VERSION ""

NS_ :

BS_:

BU_: Turbocharger OnBoardDataLogger OffBoardDiagnosticTool2 OffBoardDiagnosticTool1 FileServer ParkingBrakeController SeatControl2 FanDriveController SteeringColumnUnit CommunicationUnitRadio CommunicationUnitSatellite CommunicationUnitCellular PropulsionBatteryCharger ChassisController2 ChassisController1 EngineValveControl AuxiliaryHeater2 AuxiliaryHeater1 ClutchUnit RampControl InformationSystem1 SuspensionSystemController2 OilSensor VehicleDynamicStability ExhaustEmissionController TransmissionDisplay2 TransmissionDisplay1 ClimateControl2 WaterPumpController RearAxleSteeringController LightingOperatorControl SeatController1 IgnitionController2 IgnitionController1 TirePressureController CabController2 CabController1 PneumaticSystemController SuspensionSystemController1 HydraulicPumpController EnduranceBrakingSystem RetarderExhaustEngine2 OnBoardDiagnosticUnit HeadwayController RetarderExhaustEngine1 CabDisplay1 ManagementComputer VirtualTerminal OffVehicleGateway PowerTakeOffFront HitchControl AuxiliaryValveControl BodyController TractorTrailerBridge1 StarterSystem ElectricalSystem VehicleSecurity VehicleNavigation AerodynamicControl ElectricalChargingSystem ClimateControl1 TripRecorder InstrumentCluster SuspensionDriveAxle2 SuspensionDriveAxle1 SuspensionSteerAxle SteeringController FuelSystem CruiseControl RetarderDriveline RetarderEngine BrakesDriveAxle2 BrakesDriveAxle1 BrakesSystemController BrakesSteerAxle AxleDrive2 AxleDrive1 AxleSteering PowerTakeOff ShiftConsoleSecondary ShiftConsolePrimary Transmission2 Transmission1 Engine2 Engine1

BO_ 2561212158 DISP1: 8 Vector__XXX
 SG_ TextDisplayIndex : 16|8@1+ (1,0) [0|250] "" Vector__XXX
 SG_ TextDisplayInstructions : 0|4@1+ (1,0) [0|15] "" Vector__XXX

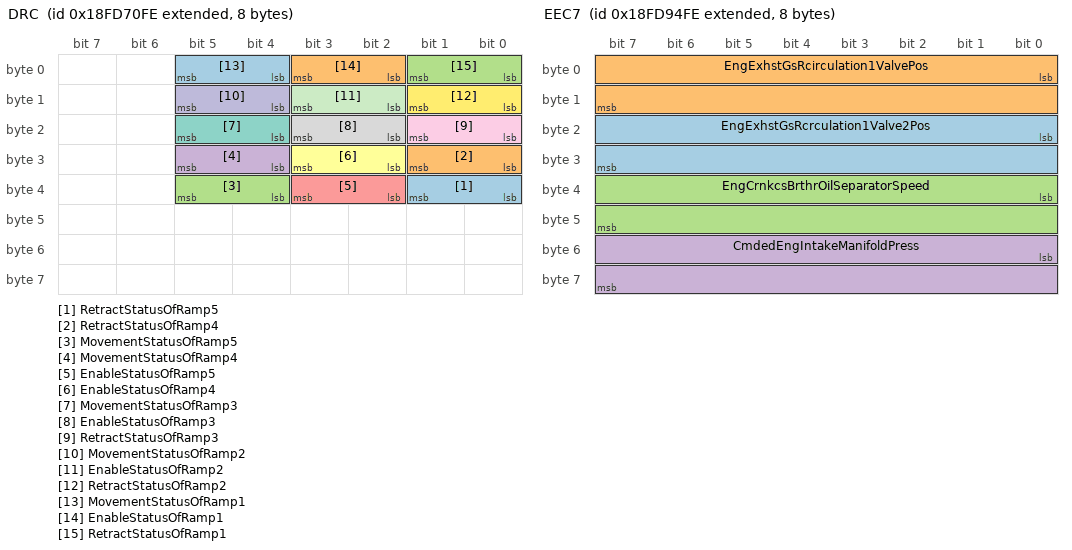
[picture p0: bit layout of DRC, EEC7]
BO_ 2566746366 DRC: 8 Vector__XXX
 SG_ RetractStatusOfRamp5 : 32|2@1+ (1,0) [0|3] "" Vector__XXX
 SG_ RetractStatusOfRamp4 : 24|2@1+ (1,0) [0|3] "" Vector__XXX
 SG_ MovementStatusOfRamp5 : 36|2@1+ (1,0) [0|3] "" Vector__XXX
 SG_ MovementStatusOfRamp4 : 28|2@1+ (1,0) [0|3] "" Vector__XXX
 SG_ EnableStatusOfRamp5 : 34|2@1+ (1,0) [0|3] "" Vector__XXX
 SG_ EnableStatusOfRamp4 : 26|2@1+ (1,0) [0|3] "" Vector__XXX
 SG_ MovementStatusOfRamp3 : 20|2@1+ (1,0) [0|3] "" Vector__XXX
 SG_ EnableStatusOfRamp3 : 18|2@1+ (1,0) [0|3] "" Vector__XXX
 SG_ RetractStatusOfRamp3 : 16|2@1+ (1,0) [0|3] "" Vector__XXX
 SG_ MovementStatusOfRamp2 : 12|2@1+ (1,0) [0|3] "" Vector__XXX
 SG_ EnableStatusOfRamp2 : 10|2@1+ (1,0) [0|3] "" Vector__XXX
 SG_ RetractStatusOfRamp2 : 8|2@1+ (1,0) [0|3] "" Vector__XXX
 SG_ MovementStatusOfRamp1 : 4|2@1+ (1,0) [0|3] "" Vector__XXX
 SG_ EnableStatusOfRamp1 : 2|2@1+ (1,0) [0|3] "" Vector__XXX
 SG_ RetractStatusOfRamp1 : 0|2@1+ (1,0) [0|3] "" Vector__XXX

BO_ 2566750206 EC2: 8 Vector__XXX
 SG_ MaxCrankAttemptsPerStartAttempt : 0|8@1+ (1,0) [0|250] "" Vector__XXX

BO_ 2566755582 EEC7: 8 Vector__XXX
 SG_ EngExhstGsRcrculation1Valve2Pos : 16|16@1+ (0.0025,0) [0|160.6375] "%" Vector__XXX
 SG_ EngExhstGsRcirculation1ValvePos : 0|16@1+ (0.0025,0) [0|160.6375] "%" Vector__XXX
 SG_ EngCrnkcsBrthrOilSeparatorSpeed : 32|16@1+ (1,0) [0|64255] "rpm" Vector__XXX
 SG_ CmdedEngIntakeManifoldPress : 48|16@1+ (0.125,0) [0|8031.875] "kPa" Vector__XXX

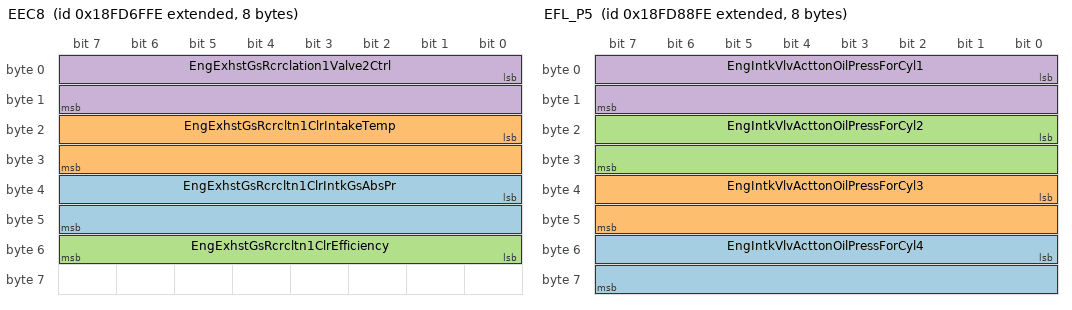
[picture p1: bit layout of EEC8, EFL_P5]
BO_ 2566746110 EEC8: 8 Vector__XXX
 SG_ EngExhstGsRcrcltn1ClrIntkGsAbsPr : 32|16@1+ (0.5,0) [0|32127.5] "kPa" Vector__XXX
 SG_ EngExhstGsRcrcltn1ClrIntakeTemp : 16|16@1+ (0.03125,-273) [-273|1734.96875] "deg C" Vector__XXX
 SG_ EngExhstGsRcrcltn1ClrEfficiency : 48|8@1+ (0.4,0) [0|100] "%" Vector__XXX
 SG_ EngExhstGsRcrclation1Valve2Ctrl : 0|16@1+ (0.0025,0) [0|160.6375] "%" Vector__XXX

BO_ 2566752510 EFL_P5: 8 Vector__XXX
 SG_ EngIntkVlvActtonOilPressForCyl4 : 48|16@1+ (0.1,0) [0|6425.5] "kPa" Vector__XXX
 SG_ EngIntkVlvActtonOilPressForCyl3 : 32|16@1+ (0.1,0) [0|6425.5] "kPa" Vector__XXX
 SG_ EngIntkVlvActtonOilPressForCyl2 : 16|16@1+ (0.1,0) [0|6425.5] "kPa" Vector__XXX
 SG_ EngIntkVlvActtonOilPressForCyl1 : 0|16@1+ (0.1,0) [0|6425.5] "kPa" Vector__XXX

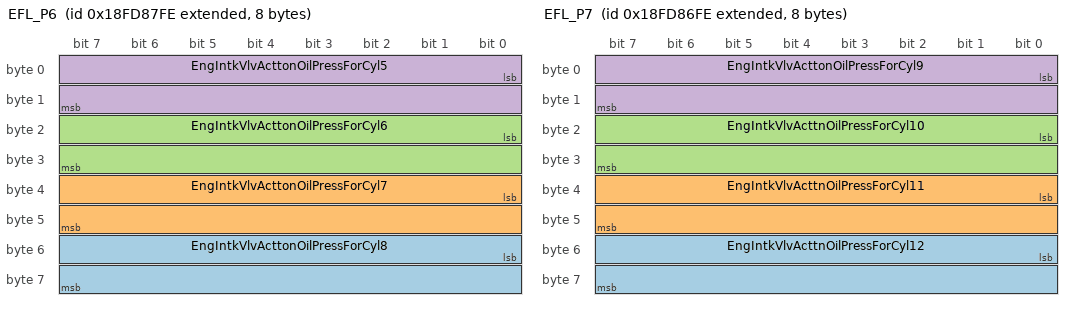
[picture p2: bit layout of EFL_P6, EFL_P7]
BO_ 2566752254 EFL_P6: 8 Vector__XXX
 SG_ EngIntkVlvActtonOilPressForCyl8 : 48|16@1+ (0.1,0) [0|6425.5] "kPa" Vector__XXX
 SG_ EngIntkVlvActtonOilPressForCyl7 : 32|16@1+ (0.1,0) [0|6425.5] "kPa" Vector__XXX
 SG_ EngIntkVlvActtonOilPressForCyl6 : 16|16@1+ (0.1,0) [0|6425.5] "kPa" Vector__XXX
 SG_ EngIntkVlvActtonOilPressForCyl5 : 0|16@1+ (0.1,0) [0|6425.5] "kPa" Vector__XXX

BO_ 2566751998 EFL_P7: 8 Vector__XXX
 SG_ EngIntkVlvActtnOilPressForCyl12 : 48|16@1+ (0.1,0) [0|6425.5] "kPa" Vector__XXX
 SG_ EngIntkVlvActtnOilPressForCyl11 : 32|16@1+ (0.1,0) [0|6425.5] "kPa" Vector__XXX
 SG_ EngIntkVlvActtnOilPressForCyl10 : 16|16@1+ (0.1,0) [0|6425.5] "kPa" Vector__XXX
 SG_ EngIntkVlvActtonOilPressForCyl9 : 0|16@1+ (0.1,0) [0|6425.5] "kPa" Vector__XXX

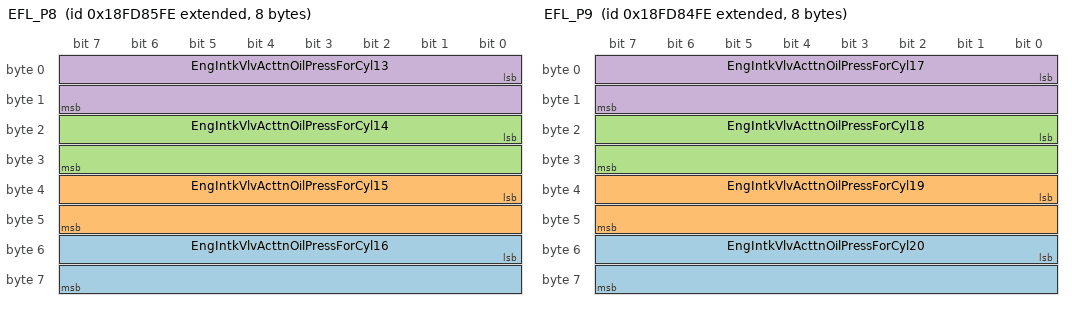
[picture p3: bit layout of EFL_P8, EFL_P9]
BO_ 2566751742 EFL_P8: 8 Vector__XXX
 SG_ EngIntkVlvActtnOilPressForCyl16 : 48|16@1+ (0.1,0) [0|6425.5] "kPa" Vector__XXX
 SG_ EngIntkVlvActtnOilPressForCyl15 : 32|16@1+ (0.1,0) [0|6425.5] "kPa" Vector__XXX
 SG_ EngIntkVlvActtnOilPressForCyl14 : 16|16@1+ (0.1,0) [0|6425.5] "kPa" Vector__XXX
 SG_ EngIntkVlvActtnOilPressForCyl13 : 0|16@1+ (0.1,0) [0|6425.5] "kPa" Vector__XXX

BO_ 2566751486 EFL_P9: 8 Vector__XXX
 SG_ EngIntkVlvActtnOilPressForCyl20 : 48|16@1+ (0.1,0) [0|6425.5] "kPa" Vector__XXX
 SG_ EngIntkVlvActtnOilPressForCyl19 : 32|16@1+ (0.1,0) [0|6425.5] "kPa" Vector__XXX
 SG_ EngIntkVlvActtnOilPressForCyl18 : 16|16@1+ (0.1,0) [0|6425.5] "kPa" Vector__XXX
 SG_ EngIntkVlvActtnOilPressForCyl17 : 0|16@1+ (0.1,0) [0|6425.5] "kPa" Vector__XXX

BO_ 2499641854 EGRBV: 8 Vector__XXX
 SG_ EGR1CoolerBypassActuatorPostion : 0|8@1+ (0.4,0) [0|100] "%" Vector__XXX

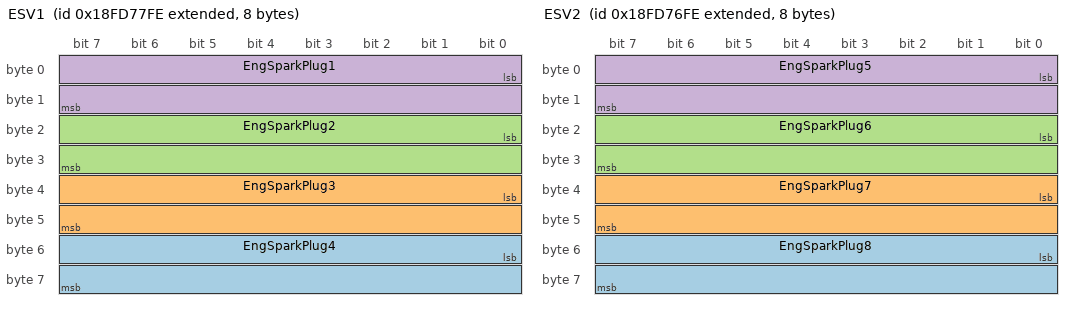
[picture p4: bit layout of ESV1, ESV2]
BO_ 2566748158 ESV1: 8 Vector__XXX
 SG_ EngSparkPlug4 : 48|16@1+ (1,0) [0|64255] "Volts" Vector__XXX
 SG_ EngSparkPlug3 : 32|16@1+ (1,0) [0|64255] "Volts" Vector__XXX
 SG_ EngSparkPlug2 : 16|16@1+ (1,0) [0|64255] "Volts" Vector__XXX
 SG_ EngSparkPlug1 : 0|16@1+ (1,0) [0|64255] "Volts" Vector__XXX

BO_ 2566747902 ESV2: 8 Vector__XXX
 SG_ EngSparkPlug8 : 48|16@1+ (1,0) [0|64255] "Volts" Vector__XXX
 SG_ EngSparkPlug7 : 32|16@1+ (1,0) [0|64255] "Volts" Vector__XXX
 SG_ EngSparkPlug6 : 16|16@1+ (1,0) [0|64255] "Volts" Vector__XXX
 SG_ EngSparkPlug5 : 0|16@1+ (1,0) [0|64255] "Volts" Vector__XXX

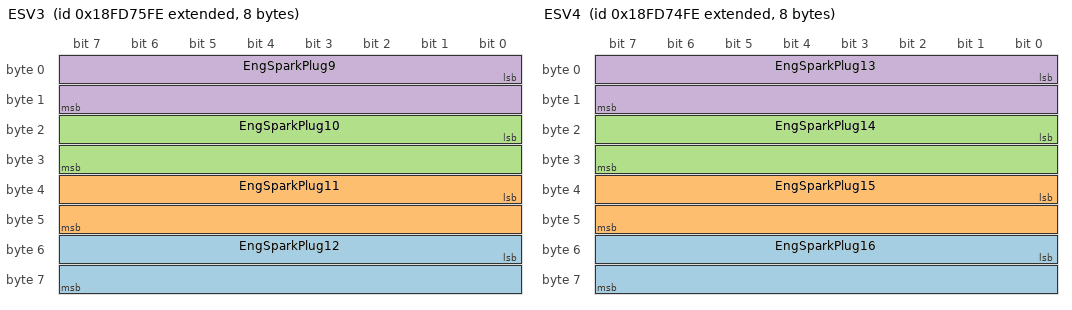
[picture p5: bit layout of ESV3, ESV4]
BO_ 2566747646 ESV3: 8 Vector__XXX
 SG_ EngSparkPlug12 : 48|16@1+ (1,0) [0|64255] "Volts" Vector__XXX
 SG_ EngSparkPlug11 : 32|16@1+ (1,0) [0|64255] "Volts" Vector__XXX
 SG_ EngSparkPlug10 : 16|16@1+ (1,0) [0|64255] "Volts" Vector__XXX
 SG_ EngSparkPlug9 : 0|16@1+ (1,0) [0|64255] "Volts" Vector__XXX

BO_ 2566747390 ESV4: 8 Vector__XXX
 SG_ EngSparkPlug16 : 48|16@1+ (1,0) [0|64255] "Volts" Vector__XXX
 SG_ EngSparkPlug15 : 32|16@1+ (1,0) [0|64255] "Volts" Vector__XXX
 SG_ EngSparkPlug14 : 16|16@1+ (1,0) [0|64255] "Volts" Vector__XXX
 SG_ EngSparkPlug13 : 0|16@1+ (1,0) [0|64255] "Volts" Vector__XXX

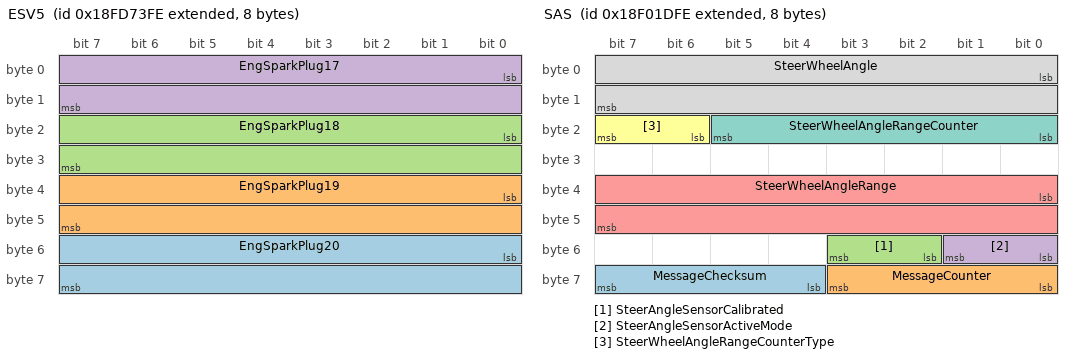
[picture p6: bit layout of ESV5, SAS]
BO_ 2566747134 ESV5: 8 Vector__XXX
 SG_ EngSparkPlug20 : 48|16@1+ (1,0) [0|64255] "Volts" Vector__XXX
 SG_ EngSparkPlug19 : 32|16@1+ (1,0) [0|64255] "Volts" Vector__XXX
 SG_ EngSparkPlug18 : 16|16@1+ (1,0) [0|64255] "Volts" Vector__XXX
 SG_ EngSparkPlug17 : 0|16@1+ (1,0) [0|64255] "Volts" Vector__XXX

BO_ 2566746878 ESV6: 8 Vector__XXX
 SG_ EngSparkPlug24 : 48|16@1+ (1,0) [0|64255] "Volts" Vector__XXX
 SG_ EngSparkPlug23 : 32|16@1+ (1,0) [0|64255] "Volts" Vector__XXX
 SG_ EngSparkPlug22 : 16|16@1+ (1,0) [0|64255] "Volts" Vector__XXX
 SG_ EngSparkPlug21 : 0|16@1+ (1,0) [0|64255] "Volts" Vector__XXX

BO_ 2561277694 FLIC: 8 Vector__XXX
 SG_ LaneDepartureWarningEnableCmd : 0|2@1+ (1,0) [0|3] "" Vector__XXX

BO_ 2633861886 J2012: 8 Vector__XXX
 SG_ J2012DTCOccurrenceCount : 49|7@1+ (1,0) [0|127] "" Vector__XXX
 SG_ J2012DTCStatus : 48|1@1+ (1,0) [0|1] "" Vector__XXX
 SG_ NumberOfJ2012DTCs : 0|8@1+ (1,0) [0|250] "" Vector__XXX

BO_ 2565873150 SAS: 8 Vector__XXX
 SG_ MessageChecksum : 60|4@1+ (1,0) [0|15] "" Vector__XXX
 SG_ MessageCounter : 56|4@1+ (1,0) [0|15] "" Vector__XXX
 SG_ SteerAngleSensorCalibrated : 50|2@1+ (1,0) [0|3] "" Vector__XXX
 SG_ SteerAngleSensorActiveMode : 48|2@1+ (1,0) [0|3] "" Vector__XXX
 SG_ SteerWheelAngleRange : 32|16@1+ (0.0009765625,-31.374) [-31.374|31.374] "rad" Vector__XXX
 SG_ SteerWheelAngleRangeCounterType : 22|2@1+ (1,0) [0|3] "" Vector__XXX
 SG_ SteerWheelAngleRangeCounter : 16|6@1+ (1,-32) [-32|29] "ranges" Vector__XXX
 SG_ SteerWheelAngle : 0|16@1+ (0.0009765625,-31.374) [-31.374|31.374] "rad" Vector__XXX

BO_ 2566745854 SCR1: 8 Vector__XXX
 SG_ Aftrtrtmnt1SCRCtlystCnvrsnEffcnc : 32|8@1+ (0.4,0) [0|100] "%" Vector__XXX
 SG_ Aftrtrtmnt1SCRCmddCtlystRgntCnsm : 16|16@1+ (0.05,0) [0|3212.75] "L/h" Vector__XXX
 SG_ Aftrtrtmnt1SCRAvrgCtlystRgntCnsm : 0|16@1+ (0.05,0) [0|3212.75] "L/h" Vector__XXX
 SG_ Aftrtrtmnt1DslExhstFldTnkLwLvlIn : 40|16@1+ (1,0) [0|64255] "km" Vector__XXX

BO_ 2566751230 TCI: 8 Vector__XXX
 SG_ TransferCaseStatus : 0|3@1+ (1,0) [0|7] "" Vector__XXX

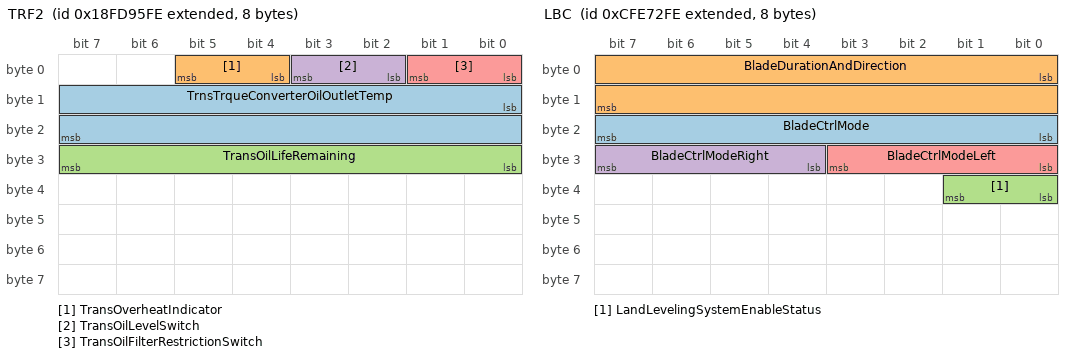
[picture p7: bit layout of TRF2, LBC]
BO_ 2566755838 TRF2: 8 Vector__XXX
 SG_ TrnsTrqueConverterOilOutletTemp : 8|16@1+ (0.03125,-273) [-273|1734.96875] "deg C" Vector__XXX
 SG_ TransOverheatIndicator : 4|2@1+ (1,0) [0|3] "" Vector__XXX
 SG_ TransOilLifeRemaining : 24|8@1+ (0.4,0) [0|100] "%" Vector__XXX
 SG_ TransOilLevelSwitch : 2|2@1+ (1,0) [0|3] "" Vector__XXX
 SG_ TransOilFilterRestrictionSwitch : 0|2@1+ (1,0) [0|3] "" Vector__XXX

BO_ 2566752766 VDS2: 8 Vector__XXX
 SG_ VehicleRoll : 0|16@1+ (0.0078125,-200) [-200|301.99] "deg" Vector__XXX

BO_ 2633938942 LF: 10 Vector__XXX
 SG_ TotalEngCruiseTime : 48|32@1+ (0.05,0) [0|210554060.75] "hr" Vector__XXX
 SG_ TotalDriveAverageLoadFactor : 40|8@1+ (0.4,0) [0|100] "%" Vector__XXX
 SG_ TripDriveAverageLoadFactor : 32|8@1+ (0.4,0) [0|100] "%" Vector__XXX
 SG_ TripAverageEngSpeed : 16|16@1+ (0.125,0) [0|8031.875] "rpm" Vector__XXX
 SG_ TripMaxEngSpeed : 0|16@1+ (0.125,0) [0|8031.875] "rpm" Vector__XXX

BO_ 2566799614 LD: 8 Vector__XXX
 SG_ ImplementRearWorkLight : 62|2@1+ (1,0) [0|3] "" Vector__XXX
 SG_ ImplementLeftForwardWorkLight : 60|2@1+ (1,0) [0|3] "" Vector__XXX
 SG_ ImplementRightForwardWorkLight : 58|2@1+ (1,0) [0|3] "" Vector__XXX
 SG_ ImplementLeftFacingWorkLight : 54|2@1+ (1,0) [0|3] "" Vector__XXX
 SG_ ImplementRightFacingWorkLight : 52|2@1+ (1,0) [0|3] "" Vector__XXX
 SG_ ImplementOEMOption1Light : 50|2@1+ (1,0) [0|3] "" Vector__XXX
 SG_ ImplementOEMOption2Light : 48|2@1+ (1,0) [0|3] "" Vector__XXX
 SG_ TrctrFrontHighMountedWorkLights : 46|2@1+ (1,0) [0|3] "" Vector__XXX
 SG_ TrctorFrontLowMountedWorkLights : 44|2@1+ (1,0) [0|3] "" Vector__XXX
 SG_ TrctorSideHighMountedWorkLights : 42|2@1+ (1,0) [0|3] "" Vector__XXX
 SG_ TractorSideLowMountedWorkLights : 40|2@1+ (1,0) [0|3] "" Vector__XXX
 SG_ TrctorRearHighMountedWorkLights : 38|2@1+ (1,0) [0|3] "" Vector__XXX
 SG_ TractorRearLowMountedWorkLights : 36|2@1+ (1,0) [0|3] "" Vector__XXX
 SG_ TrctrUndersideMountedWorkLights : 34|2@1+ (1,0) [0|3] "" Vector__XXX
 SG_ RearFogLights : 32|2@1+ (1,0) [0|3] "" Vector__XXX
 SG_ TractorMarkerLight : 30|2@1+ (1,0) [0|3] "" Vector__XXX
 SG_ ImplementMarkerLight : 28|2@1+ (1,0) [0|3] "" Vector__XXX
 SG_ TractorClearanceLight : 26|2@1+ (1,0) [0|3] "" Vector__XXX
 SG_ ImplementClearanceLight : 24|2@1+ (1,0) [0|3] "" Vector__XXX
 SG_ LeftStopLight : 22|2@1+ (1,0) [0|3] "" Vector__XXX
 SG_ RightStopLight : 20|2@1+ (1,0) [0|3] "" Vector__XXX
 SG_ CenterStopLight : 18|2@1+ (1,0) [0|3] "" Vector__XXX
 SG_ BackUpLightAndAlarmHorn : 16|2@1+ (1,0) [0|3] "" Vector__XXX
 SG_ LeftTurnSignalLights : 14|2@1+ (1,0) [0|3] "" Vector__XXX
 SG_ RightTurnSignalLights : 12|2@1+ (1,0) [0|3] "" Vector__XXX
 SG_ RotatingBeaconLight : 10|2@1+ (1,0) [0|3] "" Vector__XXX
 SG_ TractorFrontFogLights : 8|2@1+ (1,0) [0|3] "" Vector__XXX
 SG_ HighBeamHeadLightData : 6|2@1+ (1,0) [0|3] "" Vector__XXX
 SG_ LowBeamHeadLightData : 4|2@1+ (1,0) [0|3] "" Vector__XXX
 SG_ AltBeamHeadLightData : 2|2@1+ (1,0) [0|3] "" Vector__XXX
 SG_ RunningLight : 0|2@1+ (1,0) [0|3] "" Vector__XXX

BO_ 2365473278 LC: 8 Vector__XXX
 SG_ ImplementRearWorkLightCmd : 62|2@1+ (1,0) [0|3] "" Vector__XXX
 SG_ ImplmentLeftForwardWorkLightCmd : 60|2@1+ (1,0) [0|3] "" Vector__XXX
 SG_ ImplmntRightForwardWorkLightCmd : 58|2@1+ (1,0) [0|3] "" Vector__XXX
 SG_ LightingDataRqCmd : 56|2@1+ (1,0) [0|3] "" Vector__XXX
 SG_ ImplementLeftFacingWorkLightCmd : 54|2@1+ (1,0) [0|3] "" Vector__XXX
 SG_ ImplmentRightFacingWorkLightCmd : 52|2@1+ (1,0) [0|3] "" Vector__XXX
 SG_ ImplementOEMOption1LightCmd : 50|2@1+ (1,0) [0|3] "" Vector__XXX
 SG_ ImplementOEMOption2LightCmd : 48|2@1+ (1,0) [0|3] "" Vector__XXX
 SG_ TrctrFrntHghMuntedWorkLightsCmd : 46|2@1+ (1,0) [0|3] "" Vector__XXX
 SG_ TrctrFrntLwMountedWorkLightsCmd : 44|2@1+ (1,0) [0|3] "" Vector__XXX
 SG_ TrctrSdHighMountedWorkLightsCmd : 42|2@1+ (1,0) [0|3] "" Vector__XXX
 SG_ TrctrSdeLowMountedWorkLightsCmd : 40|2@1+ (1,0) [0|3] "" Vector__XXX
 SG_ TrctrRrHighMountedWorkLightsCmd : 38|2@1+ (1,0) [0|3] "" Vector__XXX
 SG_ TrctrRarLowMountedWorkLightsCmd : 36|2@1+ (1,0) [0|3] "" Vector__XXX
 SG_ TrctrUndrsdMountedWorkLightsCmd : 34|2@1+ (1,0) [0|3] "" Vector__XXX
 SG_ RearFogLightCmd : 32|2@1+ (1,0) [0|3] "" Vector__XXX
 SG_ TractorMarkerLightCmd : 30|2@1+ (1,0) [0|3] "" Vector__XXX
 SG_ ImplementMarkerLightCmd : 28|2@1+ (1,0) [0|3] "" Vector__XXX
 SG_ TractorClearanceLightCmd : 26|2@1+ (1,0) [0|3] "" Vector__XXX
 SG_ ImplementClearanceLightCmd : 24|2@1+ (1,0) [0|3] "" Vector__XXX
 SG_ LeftStopLightCmd : 22|2@1+ (1,0) [0|3] "" Vector__XXX
 SG_ RightStopLightCmd : 20|2@1+ (1,0) [0|3] "" Vector__XXX
 SG_ CenterStopLightCmd : 18|2@1+ (1,0) [0|3] "" Vector__XXX
 SG_ BackUpLightAndAlarmHornCmd : 16|2@1+ (1,0) [0|3] "" Vector__XXX
 SG_ LeftTurnSignalLightsCmd : 14|2@1+ (1,0) [0|3] "" Vector__XXX
 SG_ RightTurnSignalLightsCmd : 12|2@1+ (1,0) [0|3] "" Vector__XXX
 SG_ RotatingBeaconLightCmd : 10|2@1+ (1,0) [0|3] "" Vector__XXX
 SG_ TractorFrontFogLightsCmd : 8|2@1+ (1,0) [0|3] "" Vector__XXX
 SG_ HighBeamHeadLightCmd : 6|2@1+ (1,0) [0|3] "" Vector__XXX
 SG_ LowBeamHeadLightCmd : 4|2@1+ (1,0) [0|3] "" Vector__XXX
 SG_ AltBeamHeadLightCmd : 2|2@1+ (1,0) [0|3] "" Vector__XXX
 SG_ RunningLightCmd : 0|2@1+ (1,0) [0|3] "" Vector__XXX

BO_ 2365485822 LBC: 8 Vector__XXX
 SG_ BladeCtrlMode : 16|8@1+ (1,0) [0|255] "" Vector__XXX
 SG_ BladeDurationAndDirection : 0|16@1+ (0.1,-3276.8) [-3276.8|3148.7] "sec" Vector__XXX
 SG_ LandLevelingSystemEnableStatus : 32|2@1+ (1,0) [0|3] "" Vector__XXX
 SG_ BladeCtrlModeRight : 28|4@1+ (1,0) [0|15] "" Vector__XXX
 SG_ BladeCtrlModeLeft : 24|4@1+ (1,0) [0|15] "" Vector__XXX

BO_ 2633926654 IT6: 8 Vector__XXX
 SG_ EngActualIgntTiming : 48|16@1+ (0.0078125,-200) [-200|301.99] "deg" Vector__XXX
 SG_ EngDesiredIgntTiming3 : 32|16@1+ (0.0078125,-200) [-200|301.99] "deg" Vector__XXX
 SG_ EngDesiredIgntTiming2 : 16|16@1+ (0.0078125,-200) [-200|301.99] "deg" Vector__XXX
 SG_ EngDesiredIgntTiming1 : 0|16@1+ (0.0078125,-200) [-200|301.99] "deg" Vector__XXX

BO_ 2633926398 IT5: 8 Vector__XXX
 SG_ EngCyl20IgntTiming : 48|16@1+ (0.0078125,-200) [-200|301.99] "deg" Vector__XXX
 SG_ EngCyl19IgntTiming : 32|16@1+ (0.0078125,-200) [-200|301.99] "deg" Vector__XXX
 SG_ EngCyl18IgntTiming : 16|16@1+ (0.0078125,-200) [-200|301.99] "deg" Vector__XXX
 SG_ EngCyl17IgntTiming : 0|16@1+ (0.0078125,-200) [-200|301.99] "deg" Vector__XXX

BO_ 2633926142 IT4: 8 Vector__XXX
 SG_ EngCyl16IgntTiming : 48|16@1+ (0.0078125,-200) [-200|301.99] "deg" Vector__XXX
 SG_ EngCyl15IgntTiming : 32|16@1+ (0.0078125,-200) [-200|301.99] "deg" Vector__XXX
 SG_ EngCyl14IgntTiming : 16|16@1+ (0.0078125,-200) [-200|301.99] "deg" Vector__XXX
 SG_ EngCyl13IgntTiming : 0|16@1+ (0.0078125,-200) [-200|301.99] "deg" Vector__XXX

BO_ 2633925886 IT3: 8 Vector__XXX
 SG_ EngCyl12IgntTiming : 48|16@1+ (0.0078125,-200) [-200|301.99] "deg" Vector__XXX
 SG_ EngCyl11IgntTiming : 32|16@1+ (0.0078125,-200) [-200|301.99] "deg" Vector__XXX
 SG_ EngCyl10IgntTiming : 16|16@1+ (0.0078125,-200) [-200|301.99] "deg" Vector__XXX
 SG_ EngCyl9IgntTiming : 0|16@1+ (0.0078125,-200) [-200|301.99] "deg" Vector__XXX

BO_ 2633925630 IT2: 8 Vector__XXX
 SG_ EngCyl8IgntTiming : 48|16@1+ (0.0078125,-200) [-200|301.99] "deg" Vector__XXX
 SG_ EngCyl7IgntTiming : 32|16@1+ (0.0078125,-200) [-200|301.99] "deg" Vector__XXX
 SG_ EngCyl6IgntTiming : 16|16@1+ (0.0078125,-200) [-200|301.99] "deg" Vector__XXX
 SG_ EngCyl5IgntTiming : 0|16@1+ (0.0078125,-200) [-200|301.99] "deg" Vector__XXX

BO_ 2633925374 IT1: 8 Vector__XXX
 SG_ EngCyl4IgntTiming : 48|16@1+ (0.0078125,-200) [-200|301.99] "deg" Vector__XXX
 SG_ EngCyl3IgntTiming : 32|16@1+ (0.0078125,-200) [-200|301.99] "deg" Vector__XXX
 SG_ EngCyl2IgntTiming : 16|16@1+ (0.0078125,-200) [-200|301.99] "deg" Vector__XXX
 SG_ EngCyl1IgntTiming : 0|16@1+ (0.0078125,-200) [-200|301.99] "deg" Vector__XXX

BO_ 2633927422 ISO3: 8 Vector__XXX
 SG_ EngCyl20IgntTransSecondOutput : 24|8@1+ (1,-125) [-125|125] "%" Vector__XXX
 SG_ EngCyl19IgntTransSecondOutput : 16|8@1+ (1,-125) [-125|125] "%" Vector__XXX
 SG_ EngCyl18IgntTransSecondOutput : 8|8@1+ (1,-125) [-125|125] "%" Vector__XXX
 SG_ EngCyl17IgntTransSecondOutput : 0|8@1+ (1,-125) [-125|125] "%" Vector__XXX

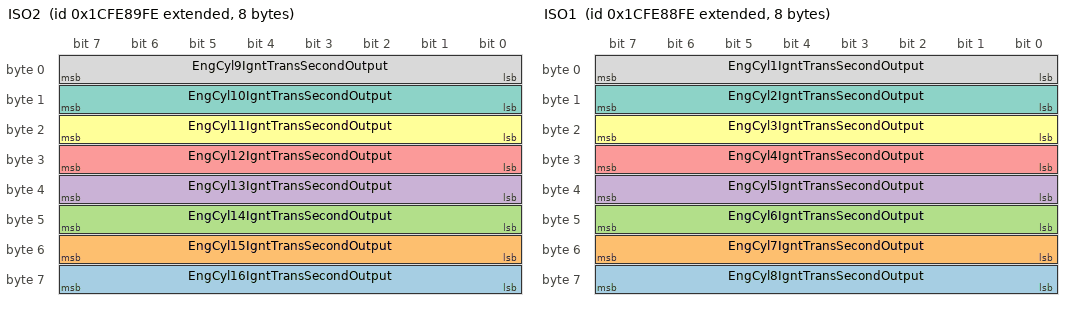
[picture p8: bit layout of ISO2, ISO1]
BO_ 2633927166 ISO2: 8 Vector__XXX
 SG_ EngCyl16IgntTransSecondOutput : 56|8@1+ (1,-125) [-125|125] "%" Vector__XXX
 SG_ EngCyl15IgntTransSecondOutput : 48|8@1+ (1,-125) [-125|125] "%" Vector__XXX
 SG_ EngCyl14IgntTransSecondOutput : 40|8@1+ (1,-125) [-125|125] "%" Vector__XXX
 SG_ EngCyl13IgntTransSecondOutput : 32|8@1+ (1,-125) [-125|125] "%" Vector__XXX
 SG_ EngCyl12IgntTransSecondOutput : 24|8@1+ (1,-125) [-125|125] "%" Vector__XXX
 SG_ EngCyl11IgntTransSecondOutput : 16|8@1+ (1,-125) [-125|125] "%" Vector__XXX
 SG_ EngCyl10IgntTransSecondOutput : 8|8@1+ (1,-125) [-125|125] "%" Vector__XXX
 SG_ EngCyl9IgntTransSecondOutput : 0|8@1+ (1,-125) [-125|125] "%" Vector__XXX

BO_ 2633926910 ISO1: 8 Vector__XXX
 SG_ EngCyl8IgntTransSecondOutput : 56|8@1+ (1,-125) [-125|125] "%" Vector__XXX
 SG_ EngCyl7IgntTransSecondOutput : 48|8@1+ (1,-125) [-125|125] "%" Vector__XXX
 SG_ EngCyl6IgntTransSecondOutput : 40|8@1+ (1,-125) [-125|125] "%" Vector__XXX
 SG_ EngCyl5IgntTransSecondOutput : 32|8@1+ (1,-125) [-125|125] "%" Vector__XXX
 SG_ EngCyl4IgntTransSecondOutput : 24|8@1+ (1,-125) [-125|125] "%" Vector__XXX
 SG_ EngCyl3IgntTransSecondOutput : 16|8@1+ (1,-125) [-125|125] "%" Vector__XXX
 SG_ EngCyl2IgntTransSecondOutput : 8|8@1+ (1,-125) [-125|125] "%" Vector__XXX
 SG_ EngCyl1IgntTransSecondOutput : 0|8@1+ (1,-125) [-125|125] "%" Vector__XXX

BO_ 2566768894 ISCS: 8 Vector__XXX
 SG_ EngOprtrPrmryIntrmdtSpdSlctStte : 0|4@1+ (1,0) [0|15] "" Vector__XXX

BO_ 2566769406 ISC: 8 Vector__XXX
 SG_ EngOprtrPrmryIntrmdtSpeedSelect : 0|4@1+ (1,0) [0|15] "" Vector__XXX

BO_ 2566839550 IO: 8 Vector__XXX
 SG_ EngTotalIdleHours : 32|32@1+ (0.05,0) [0|210554060.75] "hr" Vector__XXX
 SG_ EngTotalIdleFuelUsed : 0|32@1+ (0.5,0) [0|2105540607.5] "L" Vector__XXX

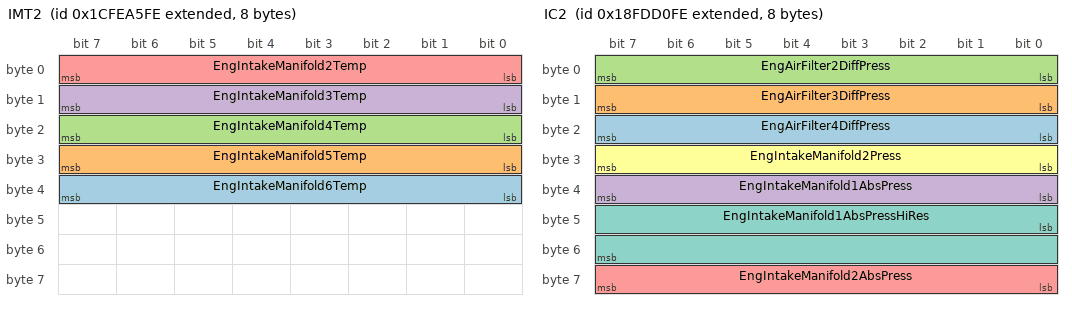
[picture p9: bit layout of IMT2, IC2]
BO_ 2633934334 IMT2: 8 Vector__XXX
 SG_ EngIntakeManifold6Temp : 32|8@1+ (1,-40) [-40|210] "deg C" Vector__XXX
 SG_ EngIntakeManifold5Temp : 24|8@1+ (1,-40) [-40|210] "deg C" Vector__XXX
 SG_ EngIntakeManifold4Temp : 16|8@1+ (1,-40) [-40|210] "deg C" Vector__XXX
 SG_ EngIntakeManifold3Temp : 8|8@1+ (1,-40) [-40|210] "deg C" Vector__XXX
 SG_ EngIntakeManifold2Temp : 0|8@1+ (1,-40) [-40|210] "deg C" Vector__XXX

BO_ 2566825726 IMT1: 8 Vector__XXX
 SG_ EngTurbo4BoostPress : 48|16@1+ (0.125,0) [0|8031.875] "kPa" Vector__XXX
 SG_ EngTurbo3BoostPress : 32|16@1+ (0.125,0) [0|8031.875] "kPa" Vector__XXX
 SG_ EngTurbo2BoostPress : 16|16@1+ (0.125,0) [0|8031.875] "kPa" Vector__XXX
 SG_ EngTurbo1BoostPress : 0|16@1+ (0.125,0) [0|8031.875] "kPa" Vector__XXX

BO_ 2566770942 IC2: 8 Vector__XXX
 SG_ EngAirFilter4DiffPress : 16|8@1+ (0.05,0) [0|12.5] "kPa" Vector__XXX
 SG_ EngAirFilter3DiffPress : 8|8@1+ (0.05,0) [0|12.5] "kPa" Vector__XXX
 SG_ EngAirFilter2DiffPress : 0|8@1+ (0.05,0) [0|12.5] "kPa" Vector__XXX
 SG_ EngIntakeManifold1AbsPress : 32|8@1+ (0.1,0) [0|25.5] "kPa" Vector__XXX
 SG_ EngIntakeManifold2AbsPress : 56|8@1+ (2,0) [0|500] "kPa" Vector__XXX
 SG_ EngIntakeManifold2Press : 24|8@1+ (2,0) [0|500] "kPa" Vector__XXX
 SG_ EngIntakeManifold1AbsPressHiRes : 40|16@1+ (0.1,0) [0|6425.5] "kPa" Vector__XXX

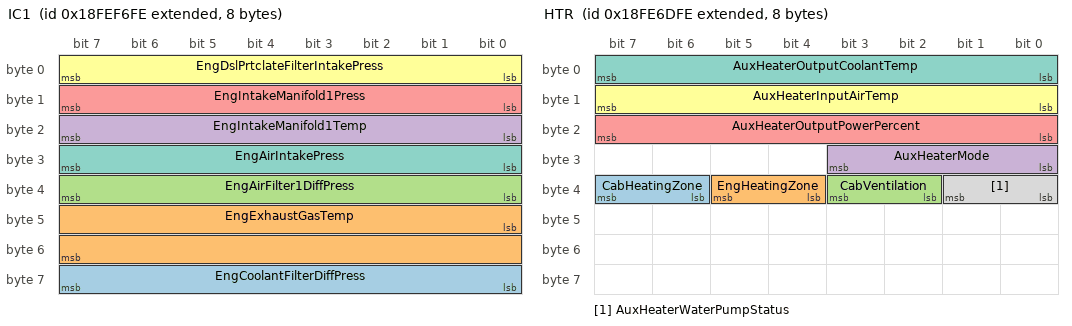
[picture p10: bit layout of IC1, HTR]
BO_ 2566846206 IC1: 8 Vector__XXX
 SG_ EngCoolantFilterDiffPress : 56|8@1+ (0.5,0) [0|125] "kPa" Vector__XXX
 SG_ EngExhaustGasTemp : 40|16@1+ (0.03125,-273) [-273|1734.96875] "deg C" Vector__XXX
 SG_ EngAirFilter1DiffPress : 32|8@1+ (0.05,0) [0|12.5] "kPa" Vector__XXX
 SG_ EngIntakeManifold1Temp : 16|8@1+ (1,-40) [-40|210] "deg C" Vector__XXX
 SG_ EngIntakeManifold1Press : 8|8@1+ (2,0) [0|500] "kPa" Vector__XXX
 SG_ EngDslPrtclateFilterIntakePress : 0|8@1+ (0.5,0) [0|125] "kPa" Vector__XXX
 SG_ EngAirIntakePress : 24|8@1+ (2,0) [0|500] "kPa" Vector__XXX

BO_ 2566811134 HTR: 8 Vector__XXX
 SG_ CabHeatingZone : 38|2@1+ (1,0) [0|3] "" Vector__XXX
 SG_ EngHeatingZone : 36|2@1+ (1,0) [0|3] "" Vector__XXX
 SG_ CabVentilation : 34|2@1+ (1,0) [0|3] "" Vector__XXX
 SG_ AuxHeaterMode : 24|4@1+ (1,0) [0|15] "" Vector__XXX
 SG_ AuxHeaterOutputPowerPercent : 16|8@1+ (0.4,0) [0|100] "%" Vector__XXX
 SG_ AuxHeaterInputAirTemp : 8|8@1+ (1,-40) [-40|210] "deg C" Vector__XXX
 SG_ AuxHeaterOutputCoolantTemp : 0|8@1+ (1,-40) [-40|210] "deg C" Vector__XXX
 SG_ AuxHeaterWaterPumpStatus : 32|2@1+ (1,0) [0|3] "" Vector__XXX

BO_ 2298375934 HRW: 8 Vector__XXX
 SG_ RearAxleRightWheelSpeed : 48|16@1+ (0.00390625,0) [0|250.996] "km/h" Vector__XXX
 SG_ RearAxleLeftWheelSpeed : 32|16@1+ (0.00390625,0) [0|250.996] "km/h" Vector__XXX
 SG_ FrontAxleRightWheelSpeed : 16|16@1+ (0.00390625,0) [0|250.996] "km/h" Vector__XXX
 SG_ FrontAxleLeftWheelSpeed : 0|16@1+ (0.00390625,0) [0|250.996] "km/h" Vector__XXX

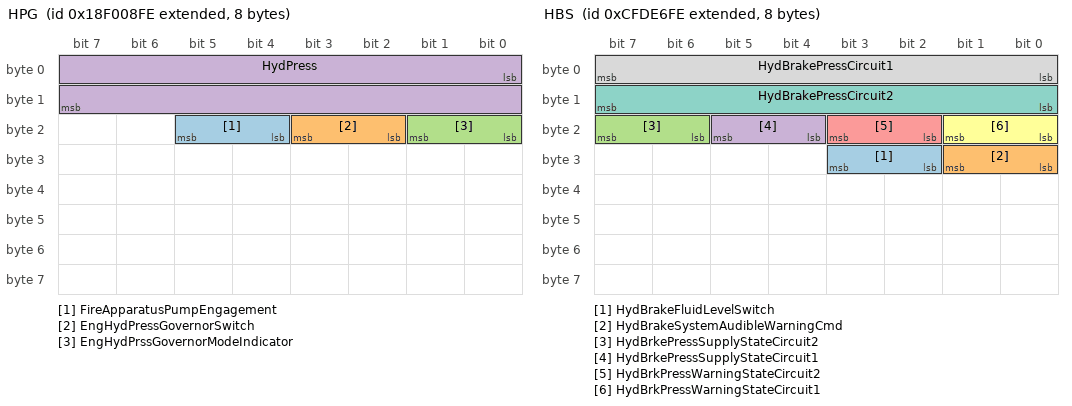
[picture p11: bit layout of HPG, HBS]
BO_ 2565867774 HPG: 8 Vector__XXX
 SG_ FireApparatusPumpEngagement : 20|2@1+ (1,0) [0|3] "" Vector__XXX
 SG_ EngHydPressGovernorSwitch : 18|2@1+ (1,0) [0|3] "" Vector__XXX
 SG_ EngHydPrssGovernorModeIndicator : 16|2@1+ (1,0) [0|3] "" Vector__XXX
 SG_ HydPress : 0|16@1+ (2,0) [0|128510] "kPa" Vector__XXX

BO_ 2566841854 HOURS: 8 Vector__XXX
 SG_ EngTotalRevolutions : 32|32@1+ (1000,0) [0|4211081215000] "r" Vector__XXX
 SG_ EngTotalHoursOfOperation : 0|32@1+ (0.05,0) [0|210554060.75] "hr" Vector__XXX

BO_ 2365449982 HBS: 8 Vector__XXX
 SG_ HydBrakeFluidLevelSwitch : 26|2@1+ (1,0) [0|3] "" Vector__XXX
 SG_ HydBrakeSystemAudibleWarningCmd : 24|2@1+ (1,0) [0|3] "" Vector__XXX
 SG_ HydBrkePressSupplyStateCircuit2 : 22|2@1+ (1,0) [0|3] "" Vector__XXX
 SG_ HydBrkePressSupplyStateCircuit1 : 20|2@1+ (1,0) [0|3] "" Vector__XXX
 SG_ HydBrkPressWarningStateCircuit2 : 18|2@1+ (1,0) [0|3] "" Vector__XXX
 SG_ HydBrkPressWarningStateCircuit1 : 16|2@1+ (1,0) [0|3] "" Vector__XXX
 SG_ HydBrakePressCircuit2 : 8|8@1+ (100,0) [0|25] "MPa" Vector__XXX
 SG_ HydBrakePressCircuit1 : 0|8@1+ (100,0) [0|25] "MPa" Vector__XXX

BO_ 2633939198 GTFI: 22 Vector__XXX
 SG_ TripDriveFuelEconomy : 160|16@1+ (0.001953125,0) [0|125.5] "km/kg" Vector__XXX
 SG_ TrpPTOGovernorNonmovingFuelUsed : 64|32@1+ (0.5,0) [0|2105540607.5] "kg" Vector__XXX
 SG_ TripVehicleIdleFuelUsed : 96|32@1+ (0.5,0) [0|2105540607.5] "kg" Vector__XXX
 SG_ TripCruiseFuelUsed : 128|32@1+ (0.5,0) [0|2105540607.5] "kg" Vector__XXX
 SG_ TripDriveFuelUsed : 0|32@1+ (0.5,0) [0|2105540607.5] "kg" Vector__XXX
 SG_ TripPTOGovernorMovingFuelUsed : 32|32@1+ (0.5,0) [0|2105540607.5] "kg" Vector__XXX

BO_ 2633927678 GFP: 8 Vector__XXX
 SG_ EngFuelValve1OutletAbsPress : 48|16@1+ (0.1,0) [0|6425.5] "kPa" Vector__XXX
 SG_ EngAirToFuelDiffPress : 32|16@1+ (0.1,0) [0|6425.5] "kPa" Vector__XXX
 SG_ EngFuelValveDiffPress : 16|16@1+ (0.1,0) [0|6425.5] "kPa" Vector__XXX
 SG_ EngFuelValve1IntakeAbsPress : 0|16@1+ (0.1,0) [0|6425.5] "kPa" Vector__XXX

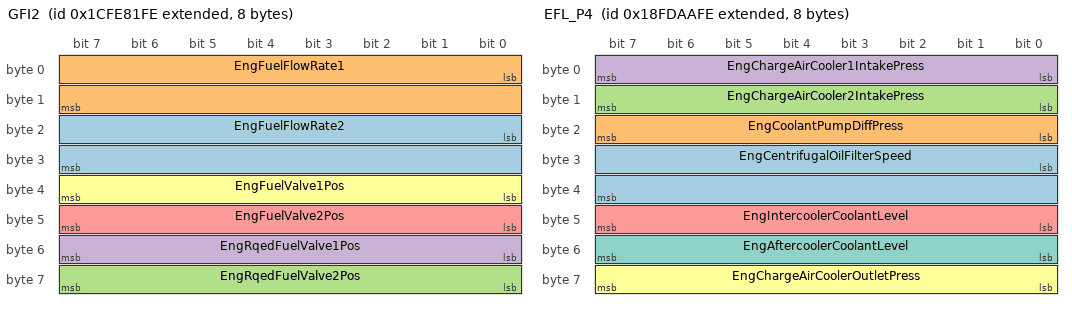
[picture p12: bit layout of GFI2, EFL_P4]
BO_ 2633925118 GFI2: 8 Vector__XXX
 SG_ EngFuelFlowRate2 : 16|16@1+ (0.1,0) [0|6425.5] "(m*m*m)/h" Vector__XXX
 SG_ EngFuelFlowRate1 : 0|16@1+ (0.1,0) [0|6425.5] "(m*m*m)/h" Vector__XXX
 SG_ EngRqedFuelValve2Pos : 56|8@1+ (0.4,0) [0|100] "%" Vector__XXX
 SG_ EngRqedFuelValve1Pos : 48|8@1+ (0.4,0) [0|100] "%" Vector__XXX
 SG_ EngFuelValve2Pos : 40|8@1+ (0.4,0) [0|100] "%" Vector__XXX
 SG_ EngFuelValve1Pos : 32|8@1+ (0.4,0) [0|100] "%" Vector__XXX

BO_ 2633937662 GFI1: 8 Vector__XXX
 SG_ TotalEngPTOGovernorFuelUsed : 0|32@1+ (0.5,0) [0|2105540607.5] "kg" Vector__XXX
 SG_ TripAverageFuelRate : 32|16@1+ (0.05,0) [0|3212.75] "kg/h" Vector__XXX
 SG_ EngFuelSpecificGravity : 48|16@1+ (0.0001,0) [0|6.4255] "" Vector__XXX

BO_ 2566804990 GFD: 8 Vector__XXX
 SG_ SpecificHeatRatio : 0|16@1+ (0.001,0) [0|64.255] "" Vector__XXX

BO_ 2633936894 GFC: 8 Vector__XXX
 SG_ TotalFuelUsed : 32|32@1+ (0.5,0) [0|2105540607.5] "kg" Vector__XXX
 SG_ TripFuel : 0|32@1+ (0.5,0) [0|2105540607.5] "kg" Vector__XXX

BO_ 2566757630 SEP2: 8 Vector__XXX
 SG_ SensorSupplyVoltage6 : 16|16@1+ (0.05,0) [0|3212.75] "V" Vector__XXX
 SG_ SensorSupplyVoltage5 : 0|16@1+ (0.05,0) [0|3212.75] "V" Vector__XXX
 SG_ SensorSupplyVoltage8 : 48|16@1+ (0.05,0) [0|3212.75] "V" Vector__XXX
 SG_ SensorSupplyVoltage7 : 32|16@1+ (0.05,0) [0|3212.75] "V" Vector__XXX

BO_ 2566757886 SEP1: 8 Vector__XXX
 SG_ SensorSupplyVoltage4 : 48|16@1+ (0.05,0) [0|3212.75] "V" Vector__XXX
 SG_ SensorSupplyVoltage3 : 32|16@1+ (0.05,0) [0|3212.75] "V" Vector__XXX
 SG_ SensorSupplyVoltage2 : 16|16@1+ (0.05,0) [0|3212.75] "V" Vector__XXX
 SG_ SensorSupplyVoltage1 : 0|16@1+ (0.05,0) [0|3212.75] "V" Vector__XXX

BO_ 2566759678 PTODE: 8 Vector__XXX
 SG_ EnggmntSttusTransInputShaftPTO1 : 38|2@1+ (1,0) [0|3] "" Vector__XXX
 SG_ EnggmntSttusTransInputShaftPTO2 : 36|2@1+ (1,0) [0|3] "" Vector__XXX
 SG_ EnggmntSttusTransOutputShaftPTO : 34|2@1+ (1,0) [0|3] "" Vector__XXX
 SG_ EnggmntSttsTrnsfrCsOtptShaftPTO : 32|2@1+ (1,0) [0|3] "" Vector__XXX
 SG_ EnggmntCnsntTransInputShaftPTO1 : 22|2@1+ (1,0) [0|3] "" Vector__XXX
 SG_ EnggmntCnsntTransInputShaftPTO2 : 20|2@1+ (1,0) [0|3] "" Vector__XXX
 SG_ EnggmntCnsntTransOutputShaftPTO : 18|2@1+ (1,0) [0|3] "" Vector__XXX
 SG_ EnggmntCnsntTrnsfrCsOtptShftPTO : 16|2@1+ (1,0) [0|3] "" Vector__XXX
 SG_ EnableSwitchTransInputShaftPTO1 : 6|2@1+ (1,0) [0|3] "" Vector__XXX
 SG_ EnableSwitchTransInputShaftPTO2 : 4|2@1+ (1,0) [0|3] "" Vector__XXX
 SG_ EnableSwitchTransOutputShaftPTO : 2|2@1+ (1,0) [0|3] "" Vector__XXX
 SG_ EnblSwtchTrnsfrCsOutputShaftPTO : 0|2@1+ (1,0) [0|3] "" Vector__XXX
 SG_ EnggmntSttsPTOEngAccssoryDrive2 : 44|2@1+ (1,0) [0|3] "" Vector__XXX
 SG_ EnggmntSttsPTOEngAccssoryDrive1 : 42|2@1+ (1,0) [0|3] "" Vector__XXX
 SG_ EnggmntCnsntPTOEngAccssryDrive2 : 28|2@1+ (1,0) [0|3] "" Vector__XXX
 SG_ EnggmntCnsntPTOEngAccssryDrive1 : 26|2@1+ (1,0) [0|3] "" Vector__XXX
 SG_ EngagementStatusPTOEngFlywheel : 40|2@1+ (1,0) [0|3] "" Vector__XXX
 SG_ EngagementConsentPTOEngFlywheel : 24|2@1+ (1,0) [0|3] "" Vector__XXX
 SG_ EnblSwitchPTOEngAccessoryDrive2 : 12|2@1+ (1,0) [0|3] "" Vector__XXX
 SG_ EnblSwitchPTOEngAccessoryDrive1 : 10|2@1+ (1,0) [0|3] "" Vector__XXX
 SG_ EnableSwitchPTOEngFlywheel : 8|2@1+ (1,0) [0|3] "" Vector__XXX
 SG_ AtLeastOnePTOEngaged : 48|2@1+ (1,0) [0|3] "" Vector__XXX

BO_ 2432541438 GFI3: 8 Vector__XXX
 SG_ EngFuelValve2OutletAbsPress : 48|16@1+ (0.1,0) [0|6425.5] "kPa" Vector__XXX
 SG_ EngFuelTemp2 : 32|8@1+ (1,-40) [-40|210] "deg C" Vector__XXX
 SG_ EngGas2MassFlowRate : 16|16@1+ (0.05,0) [0|3212.75] "kg/h" Vector__XXX
 SG_ EngFuelValve2IntakeAbsPress : 0|16@1+ (0.1,0) [0|6425.5] "kPa" Vector__XXX

BO_ 2566761214 EFL_P4: 8 Vector__XXX
 SG_ EngCentrifugalOilFilterSpeed : 24|16@1+ (4,0) [0|257020] "rpm" Vector__XXX
 SG_ EngCoolantPumpDiffPress : 16|8@1+ (1.64,-7) [-7|403] "kPa" Vector__XXX
 SG_ EngChargeAirCooler2IntakePress : 8|8@1+ (2,0) [0|500] "kPa" Vector__XXX
 SG_ EngChargeAirCooler1IntakePress : 0|8@1+ (2,0) [0|500] "kPa" Vector__XXX
 SG_ EngIntercoolerCoolantLevel : 40|8@1+ (0.4,0) [0|100] "%" Vector__XXX
 SG_ EngChargeAirCoolerOutletPress : 56|8@1+ (2,0) [0|500] "kPa" Vector__XXX
 SG_ EngAftercoolerCoolantLevel : 48|8@1+ (0.4,0) [0|100] "%" Vector__XXX

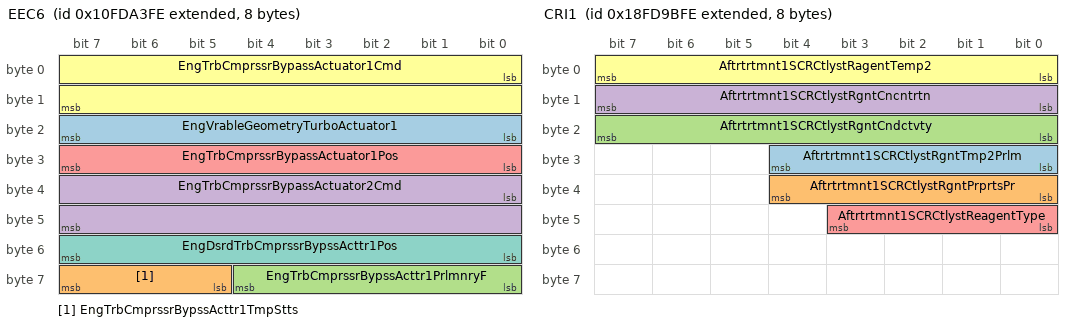
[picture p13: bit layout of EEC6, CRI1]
BO_ 2432541694 EEC6: 8 Vector__XXX
 SG_ EngVrableGeometryTurboActuator1 : 16|8@1+ (0.4,0) [0|100] "%" Vector__XXX
 SG_ EngTrbCmprssrBypssActtr1TmpStts : 61|3@1+ (1,0) [0|7] "" Vector__XXX
 SG_ EngTrbCmprssrBypssActtr1PrlmnryF : 56|5@1+ (1,0) [0|31] "" Vector__XXX
 SG_ EngTrbCmprssrBypassActuator2Cmd : 32|16@1+ (0.0025,0) [0|160.6375] "%" Vector__XXX
 SG_ EngTrbCmprssrBypassActuator1Pos : 24|8@1+ (0.4,0) [0|100] "%" Vector__XXX
 SG_ EngTrbCmprssrBypassActuator1Cmd : 0|16@1+ (0.0025,0) [0|160.6375] "%" Vector__XXX
 SG_ EngDsrdTrbCmprssrBypssActtr1Pos : 48|8@1+ (0.4,0) [0|100] "%" Vector__XXX

BO_ 2566759934 DC2: 8 Vector__XXX
 SG_ EnableStatusOfDoor10 : 58|2@1+ (1,0) [0|3] "" Vector__XXX
 SG_ OpenStatusOfDoor10 : 56|2@1+ (1,0) [0|3] "" Vector__XXX
 SG_ LockStatusOfDoor10 : 54|2@1+ (1,0) [0|3] "" Vector__XXX
 SG_ EnableStatusOfDoor9 : 52|2@1+ (1,0) [0|3] "" Vector__XXX
 SG_ OpenStatusOfDoor9 : 50|2@1+ (1,0) [0|3] "" Vector__XXX
 SG_ LockStatusOfDoor9 : 48|2@1+ (1,0) [0|3] "" Vector__XXX
 SG_ EnableStatusOfDoor8 : 46|2@1+ (1,0) [0|3] "" Vector__XXX
 SG_ OpenStatusOfDoor8 : 44|2@1+ (1,0) [0|3] "" Vector__XXX
 SG_ LockStatusOfDoor8 : 42|2@1+ (1,0) [0|3] "" Vector__XXX
 SG_ EnableStatusOfDoor7 : 40|2@1+ (1,0) [0|3] "" Vector__XXX
 SG_ OpenStatusOfDoor7 : 38|2@1+ (1,0) [0|3] "" Vector__XXX
 SG_ LockStatusOfDoor7 : 36|2@1+ (1,0) [0|3] "" Vector__XXX
 SG_ EnableStatusOfDoor6 : 34|2@1+ (1,0) [0|3] "" Vector__XXX
 SG_ OpenStatusOfDoor6 : 32|2@1+ (1,0) [0|3] "" Vector__XXX
 SG_ LockStatusOfDoor6 : 30|2@1+ (1,0) [0|3] "" Vector__XXX
 SG_ EnableStatusOfDoor5 : 28|2@1+ (1,0) [0|3] "" Vector__XXX
 SG_ OpenStatusOfDoor5 : 26|2@1+ (1,0) [0|3] "" Vector__XXX
 SG_ LockStatusOfDoor5 : 24|2@1+ (1,0) [0|3] "" Vector__XXX
 SG_ EnableStatusOfDoor4 : 22|2@1+ (1,0) [0|3] "" Vector__XXX
 SG_ OpenStatusOfDoor4 : 20|2@1+ (1,0) [0|3] "" Vector__XXX
 SG_ LockStatusOfDoor4 : 18|2@1+ (1,0) [0|3] "" Vector__XXX
 SG_ EnableStatusOfDoor3 : 16|2@1+ (1,0) [0|3] "" Vector__XXX
 SG_ OpenStatusOfDoor3 : 14|2@1+ (1,0) [0|3] "" Vector__XXX
 SG_ LockStatusOfDoor3 : 12|2@1+ (1,0) [0|3] "" Vector__XXX
 SG_ EnableStatusOfDoor2 : 10|2@1+ (1,0) [0|3] "" Vector__XXX
 SG_ OpenStatusOfDoor2 : 8|2@1+ (1,0) [0|3] "" Vector__XXX
 SG_ LockStatusOfDoor2 : 6|2@1+ (1,0) [0|3] "" Vector__XXX
 SG_ EnableStatusOfDoor1 : 4|2@1+ (1,0) [0|3] "" Vector__XXX
 SG_ OpenStatusOfDoor1 : 2|2@1+ (1,0) [0|3] "" Vector__XXX
 SG_ LockStatusOfDoor1 : 0|2@1+ (1,0) [0|3] "" Vector__XXX

BO_ 2566757374 CRI1: 8 Vector__XXX
 SG_ Aftrtrtmnt1SCRCtlystRgntTmp2Prlm : 24|5@1+ (1,0) [0|31] "" Vector__XXX
 SG_ Aftrtrtmnt1SCRCtlystRgntPrprtsPr : 32|5@1+ (1,0) [0|31] "" Vector__XXX
 SG_ Aftrtrtmnt1SCRCtlystRgntCndctvty : 16|8@1+ (5,0) [0|1250] "microSiemens/mm" Vector__XXX
 SG_ Aftrtrtmnt1SCRCtlystRgntCncntrtn : 8|8@1+ (0.25,0) [0|62.5] "%" Vector__XXX
 SG_ Aftrtrtmnt1SCRCtlystReagentType : 40|4@1+ (1,0) [0|15] "" Vector__XXX
 SG_ Aftrtrtmnt1SCRCtlystRagentTemp2 : 0|8@1+ (1,-40) [-40|210] "deg C" Vector__XXX

BO_ 2364546302 RGAAQ: 8 Vector__XXX
 SG_ RqdGnrtrAvrgLneLineACRMSVoltage : 0|32@1+ (0.0078125,0) [0|32899071] "V" Vector__XXX

BO_ 2431654654 TFAC: 8 Vector__XXX
 SG_ EngThrottleActuator2CtrlCmd : 16|16@1+ (0.0025,0) [0|160.6375] "%" Vector__XXX
 SG_ EngThrottleActuator1CtrlCmd : 0|16@1+ (0.0025,0) [0|160.6375] "%" Vector__XXX
 SG_ EngFuelActuator2CtrlCmd : 48|16@1+ (0.0025,0) [0|160.6375] "%" Vector__XXX
 SG_ EngFuelActuator1CtrlCmd : 32|16@1+ (0.0025,0) [0|160.6375] "%" Vector__XXX

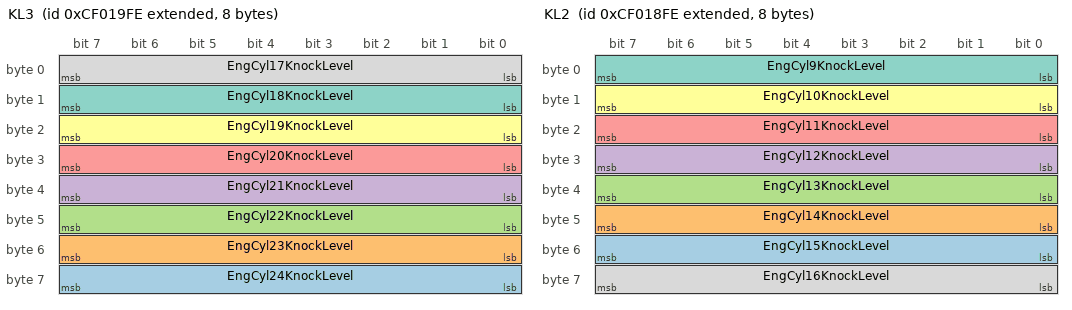
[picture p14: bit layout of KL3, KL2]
BO_ 2364545534 KL3: 8 Vector__XXX
 SG_ EngCyl24KnockLevel : 56|8@1+ (1,0) [0|250] "%" Vector__XXX
 SG_ EngCyl23KnockLevel : 48|8@1+ (1,0) [0|250] "%" Vector__XXX
 SG_ EngCyl22KnockLevel : 40|8@1+ (1,0) [0|250] "%" Vector__XXX
 SG_ EngCyl21KnockLevel : 32|8@1+ (1,0) [0|250] "%" Vector__XXX
 SG_ EngCyl20KnockLevel : 24|8@1+ (1,0) [0|250] "%" Vector__XXX
 SG_ EngCyl19KnockLevel : 16|8@1+ (1,0) [0|250] "%" Vector__XXX
 SG_ EngCyl18KnockLevel : 8|8@1+ (1,0) [0|250] "%" Vector__XXX
 SG_ EngCyl17KnockLevel : 0|8@1+ (1,0) [0|250] "%" Vector__XXX

BO_ 2364545278 KL2: 8 Vector__XXX
 SG_ EngCyl15KnockLevel : 48|8@1+ (1,0) [0|250] "%" Vector__XXX
 SG_ EngCyl14KnockLevel : 40|8@1+ (1,0) [0|250] "%" Vector__XXX
 SG_ EngCyl13KnockLevel : 32|8@1+ (1,0) [0|250] "%" Vector__XXX
 SG_ EngCyl12KnockLevel : 24|8@1+ (1,0) [0|250] "%" Vector__XXX
 SG_ EngCyl11KnockLevel : 16|8@1+ (1,0) [0|250] "%" Vector__XXX
 SG_ EngCyl10KnockLevel : 8|8@1+ (1,0) [0|250] "%" Vector__XXX
 SG_ EngCyl9KnockLevel : 0|8@1+ (1,0) [0|250] "%" Vector__XXX
 SG_ EngCyl16KnockLevel : 56|8@1+ (1,0) [0|250] "%" Vector__XXX

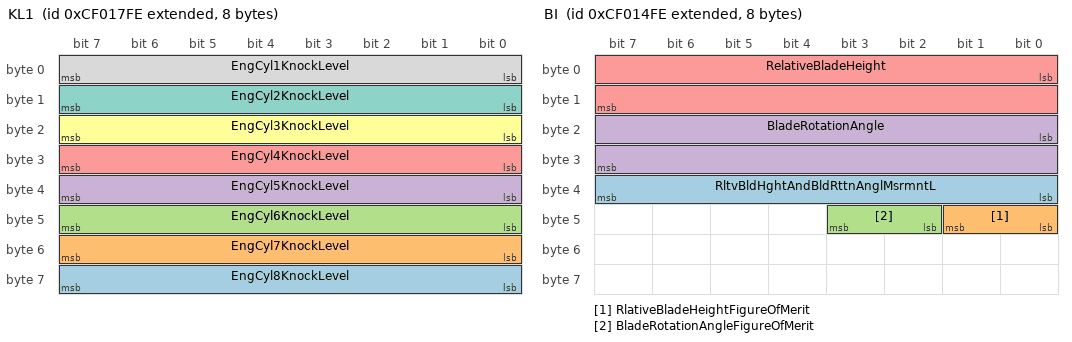
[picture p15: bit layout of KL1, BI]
BO_ 2364545022 KL1: 8 Vector__XXX
 SG_ EngCyl8KnockLevel : 56|8@1+ (1,0) [0|250] "%" Vector__XXX
 SG_ EngCyl7KnockLevel : 48|8@1+ (1,0) [0|250] "%" Vector__XXX
 SG_ EngCyl6KnockLevel : 40|8@1+ (1,0) [0|250] "%" Vector__XXX
 SG_ EngCyl5KnockLevel : 32|8@1+ (1,0) [0|250] "%" Vector__XXX
 SG_ EngCyl4KnockLevel : 24|8@1+ (1,0) [0|250] "%" Vector__XXX
 SG_ EngCyl3KnockLevel : 16|8@1+ (1,0) [0|250] "%" Vector__XXX
 SG_ EngCyl2KnockLevel : 8|8@1+ (1,0) [0|250] "%" Vector__XXX
 SG_ EngCyl1KnockLevel : 0|8@1+ (1,0) [0|250] "%" Vector__XXX

BO_ 2364544766 CCS: 8 Vector__XXX
 SG_ EngCyl9CombustionStatus : 16|2@1+ (1,0) [0|3] "" Vector__XXX
 SG_ EngCyl8CombustionStatus : 14|2@1+ (1,0) [0|3] "" Vector__XXX
 SG_ EngCyl7CombustionStatus : 12|2@1+ (1,0) [0|3] "" Vector__XXX
 SG_ EngCyl6CombustionStatus : 10|2@1+ (1,0) [0|3] "" Vector__XXX
 SG_ EngCyl5CombustionStatus : 8|2@1+ (1,0) [0|3] "" Vector__XXX
 SG_ EngCyl4CombustionStatus : 6|2@1+ (1,0) [0|3] "" Vector__XXX
 SG_ EngCyl3CombustionStatus : 4|2@1+ (1,0) [0|3] "" Vector__XXX
 SG_ EngCyl2CombustionStatus : 2|2@1+ (1,0) [0|3] "" Vector__XXX
 SG_ EngCyl24CombustionStatus : 46|2@1+ (1,0) [0|3] "" Vector__XXX
 SG_ EngCyl23CombustionStatus : 44|2@1+ (1,0) [0|3] "" Vector__XXX
 SG_ EngCyl22CombustionStatus : 42|2@1+ (1,0) [0|3] "" Vector__XXX
 SG_ EngCyl21CombustionStatus : 40|2@1+ (1,0) [0|3] "" Vector__XXX
 SG_ EngCyl20CombustionStatus : 38|2@1+ (1,0) [0|3] "" Vector__XXX
 SG_ EngCyl1CombustionStatus : 0|2@1+ (1,0) [0|3] "" Vector__XXX
 SG_ EngCyl19CombustionStatus : 36|2@1+ (1,0) [0|3] "" Vector__XXX
 SG_ EngCyl18CombustionStatus : 34|2@1+ (1,0) [0|3] "" Vector__XXX
 SG_ EngCyl17CombustionStatus : 32|2@1+ (1,0) [0|3] "" Vector__XXX
 SG_ EngCyl16CombustionStatus : 30|2@1+ (1,0) [0|3] "" Vector__XXX
 SG_ EngCyl15CombustionStatus : 28|2@1+ (1,0) [0|3] "" Vector__XXX
 SG_ EngCyl14CombustionStatus : 26|2@1+ (1,0) [0|3] "" Vector__XXX
 SG_ EngCyl13CombustionStatus : 24|2@1+ (1,0) [0|3] "" Vector__XXX
 SG_ EngCyl12CombustionStatus : 22|2@1+ (1,0) [0|3] "" Vector__XXX
 SG_ EngCyl11CombustionStatus : 20|2@1+ (1,0) [0|3] "" Vector__XXX
 SG_ EngCyl10CombustionStatus : 18|2@1+ (1,0) [0|3] "" Vector__XXX

BO_ 2364544510 RGTARP: 8 Vector__XXX
 SG_ RqGenOverallPowerFactorLagging : 48|2@1+ (1,0) [0|4] "" Vector__XXX
 SG_ RqGeneratorOverallPowerFactor : 32|16@1+ (6.103515625E-005,-1) [-1|2.921814] "" Vector__XXX
 SG_ RqGeneratorTotalACReactivePower : 0|32@1+ (1,-2000000000) [-2000000000|2000000000] "VA" Vector__XXX

BO_ 2364544254 BI: 8 Vector__XXX
 SG_ RltvBldHghtAndBldRttnAnglMsrmntL : 32|8@1+ (0.5,0) [0|125] "ms" Vector__XXX
 SG_ RlativeBladeHeightFigureOfMerit : 40|2@1+ (1,0) [0|3] "" Vector__XXX
 SG_ BladeRotationAngleFigureOfMerit : 42|2@1+ (1,0) [0|3] "" Vector__XXX
 SG_ BladeRotationAngle : 16|16@1+ (0.0078125,-200) [-200|301.99] "deg" Vector__XXX
 SG_ RelativeBladeHeight : 0|16@1+ (0.1,-3200) [-3200|3225.5] "mm" Vector__XXX

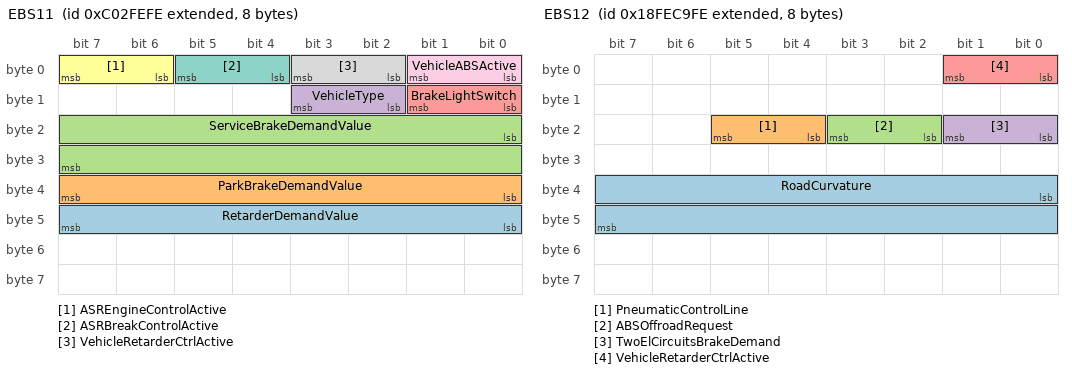
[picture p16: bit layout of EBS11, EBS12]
BO_ 2349006590 EBS11: 8 Vector__XXX
 SG_ RetarderDemandValue : 40|8@1+ (1,-125) [-125|125] "%" Vector__XXX
 SG_ ParkBrakeDemandValue : 32|8@1+ (0.4,0) [0|100] "%" Vector__XXX
 SG_ ServiceBrakeDemandValue : 16|16@1+ (0.01953125,0) [0|1255] "kPa" Vector__XXX
 SG_ VehicleType : 10|2@1+ (1,0) [0|3] "" Vector__XXX
 SG_ BrakeLightSwitch : 8|2@1+ (1,0) [0|3] "" Vector__XXX
 SG_ ASREngineControlActive : 6|2@1+ (1,0) [0|3] "" Vector__XXX
 SG_ ASRBreakControlActive : 4|2@1+ (1,0) [0|3] "" Vector__XXX
 SG_ VehicleRetarderCtrlActive : 2|2@1+ (1,0) [0|3] "" Vector__XXX
 SG_ VehicleABSActive : 0|2@1+ (1,0) [0|1] "" Vector__XXX

BO_ 2566834686 EBS12: 8 Vector__XXX
 SG_ RoadCurvature : 32|16@1+ (0.0078125,-250) [-250|251.992] "1/km" Vector__XXX
 SG_ PneumaticControlLine : 20|2@1+ (1,0) [0|1] "" Vector__XXX
 SG_ ABSOffroadRequest : 18|2@1+ (1,0) [0|1] "" Vector__XXX
 SG_ TwoElCircuitsBrakeDemand : 16|2@1+ (1,0) [0|1] "" Vector__XXX
 SG_ VehicleRetarderCtrlActive : 0|2@1+ (1,0) [0|3] "" Vector__XXX

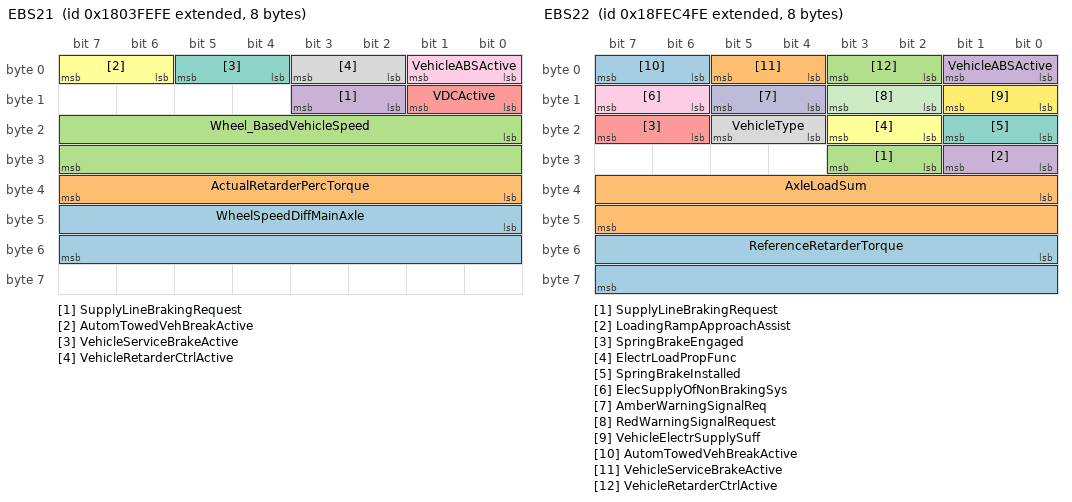
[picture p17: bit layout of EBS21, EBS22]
BO_ 2550398718 EBS21: 8 Vector__XXX
 SG_ WheelSpeedDiffMainAxle : 40|16@1+ (0.00390625,-125) [-125|125] "km/hr" Vector__XXX
 SG_ ActualRetarderPercTorque : 32|8@1+ (1,-125) [-125|125] "%" Vector__XXX
 SG_ Wheel_BasedVehicleSpeed : 16|16@1+ (0.00390625,0) [0|251] "km/hr" Vector__XXX
 SG_ SupplyLineBrakingRequest : 10|2@1+ (1,0) [0|1] "" Vector__XXX
 SG_ VDCActive : 8|2@1+ (1,0) [0|1] "" Vector__XXX
 SG_ AutomTowedVehBreakActive : 6|2@1+ (1,0) [0|1] "" Vector__XXX
 SG_ VehicleServiceBrakeActive : 4|2@1+ (1,0) [0|1] "" Vector__XXX
 SG_ VehicleRetarderCtrlActive : 2|2@1+ (1,0) [0|3] "" Vector__XXX
 SG_ VehicleABSActive : 0|2@1+ (1,0) [0|1] "" Vector__XXX

BO_ 2566833406 EBS22: 8 Vector__XXX
 SG_ ReferenceRetarderTorque : 48|16@1+ (1,0) [0|64255] "Nm" Vector__XXX
 SG_ AxleLoadSum : 32|16@1+ (2,0) [0|128510] "kg" Vector__XXX
 SG_ SupplyLineBrakingRequest : 26|2@1+ (1,0) [0|1] "" Vector__XXX
 SG_ LoadingRampApproachAssist : 24|2@1+ (1,0) [0|1] "" Vector__XXX
 SG_ SpringBrakeEngaged : 22|2@1+ (1,0) [0|1] "" Vector__XXX
 SG_ ElectrLoadPropFunc : 18|2@1+ (1,0) [0|1] "" Vector__XXX
 SG_ SpringBrakeInstalled : 16|2@1+ (1,0) [0|1] "" Vector__XXX
 SG_ VehicleType : 20|2@1+ (1,0) [0|3] "" Vector__XXX
 SG_ ElecSupplyOfNonBrakingSys : 14|2@1+ (1,0) [0|1] "" Vector__XXX
 SG_ AmberWarningSignalReq : 12|2@1+ (1,0) [0|1] "" Vector__XXX
 SG_ RedWarningSignalRequest : 10|2@1+ (1,0) [0|1] "" Vector__XXX
 SG_ VehicleElectrSupplySuff : 8|2@1+ (1,0) [0|1] "" Vector__XXX
 SG_ AutomTowedVehBreakActive : 6|2@1+ (1,0) [0|1] "" Vector__XXX
 SG_ VehicleServiceBrakeActive : 4|2@1+ (1,0) [0|1] "" Vector__XXX
 SG_ VehicleRetarderCtrlActive : 2|2@1+ (1,0) [0|3] "" Vector__XXX
 SG_ VehicleABSActive : 0|2@1+ (1,0) [0|1] "" Vector__XXX

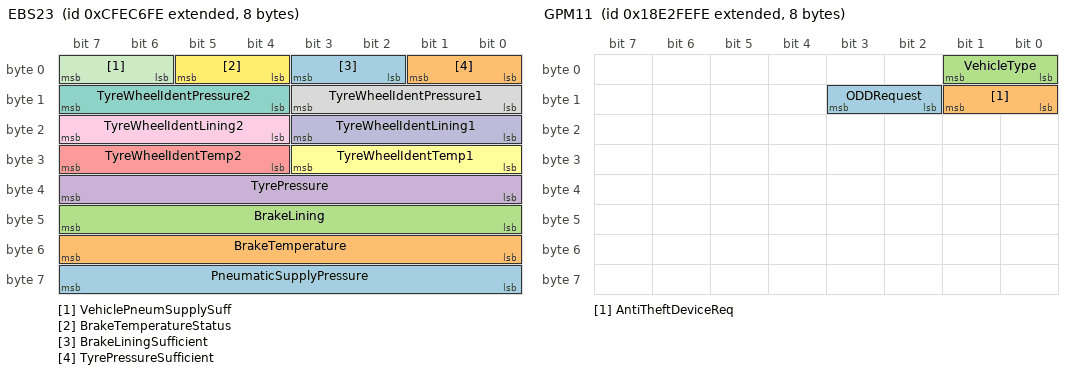
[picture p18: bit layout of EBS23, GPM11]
BO_ 2365507326 EBS23: 8 Vector__XXX
 SG_ PneumaticSupplyPressure : 56|8@1+ (5,0) [0|1250] "kPa" Vector__XXX
 SG_ BrakeTemperature : 48|8@1+ (10,0) [0|2500] "deg C" Vector__XXX
 SG_ BrakeLining : 40|8@1+ (0.4,0) [0|100] "%" Vector__XXX
 SG_ TyrePressure : 32|8@1+ (10,0) [0|2500] "kPa" Vector__XXX
 SG_ TyreWheelIdentTemp2 : 28|4@1+ (1,0) [0|15] "" Vector__XXX
 SG_ TyreWheelIdentTemp1 : 24|4@1+ (1,0) [0|15] "" Vector__XXX
 SG_ TyreWheelIdentPressure2 : 12|4@1+ (1,0) [0|15] "" Vector__XXX
 SG_ TyreWheelIdentPressure1 : 8|4@1+ (1,0) [0|15] "" Vector__XXX
 SG_ TyreWheelIdentLining2 : 20|4@1+ (1,0) [0|15] "" Vector__XXX
 SG_ TyreWheelIdentLining1 : 16|4@1+ (1,0) [0|15] "" Vector__XXX
 SG_ VehiclePneumSupplySuff : 6|2@1+ (1,0) [0|1] "" Vector__XXX
 SG_ BrakeTemperatureStatus : 4|2@1+ (1,0) [0|1] "" Vector__XXX
 SG_ BrakeLiningSufficient : 2|2@1+ (1,0) [0|1] "" Vector__XXX
 SG_ TyrePressureSufficient : 0|2@1+ (1,0) [0|1] "" Vector__XXX

BO_ 2565013246 GPM11: 8 Vector__XXX
 SG_ ODDRequest : 10|2@1+ (1,0) [0|3] "" Vector__XXX
 SG_ AntiTheftDeviceReq : 8|2@1+ (1,0) [0|3] "" Vector__XXX
 SG_ VehicleType : 0|2@1+ (1,0) [0|3] "" Vector__XXX

BO_ 2566807038 GPM12: 8 Vector__XXX
 SG_ MaxVehicleSpeedLimit : 32|8@1+ (1,0) [0|250] "km/h" Vector__XXX
 SG_ EngineSpeedUpperLimit : 0|16@1+ (0.125,0) [0|8031.875] "rpm" Vector__XXX
 SG_ EngineSpeedLowerLimit : 16|16@1+ (0.125,0) [0|8191.875] "rpm" Vector__XXX

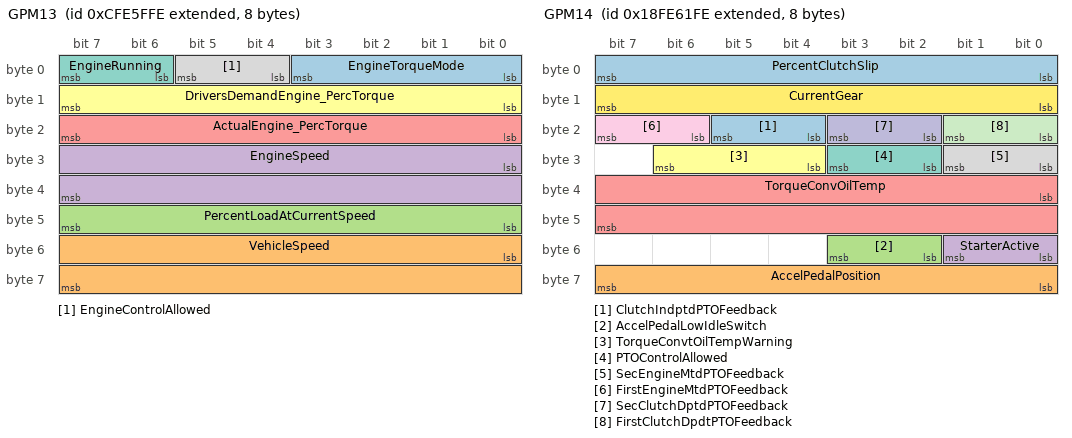
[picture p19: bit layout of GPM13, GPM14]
BO_ 2365480958 GPM13: 8 Vector__XXX
 SG_ EngineTorqueMode : 0|4@1+ (1,0) [0|15] "" Vector__XXX
 SG_ VehicleSpeed : 48|16@1+ (0.00390625,0) [0|250.996] "km/hr" Vector__XXX
 SG_ PercentLoadAtCurrentSpeed : 40|8@1+ (1,0) [0|125] "%" Vector__XXX
 SG_ EngineSpeed : 24|16@1+ (0.125,0) [0|8031.88] "rpm" Vector__XXX
 SG_ ActualEngine_PercTorque : 16|8@1+ (1,-125) [-125|125] "%" Vector__XXX
 SG_ DriversDemandEngine_PercTorque : 8|8@1+ (1,-125) [-125|125] "%" Vector__XXX
 SG_ EngineRunning : 6|2@1+ (1,0) [0|1] "" Vector__XXX
 SG_ EngineControlAllowed : 4|2@1+ (1,0) [0|1] "" Vector__XXX

BO_ 2566808062 GPM14: 8 Vector__XXX
 SG_ ClutchIndptdPTOFeedback : 20|2@1+ (1,0) [0|1] "" Vector__XXX
 SG_ AccelPedalPosition : 56|8@1+ (0.4,0) [0|100] "%" Vector__XXX
 SG_ AccelPedalLowIdleSwitch : 50|2@1+ (1,0) [0|1] "" Vector__XXX
 SG_ StarterActive : 48|2@1+ (1,0) [0|1] "" Vector__XXX
 SG_ TorqueConvOilTemp : 32|16@1+ (0.03125,-273) [-273|1735] "deg C" Vector__XXX
 SG_ TorqueConvtOilTempWarning : 28|3@1+ (1,0) [0|2] "" Vector__XXX
 SG_ PTOControlAllowed : 26|2@1+ (1,0) [0|1] "" Vector__XXX
 SG_ SecEngineMtdPTOFeedback : 24|2@1+ (1,0) [0|1] "" Vector__XXX
 SG_ FirstEngineMtdPTOFeedback : 22|2@1+ (1,0) [0|1] "" Vector__XXX
 SG_ SecClutchDptdPTOFeedback : 18|2@1+ (1,0) [0|1] "" Vector__XXX
 SG_ FirstClutchDpdtPTOFeedback : 16|2@1+ (1,0) [0|1] "" Vector__XXX
 SG_ CurrentGear : 8|8@1+ (1,-125) [-125|125] "" Vector__XXX
 SG_ PercentClutchSlip : 0|8@1+ (0.4,0) [0|100] "%" Vector__XXX

CM_ BO_ 2561212158 "Text Display";
CM_ SG_ 2561212158 TextDisplayInstructions "This parameter describes the status for the display how to show the information.";
CM_ BO_ 2566746366 "Door ramp control";
CM_ SG_ 2566746366 RetractStatusOfRamp5 "Retract status of ramp at doorway 5, counting from front to back on the vehicle.";
CM_ SG_ 2566746366 RetractStatusOfRamp4 "Retract status of ramp at doorway 4, counting from front to back on the vehicle.";
CM_ SG_ 2566746366 MovementStatusOfRamp5 "Movement status of ramp at doorway 5, counting from front to back on the vehicle.";
CM_ SG_ 2566746366 MovementStatusOfRamp4 "Movement status of ramp at doorway 4, counting from front to back on the vehicle.";
CM_ SG_ 2566746366 EnableStatusOfRamp5 "Enable status of ramp at doorway 5, counting from front to back on the vehicle.";
CM_ SG_ 2566746366 EnableStatusOfRamp4 "Enable status of ramp at doorway 4, counting from front to back on the vehicle.";
CM_ SG_ 2566746366 MovementStatusOfRamp3 "Movement status of ramp at doorway 3, counting from front to back on the vehicle.";
CM_ SG_ 2566746366 EnableStatusOfRamp3 "Enable status of ramp at doorway 3, counting from front to back on the vehicle.";
CM_ SG_ 2566746366 RetractStatusOfRamp3 "Retract status of ramp at doorway 3, counting from front to back on the vehicle.";
CM_ SG_ 2566746366 MovementStatusOfRamp2 "Movement status of ramp at doorway 2, counting from front to back on the vehicle.";
CM_ SG_ 2566746366 EnableStatusOfRamp2 "Enable status of ramp at doorway 2, counting from front to back on the vehicle.";
CM_ SG_ 2566746366 RetractStatusOfRamp2 "Retract status of ramp at doorway 2, counting from front to back on the vehicle.";
CM_ SG_ 2566746366 MovementStatusOfRamp1 "Movement status of ramp at doorway 1, counting from front to back on the vehicle.";
CM_ SG_ 2566746366 EnableStatusOfRamp1 "Enable status of ramp at doorway 1, counting from front to back on the vehicle.";
CM_ SG_ 2566746366 RetractStatusOfRamp1 "Retract status of ramp at doorway 1, counting from front to back on the vehicle.";
CM_ BO_ 2566750206 "Engine Configuration 2";
CM_ SG_ 2566750206 MaxCrankAttemptsPerStartAttempt "The number of cranking cycles that will be performed before ending the start attempt.";
CM_ BO_ 2566755582 "Electronic Engine Controller 7";
CM_ SG_ 2566755582 EngExhstGsRcrculation1Valve2Pos "The position of the second exhaust gas recirculation valve expressed as a percentage of full travel.";
CM_ SG_ 2566755582 EngExhstGsRcirculation1ValvePos "The position of the exhaust gas recirculation valve expressed as a percentage of full travel.";
CM_ SG_ 2566755582 EngCrnkcsBrthrOilSeparatorSpeed "The speed of a rotating (centrifugal) crankcase oil separator.";
CM_ SG_ 2566755582 CmdedEngIntakeManifoldPress "Provides the commanded set point value for the engine intake manifold pressure.";
CM_ BO_ 2566746110 "Electronic Engine Controller 8";
CM_ SG_ 2566746110 EngExhstGsRcrcltn1ClrIntkGsAbsPr "Exhaust Gas Recirculation gas absolute pressure is measured at the EGR cooler intake.";
CM_ SG_ 2566746110 EngExhstGsRcrcltn1ClrIntakeTemp "Exhaust Gas Recirculation (EGR) Temperature measured at the EGR cooler intake.";
CM_ SG_ 2566746110 EngExhstGsRcrcltn1ClrEfficiency "Exhaust Gas Recirculation cooler efficiency is an indication of the cooler's ability to reduce the temperature of the exhaust";
CM_ SG_ 2566746110 EngExhstGsRcrclation1Valve2Ctrl "Desired percentage of maximum Exhaust Gas Recirculation (EGR) valve opening for valve 2.";
CM_ BO_ 2566752510 "Engine Fluid Level/Pressure 5";
CM_ SG_ 2566752510 EngIntkVlvActtonOilPressForCyl4 "The gage pressure of the oil in the hydraulic accumulator that powers the engine intake valve for cylinder #4.";
CM_ SG_ 2566752510 EngIntkVlvActtonOilPressForCyl3 "The gage pressure of the oil in the hydraulic accumulator that powers the engine intake valve for cylinder #3.";
CM_ SG_ 2566752510 EngIntkVlvActtonOilPressForCyl2 "The gage pressure of the oil in the hydraulic accumulator that powers the engine intake valve for cylinder #2.";
CM_ SG_ 2566752510 EngIntkVlvActtonOilPressForCyl1 "The gage pressure of the oil in the hydraulic accumulator that powers the engine intake valve for cylinder #1.";
CM_ BO_ 2566752254 "Engine Fluid Level/Pressure 6";
CM_ SG_ 2566752254 EngIntkVlvActtonOilPressForCyl8 "The gage pressure of the oil in the hydraulic accumulator that powers the engine intake valve for cylinder #8.";
CM_ SG_ 2566752254 EngIntkVlvActtonOilPressForCyl7 "The gage pressure of the oil in the hydraulic accumulator that powers the engine intake valve for cylinder #7.";
CM_ SG_ 2566752254 EngIntkVlvActtonOilPressForCyl6 "The gage pressure of the oil in the hydraulic accumulator that powers the engine intake valve for cylinder #6.";
CM_ SG_ 2566752254 EngIntkVlvActtonOilPressForCyl5 "The gage pressure of the oil in the hydraulic accumulator that powers the engine intake valve for cylinder #5.";
CM_ BO_ 2566751998 "Engine Fluid Level/Pressure 7";
CM_ SG_ 2566751998 EngIntkVlvActtnOilPressForCyl12 "The gage pressure of the oil in the hydraulic accumulator that powers the engine intake valve for cylinder #12.";
CM_ SG_ 2566751998 EngIntkVlvActtnOilPressForCyl11 "The gage pressure of the oil in the hydraulic accumulator that powers the engine intake valve for cylinder #11.";
CM_ SG_ 2566751998 EngIntkVlvActtnOilPressForCyl10 "The gage pressure of the oil in the hydraulic accumulator that powers the engine intake valve for cylinder #10.";
CM_ SG_ 2566751998 EngIntkVlvActtonOilPressForCyl9 "The gage pressure of the oil in the hydraulic accumulator that powers the engine intake valve for cylinder #9.";
CM_ BO_ 2566751742 "Engine Fluid Level/Pressure 8";
CM_ SG_ 2566751742 EngIntkVlvActtnOilPressForCyl16 "The gage pressure of the oil in the hydraulic accumulator that powers the engine intake valve for cylinder #16.";
CM_ SG_ 2566751742 EngIntkVlvActtnOilPressForCyl15 "The gage pressure of the oil in the hydraulic accumulator that powers the engine intake valve for cylinder #15.";
CM_ SG_ 2566751742 EngIntkVlvActtnOilPressForCyl14 "The gage pressure of the oil in the hydraulic accumulator that powers the engine intake valve for cylinder #14.";
CM_ SG_ 2566751742 EngIntkVlvActtnOilPressForCyl13 "The gage pressure of the oil in the hydraulic accumulator that powers the engine intake valve for cylinder #13.";
CM_ BO_ 2566751486 "Engine Fluid Level/Pressure 9";
CM_ SG_ 2566751486 EngIntkVlvActtnOilPressForCyl20 "The gage pressure of the oil in the hydraulic accumulator that powers the engine intake valve for cylinder #20.";
CM_ SG_ 2566751486 EngIntkVlvActtnOilPressForCyl19 "The gage pressure of the oil in the hydraulic accumulator that powers the engine intake valve for cylinder #19.";
CM_ SG_ 2566751486 EngIntkVlvActtnOilPressForCyl18 "The gage pressure of the oil in the hydraulic accumulator that powers the engine intake valve for cylinder #18.";
CM_ SG_ 2566751486 EngIntkVlvActtnOilPressForCyl17 "The gage pressure of the oil in the hydraulic accumulator that powers the engine intake valve for cylinder #17.";
CM_ BO_ 2499641854 "EGR Cooler Bypass";
CM_ SG_ 2499641854 EGR1CoolerBypassActuatorPostion "The parameter gives the % open of the EGR Cooler Bypass Actuator, where 0% = Fully Closed (no gas flowing through";
CM_ BO_ 2566748158 "Engine Spark Voltage 1";
CM_ SG_ 2566748158 EngSparkPlug4 "The measured voltage of the spark event on Cylinder #4";
CM_ SG_ 2566748158 EngSparkPlug3 "The measured voltage of the spark event on Cylinder #3";
CM_ SG_ 2566748158 EngSparkPlug2 "The measured voltage of the spark event on Cylinder #2";
CM_ SG_ 2566748158 EngSparkPlug1 "The measured voltage of the spark event on Cylinder #1";
CM_ BO_ 2566747902 "Engine Spark Voltage 2";
CM_ SG_ 2566747902 EngSparkPlug8 "The measured voltage of the spark event on Cylinder #8";
CM_ SG_ 2566747902 EngSparkPlug7 "The measured voltage of the spark event on Cylinder #7";
CM_ SG_ 2566747902 EngSparkPlug6 "The measured voltage of the spark event on Cylinder #6";
CM_ SG_ 2566747902 EngSparkPlug5 "The measured voltage of the spark event on Cylinder #5";
CM_ BO_ 2566747646 "Engine Spark Voltage 3";
CM_ SG_ 2566747646 EngSparkPlug12 "The measured voltage of the spark event on Cylinder #12";
CM_ SG_ 2566747646 EngSparkPlug11 "The measured voltage of the spark event on Cylinder #11";
CM_ SG_ 2566747646 EngSparkPlug10 "The measured voltage of the spark event on Cylinder #10";
CM_ SG_ 2566747646 EngSparkPlug9 "The measured voltage of the spark event on Cylinder #9";
CM_ BO_ 2566747390 "Engine Spark Voltage 4";
CM_ SG_ 2566747390 EngSparkPlug16 "The measured voltage of the spark event on Cylinder #16";
CM_ SG_ 2566747390 EngSparkPlug15 "The measured voltage of the spark event on Cylinder #15";
CM_ SG_ 2566747390 EngSparkPlug14 "The measured voltage of the spark event on Cylinder #14";
CM_ SG_ 2566747390 EngSparkPlug13 "The measured voltage of the spark event on Cylinder #13";
CM_ BO_ 2566747134 "Engine Spark Voltage 5";
CM_ SG_ 2566747134 EngSparkPlug20 "The measured voltage of the spark event on Cylinder #20";
CM_ SG_ 2566747134 EngSparkPlug19 "The measured voltage of the spark event on Cylinder #19";
CM_ SG_ 2566747134 EngSparkPlug18 "The measured voltage of the spark event on Cylinder #18";
CM_ SG_ 2566747134 EngSparkPlug17 "The measured voltage of the spark event on Cylinder #17";
CM_ BO_ 2566746878 "Engine Spark Voltage 6";
CM_ SG_ 2566746878 EngSparkPlug24 "The measured voltage of the spark event on Cylinder #24";
CM_ SG_ 2566746878 EngSparkPlug23 "The measured voltage of the spark event on Cylinder #23";
CM_ SG_ 2566746878 EngSparkPlug22 "The measured voltage of the spark event on Cylinder #22";
CM_ SG_ 2566746878 EngSparkPlug21 "The measured voltage of the spark event on Cylinder #21";
CM_ BO_ 2561277694 "Forward Lane Image Command";
CM_ SG_ 2561277694 LaneDepartureWarningEnableCmd "Command to enable/disable Lane Departure Indication";
CM_ BO_ 2633861886 "SAE J2012 DTC Display";
CM_ SG_ 2633861886 J2012DTCOccurrenceCount "Number of occurrences of the respective SAE J2012 DTC being conveyed.";
CM_ SG_ 2633861886 J2012DTCStatus "Indicates if the respective SAE J2012 DTC is active or previously active.";
CM_ SG_ 2633861886 NumberOfJ2012DTCs "The number J2012 DTCs being conveyed in PGN 64906.";
CM_ BO_ 2565873150 "Steering Angle Sensor Information";
CM_ SG_ 2565873150 MessageChecksum "The message checksum is used to verify the signal path from the demanding device to the steering controller.";
CM_ SG_ 2565873150 MessageCounter "The message counter is to verify the signal path from the demanding device to the steering controller.";
CM_ SG_ 2565873150 SteerAngleSensorCalibrated "This signal indicates the calibration status of the steering angle sensor.";
CM_ SG_ 2565873150 SteerAngleSensorActiveMode "This signal indicates the operational mode of the steering angle sensor.";
CM_ SG_ 2565873150 SteerWheelAngleRange "The signal indicates the range of the steering wheel angle the sensor element is capable to measure.";
CM_ SG_ 2565873150 SteerWheelAngleRangeCounterType "The signal indicates whether the steering wheel angle sensor is capable of absolute measuring of the number of steering";
CM_ SG_ 2565873150 SteerWheelAngleRangeCounter "The signal indicates the number of steering wheel angle range overflows if the operating range of steering wheel is";
CM_ SG_ 2565873150 SteerWheelAngle "The main operator`s steering wheel angle (on the steering column, not the actual wheel angle).";
CM_ BO_ 2566745854 "Aftertreatment 1 SCR Service Information";
CM_ SG_ 2566745854 Aftrtrtmnt1SCRCtlystCnvrsnEffcnc "The SCR catalyst conversion efficiency percentage.";
CM_ SG_ 2566745854 Aftrtrtmnt1SCRCmddCtlystRgntCnsm "This parameter transmits the amount of reagent that the emissions control system has requested to be used, averaged";
CM_ SG_ 2566745854 Aftrtrtmnt1SCRAvrgCtlystRgntCnsm "Measured use of reagent by a Selective Catalytic Reduction system for exhaust emission control, averaged over the";
CM_ SG_ 2566745854 Aftrtrtmnt1DslExhstFldTnkLwLvlIn "The distance traveled while diesel exhaust fluid is low/empty or driver warning/inducement strategy is active.";
CM_ BO_ 2566751230 "Transfer Case Information";
CM_ SG_ 2566751230 TransferCaseStatus "This parameter describes the feedback from the transfer case controller .";
CM_ BO_ 2566755838 "Transmission Fluids 2";
CM_ SG_ 2566755838 TrnsTrqueConverterOilOutletTemp "Temperature of transmission torque converter outlet oil.";
CM_ SG_ 2566755838 TransOverheatIndicator "Signal from transmission indicating that its fluid temperature is above normal acceptable limits, and as a result,";
CM_ SG_ 2566755838 TransOilLifeRemaining "Signal which indicates the actual oil life remaining in percent.";
CM_ SG_ 2566755838 TransOilLevelSwitch "This switch indicates whether transmission oil level is full or empty.";
CM_ SG_ 2566755838 TransOilFilterRestrictionSwitch "This switch indicates whether the transmission oil filter is clogged.";
CM_ BO_ 2566752766 "Vehicle Direction/Speed 2";
CM_ SG_ 2566752766 VehicleRoll "This parameter indicates the roll in degrees from level.";
CM_ BO_ 2633938942 "Engine Speed/Load Factor Information";
CM_ SG_ 2633938942 TotalEngCruiseTime "Total time that the engine has operated in the cruise hold state, excluding time in accelerator override, over the life of the engine.";
CM_ SG_ 2633938942 TotalDriveAverageLoadFactor "Average engine load factor while engine speed is greater than zero, vehicle speed is greater than or equal to 2 km/h, and";
CM_ SG_ 2633938942 TripDriveAverageLoadFactor "Average engine load factor while engine speed is greater than zero, vehicle speed is greater than or equal to 2 km/h, and";
CM_ SG_ 2633938942 TripAverageEngSpeed "Average speed of the engine since the last trip reset.";
CM_ SG_ 2633938942 TripMaxEngSpeed "Maximum engine speed achieved since the last trip reset.";
CM_ BO_ 2566799614 "Lighting Data";
CM_ SG_ 2566799614 ImplementRearWorkLight "This parameter provides measured data from the implement rear work lamps.";
CM_ SG_ 2566799614 ImplementLeftForwardWorkLight "This parameter provides measured data from the forward facing work lights toward the left end of the implement.";
CM_ SG_ 2566799614 ImplementRightForwardWorkLight "This parameter provides measured data from the forward facing work lights toward the right end of the implement.";
CM_ SG_ 2566799614 ImplementLeftFacingWorkLight "This parameter provides measured data from the work lights mounted on an implement to illuminate beyond left end of";
CM_ SG_ 2566799614 ImplementRightFacingWorkLight "This parameter provides measured data from the work lights mounted on an implement to illuminate beyond right end of";
CM_ SG_ 2566799614 ImplementOEMOption1Light "This parameter provides measured data from the implement OEM option 1 light.";
CM_ SG_ 2566799614 ImplementOEMOption2Light "This parameter provides measured data from the implement OEM option 2 light.";
CM_ SG_ 2566799614 TrctrFrontHighMountedWorkLights "This parameter provides measured data from the tractor front high mounted work lights.";
CM_ SG_ 2566799614 TrctorFrontLowMountedWorkLights "This parameter provides measured data from the tractor front low mounted work lights.";
CM_ SG_ 2566799614 TrctorSideHighMountedWorkLights "This parameter provides measured data from the tractor side high mounted work lights.";
CM_ SG_ 2566799614 TractorSideLowMountedWorkLights "This parameter provides measured data from the tractor side low mounted work lights.";
CM_ SG_ 2566799614 TrctorRearHighMountedWorkLights "This parameter provides measured data from the tractor rear high mounted work lights.";
CM_ SG_ 2566799614 TractorRearLowMountedWorkLights "This parameter provides measured data from the tractor rear low mounted work lights.";
CM_ SG_ 2566799614 TrctrUndersideMountedWorkLights "This parameter provides measured data from the tractor underside mounted work lights.";
CM_ SG_ 2566799614 RearFogLights "This parameter provides measured data from the tractor and/or implement rear fog lights.";
CM_ SG_ 2566799614 TractorMarkerLight "This parameter provides measured data from the tractor and attached implement marker lights, including front position";
CM_ SG_ 2566799614 ImplementMarkerLight "This parameter provides measured data from an attached implement marker lights, including front position lights, rear tail";
CM_ SG_ 2566799614 TractorClearanceLight "This parameter provides measured data from the tractor high mounted clearance and center ID lights.";
CM_ SG_ 2566799614 ImplementClearanceLight "This parameter provides measured data from an attached implement high mounted clearance lights.";
CM_ SG_ 2566799614 LeftStopLight "This parameter provides measured data from the tractor and attached implement left stop lights.";
CM_ SG_ 2566799614 RightStopLight "This parameter provides measured data from the tractor and attached implement right stop lights.";
CM_ SG_ 2566799614 CenterStopLight "This parameter provides measured data from the tractor and attached implement center stop lights.";
CM_ SG_ 2566799614 BackUpLightAndAlarmHorn "This parameter provides measured data from the back up lights and/ or associated alarm.";
CM_ SG_ 2566799614 LeftTurnSignalLights "This parameter provides measured data from the tractor and attached implement left turn signal lights.";
CM_ SG_ 2566799614 RightTurnSignalLights "This parameter provides measured data from the tractor and attached implement right turn signal lights.";
CM_ SG_ 2566799614 RotatingBeaconLight "This parameter provides measured data from the beacon light on tractor or attached implements.";
CM_ SG_ 2566799614 TractorFrontFogLights "This parameter provides measured data from the tractor front fog lights.";
CM_ SG_ 2566799614 HighBeamHeadLightData "This parameter provides measured data from the tractor high beam head light lamps.";
CM_ SG_ 2566799614 LowBeamHeadLightData "This parameter provides measured data from the tractor low beam head light lamps.";
CM_ SG_ 2566799614 AltBeamHeadLightData "This parameter provides measured data from the tractor alternate beam head light lamps.";
CM_ SG_ 2566799614 RunningLight "This parameter provides measured data from the vehicle's running lights.";
CM_ BO_ 2365473278 "Lighting Command";
CM_ SG_ 2365473278 ImplementRearWorkLightCmd "Command to activate or de-activate implement rear work lights.";
CM_ SG_ 2365473278 ImplmentLeftForwardWorkLightCmd "Command to activate or de-activate the forward facing work lights toward the left end of the implement.";
CM_ SG_ 2365473278 ImplmntRightForwardWorkLightCmd "Command to activate or de-activate the forward facing work lights toward the right end of the implement.";
CM_ SG_ 2365473278 LightingDataRqCmd "Command to provide a response of the light state";
CM_ SG_ 2365473278 ImplementLeftFacingWorkLightCmd "Command to activate or de-activate work lights mounted on an implement to illuminate beyond left end of the implement.";
CM_ SG_ 2365473278 ImplmentRightFacingWorkLightCmd "Command to activate or de-activate work lights mounted on an implement to illuminate beyond right end of the implement.";
CM_ SG_ 2365473278 ImplementOEMOption1LightCmd "Command to activate or de-activate an implement OEM option 1 light.";
CM_ SG_ 2365473278 ImplementOEMOption2LightCmd "Command to activate or de-activate an implement OEM option 2 light.";
CM_ SG_ 2365473278 TrctrFrntHghMuntedWorkLightsCmd "Command to activate or de-activate the tractor front high mounted work lights.";
CM_ SG_ 2365473278 TrctrFrntLwMountedWorkLightsCmd "Command to activate or de-activate the tractor front low mounted work lights.";
CM_ SG_ 2365473278 TrctrSdHighMountedWorkLightsCmd "Command to activate or de-activate the tractor side high mounted work lights.";
CM_ SG_ 2365473278 TrctrSdeLowMountedWorkLightsCmd "Command to activate or de-activate the tractor side low mounted work lights.";
CM_ SG_ 2365473278 TrctrRrHighMountedWorkLightsCmd "Command to activate or de-activate the tractor rear high mounted work lights.";
CM_ SG_ 2365473278 TrctrRarLowMountedWorkLightsCmd "Command to activate or de-activate the tractor rear low mounted work lights.";
CM_ SG_ 2365473278 TrctrUndrsdMountedWorkLightsCmd "Command to activate or de-activate the tractor underside mounted work lights.";
CM_ SG_ 2365473278 RearFogLightCmd "Command to activate or de-activate tractor or implement rear fog lights.";
CM_ SG_ 2365473278 TractorMarkerLightCmd "Command to activate or de-activate tractor and implement front position lights, rear red tail lights, side amber running";
CM_ SG_ 2365473278 ImplementMarkerLightCmd "Command to activate or de-activate implement front position lights, rear red tail lights, side amber running lights, license";
CM_ SG_ 2365473278 TractorClearanceLightCmd "Command to activate or de-activate the tractor high mounted clearance and center ID lights";
CM_ SG_ 2365473278 ImplementClearanceLightCmd "Command to activate or de-activate the implement high mounted clearance and lights.";
CM_ SG_ 2365473278 LeftStopLightCmd "Command to activate or de-activate the tractor and implement left stop lights";
CM_ SG_ 2365473278 RightStopLightCmd "Command to activate or de-activate the tractor and implement right stop light";
CM_ SG_ 2365473278 CenterStopLightCmd "Command to activate or de-activate the tractor and implement center stop light";
CM_ SG_ 2365473278 BackUpLightAndAlarmHornCmd "Command to activate or de-activate the back up lights and/ or associated alarm if required";
CM_ SG_ 2365473278 LeftTurnSignalLightsCmd "Command to activate or de-activate left turn signal lights on the tractor and all connected implements";
CM_ SG_ 2365473278 RightTurnSignalLightsCmd "Command to activate or de-activate right turn signal lights on the tractor and all connected implements";
CM_ SG_ 2365473278 RotatingBeaconLightCmd "Command to activate or de-activate slow moving vehicle indicator lights on tractor and/or implements.";
CM_ SG_ 2365473278 TractorFrontFogLightsCmd "Command to activate or de-activate tractor front fog lights.";
CM_ SG_ 2365473278 HighBeamHeadLightCmd "Command to activate or de-activate the tractor high beam head light lamps.";
CM_ SG_ 2365473278 LowBeamHeadLightCmd "Command to activate or de-activate the tractor low beam head light lamps.";
CM_ SG_ 2365473278 AltBeamHeadLightCmd "Command to activate or de-activate the tractor alternate head lights (only low beam is available on alternate head lights).";
CM_ SG_ 2365473278 RunningLightCmd "Command to activate or de-activate the tractor or powered vehicle running lights.";
CM_ BO_ 2365485822 "Laser Leveling System Blade Control";
CM_ SG_ 2365485822 BladeCtrlMode "Allows the user to select the type of blade control for the land leveling system.";
CM_ SG_ 2365485822 BladeDurationAndDirection "Used to indicate the duration and direction that the land leveling system blade moves.";
CM_ SG_ 2365485822 LandLevelingSystemEnableStatus "Communicate the enable/disable status of the Land Leveling System.";
CM_ SG_ 2365485822 BladeCtrlModeRight "Indicate if the land leveling system's automatic control is active or inactive for the elevation sensor on the right side of the";
CM_ SG_ 2365485822 BladeCtrlModeLeft "Indicate if the land leveling system's automatic control is active or inactive for the elevation sensor on the left side of the";
CM_ BO_ 2633926654 "Ignition Timing 6";
CM_ SG_ 2633926654 EngActualIgntTiming "The actual ignition timing at the current engine conditions.";
CM_ SG_ 2633926654 EngDesiredIgntTiming3 "A programmable timing value specific to the engine's application.";
CM_ SG_ 2633926654 EngDesiredIgntTiming2 "A programmable timing value specific to the engine's application.";
CM_ SG_ 2633926654 EngDesiredIgntTiming1 "A programmable timing value specific to the engine's application.";
CM_ BO_ 2633926398 "Ignition Timing 5";
CM_ SG_ 2633926398 EngCyl20IgntTiming "The ignition timing of the cylinder.";
CM_ SG_ 2633926398 EngCyl19IgntTiming "The ignition timing of the cylinder.";
CM_ SG_ 2633926398 EngCyl18IgntTiming "The ignition timing of the cylinder.";
CM_ SG_ 2633926398 EngCyl17IgntTiming "The ignition timing of the cylinder.";
CM_ BO_ 2633926142 "Ignition Timing 4";
CM_ SG_ 2633926142 EngCyl16IgntTiming "The ignition timing of the cylinder.";
CM_ SG_ 2633926142 EngCyl15IgntTiming "The ignition timing of the cylinder.";
CM_ SG_ 2633926142 EngCyl14IgntTiming "The ignition timing of the cylinder.";
CM_ SG_ 2633926142 EngCyl13IgntTiming "The ignition timing of the cylinder.";
CM_ BO_ 2633925886 "Ignition Timing 3";
CM_ SG_ 2633925886 EngCyl12IgntTiming "The ignition timing of the cylinder.";
CM_ SG_ 2633925886 EngCyl11IgntTiming "The ignition timing of the cylinder.";
CM_ SG_ 2633925886 EngCyl10IgntTiming "The ignition timing of the cylinder.";
CM_ SG_ 2633925886 EngCyl9IgntTiming "The ignition timing of the cylinder.";
CM_ BO_ 2633925630 "Ignition Timing 2";
CM_ SG_ 2633925630 EngCyl8IgntTiming "The ignition timing of the cylinder.";
CM_ SG_ 2633925630 EngCyl7IgntTiming "The ignition timing of the cylinder.";
CM_ SG_ 2633925630 EngCyl6IgntTiming "The ignition timing of the cylinder.";
CM_ SG_ 2633925630 EngCyl5IgntTiming "The ignition timing of the cylinder.";
CM_ BO_ 2633925374 "Ignition Timing 1";
CM_ SG_ 2633925374 EngCyl4IgntTiming "The ignition timing of the cylinder.";
CM_ SG_ 2633925374 EngCyl3IgntTiming "The ignition timing of the cylinder.";
CM_ SG_ 2633925374 EngCyl2IgntTiming "The ignition timing of the cylinder.";
CM_ SG_ 2633925374 EngCyl1IgntTiming "The ignition timing of the cylinder.";
CM_ BO_ 2633927422 "Ignition Transformer Secondary Output 3";
CM_ SG_ 2633927422 EngCyl20IgntTransSecondOutput "This parameter indicates the relative intensity of the secondary output voltage of the ignition transformer.";
CM_ SG_ 2633927422 EngCyl19IgntTransSecondOutput "This parameter indicates the relative intensity of the secondary output voltage of the ignition transformer.";
CM_ SG_ 2633927422 EngCyl18IgntTransSecondOutput "This parameter indicates the relative intensity of the secondary output voltage of the ignition transformer.";
CM_ SG_ 2633927422 EngCyl17IgntTransSecondOutput "This parameter indicates the relative intensity of the secondary output voltage of the ignition transformer.";
CM_ BO_ 2633927166 "Ignition Transformer Secondary Output 2";
CM_ SG_ 2633927166 EngCyl16IgntTransSecondOutput "This parameter indicates the relative intensity of the secondary output voltage of the ignition transformer.";
CM_ SG_ 2633927166 EngCyl15IgntTransSecondOutput "This parameter indicates the relative intensity of the secondary output voltage of the ignition transformer.";
CM_ SG_ 2633927166 EngCyl14IgntTransSecondOutput "This parameter indicates the relative intensity of the secondary output voltage of the ignition transformer.";
CM_ SG_ 2633927166 EngCyl13IgntTransSecondOutput "This parameter indicates the relative intensity of the secondary output voltage of the ignition transformer.";
CM_ SG_ 2633927166 EngCyl12IgntTransSecondOutput "This parameter indicates the relative intensity of the secondary output voltage of the ignition transformer.";
CM_ SG_ 2633927166 EngCyl11IgntTransSecondOutput "This parameter indicates the relative intensity of the secondary output voltage of the ignition transformer.";
CM_ SG_ 2633927166 EngCyl10IgntTransSecondOutput "This parameter indicates the relative intensity of the secondary output voltage of the ignition transformer.";
CM_ SG_ 2633927166 EngCyl9IgntTransSecondOutput "This parameter indicates the relative intensity of the secondary output voltage of the ignition transformer.";
CM_ BO_ 2633926910 "Ignition Transformer Secondary Output 1";
CM_ SG_ 2633926910 EngCyl8IgntTransSecondOutput "This parameter indicates the relative intensity of the secondary output voltage of the ignition transformer.";
CM_ SG_ 2633926910 EngCyl7IgntTransSecondOutput "This parameter indicates the relative intensity of the secondary output voltage of the ignition transformer.";
CM_ SG_ 2633926910 EngCyl6IgntTransSecondOutput "This parameter indicates the relative intensity of the secondary output voltage of the ignition transformer.";
CM_ SG_ 2633926910 EngCyl5IgntTransSecondOutput "This parameter indicates the relative intensity of the secondary output voltage of the ignition transformer.";
CM_ SG_ 2633926910 EngCyl4IgntTransSecondOutput "This parameter indicates the relative intensity of the secondary output voltage of the ignition transformer.";
CM_ SG_ 2633926910 EngCyl3IgntTransSecondOutput "This parameter indicates the relative intensity of the secondary output voltage of the ignition transformer.";
CM_ SG_ 2633926910 EngCyl2IgntTransSecondOutput "This parameter indicates the relative intensity of the secondary output voltage of the ignition transformer.";
CM_ SG_ 2633926910 EngCyl1IgntTransSecondOutput "This parameter indicates the relative intensity of the secondary output voltage of the ignition transformer.";
CM_ BO_ 2566768894 "Operator Primary Intermediate Speed Control state";
CM_ SG_ 2566768894 EngOprtrPrmryIntrmdtSpdSlctStte "13 preprogrammed intermediate speed control settings are available for the controlling ECM to select.";
CM_ BO_ 2566769406 "Intermediate Speed Control";
CM_ SG_ 2566769406 EngOprtrPrmryIntrmdtSpeedSelect "Allows the operator to select one of 13 preprogrammed Intermediate Speed Control settings.";
CM_ BO_ 2566839550 "Idle Operation";
CM_ SG_ 2566839550 EngTotalIdleHours "Accumulated time of operation of the engine while under idle conditions.";
CM_ SG_ 2566839550 EngTotalIdleFuelUsed "Accumulated amount of fuel used during vehicle operation while under idle conditions.";
CM_ BO_ 2633934334 "Intake Manifold Information 2";
CM_ SG_ 2633934334 EngIntakeManifold6Temp "Temperature of pre-combustion air found in intake manifold number 6 of engine air supply system.";
CM_ SG_ 2633934334 EngIntakeManifold5Temp "Temperature of pre-combustion air found in intake manifold number 5 of engine air supply system.";
CM_ SG_ 2633934334 EngIntakeManifold4Temp "Temperature of pre-combustion air found in intake manifold of engine air supply system.";
CM_ SG_ 2633934334 EngIntakeManifold3Temp "Temperature of pre-combustion air found in intake manifold of engine air supply system.";
CM_ SG_ 2633934334 EngIntakeManifold2Temp "Temperature of pre-combustion air found in intake manifold of engine air supply system.";
CM_ BO_ 2566825726 "Intake Manifold Information 1";
CM_ SG_ 2566825726 EngTurbo4BoostPress "Gage pressure of air measured downstream of the compressor discharge side of the turbocharger.";
CM_ SG_ 2566825726 EngTurbo3BoostPress "Gage pressure of air measured downstream of the compressor discharge side of the turbocharger.";
CM_ SG_ 2566825726 EngTurbo2BoostPress "Gage pressure of air measured downstream of the compressor discharge side of the turbocharger.";
CM_ SG_ 2566825726 EngTurbo1BoostPress "Gage pressure of air measured downstream of the compressor discharge side of the turbocharger.";
CM_ BO_ 2566770942 "Intake/Exhaust Conditions 2";
CM_ SG_ 2566770942 EngAirFilter4DiffPress "Change in engine air system pressure, measured across the fourth air filter, due to the filter and any accumulation of solid";
CM_ SG_ 2566770942 EngAirFilter3DiffPress "Change in engine air system pressure, measured across the third air filter, due to the filter and any accumulation of solid";
CM_ SG_ 2566770942 EngAirFilter2DiffPress "Change in engine air system pressure, measured across the second air filter, due to the filter and any accumulation of";
CM_ SG_ 2566770942 EngIntakeManifold1AbsPress "The absolute pressure measurement of the air intake manifold.The absolute pressure measurement of the air intake manifold.";
CM_ SG_ 2566770942 EngIntakeManifold2AbsPress "The absolute pressure measurement of the air intake manifold for bank 2 or the second air intake manifold.";
CM_ SG_ 2566770942 EngIntakeManifold2Press "The gage pressure measurement of the air intake manifold for bank #2 or the second air intake manifold.";
CM_ SG_ 2566770942 EngIntakeManifold1AbsPressHiRes "The absolute pressure measurement of the air intake manifold.The absolute pressure measurement of the air intake manifold.";
CM_ BO_ 2566846206 "Intake/Exhaust Conditions 1";
CM_ SG_ 2566846206 EngCoolantFilterDiffPress "Change in coolant pressure, measured across the filter, due to the filter and any accumulation of solid or semisolid matter";
CM_ SG_ 2566846206 EngExhaustGasTemp "Temperature of combustion byproducts leaving the engine.";
CM_ SG_ 2566846206 EngAirFilter1DiffPress "Change in engine air system pressure, measured across the filter, due to the filter and any accumulation of solid foreign";
CM_ SG_ 2566846206 EngIntakeManifold1Temp "Temperature of pre-combustion air found in intake manifold of engine air supply system.";
CM_ SG_ 2566846206 EngIntakeManifold1Press "The gage pressure measurement of the air intake manifold.";
CM_ SG_ 2566846206 EngDslPrtclateFilterIntakePress "Exhaust back pressure as a result of particle accumulation on filter media placed in the exhaust stream.";
CM_ SG_ 2566846206 EngAirIntakePress "Absolute air pressure at input port to intake manifold or air box.";
CM_ BO_ 2566811134 "Heater Information";
CM_ SG_ 2566811134 CabHeatingZone "Parameter indicating whether the cab zone is being heated.";
CM_ SG_ 2566811134 EngHeatingZone "Parameter indicating whether the engine zone is being heated.";
CM_ SG_ 2566811134 CabVentilation "Indicates whether the cab is being ventilated or not.";
CM_ SG_ 2566811134 AuxHeaterMode "State of the auxiliary heater";
CM_ SG_ 2566811134 AuxHeaterOutputPowerPercent "Current auxiliary heater output power, relative to the auxiliary heater maximum output power.";
CM_ SG_ 2566811134 AuxHeaterInputAirTemp "Temperature of the input air in an auxiliary heater system.";
CM_ SG_ 2566811134 AuxHeaterOutputCoolantTemp "Temperature of the auxiliary heater output coolant (I.";
CM_ SG_ 2566811134 AuxHeaterWaterPumpStatus "Parameter indicating whether the auxiliary heater water pump is running";
CM_ BO_ 2298375934 "High Resolution Wheel Speed";
CM_ SG_ 2298375934 RearAxleRightWheelSpeed "High resolution measurement of the speed of the right wheel on the rear axle.";
CM_ SG_ 2298375934 RearAxleLeftWheelSpeed "High resolution measurement of the speed of the left wheel on the rear axle.";
CM_ SG_ 2298375934 FrontAxleRightWheelSpeed "High resolution measurement of the speed of the right wheel on the front axle.";
CM_ SG_ 2298375934 FrontAxleLeftWheelSpeed "High resolution measurement of the speed of the left wheel on the front axle.";
CM_ BO_ 2565867774 "Hydraulic Pressure Governor Info";
CM_ SG_ 2565867774 FireApparatusPumpEngagement "The measured status of the pump used to provide water in fire fighting apparatus for distribution of water through water";
CM_ SG_ 2565867774 EngHydPressGovernorSwitch "Switch that sets the mode of hydraulic governor";
CM_ SG_ 2565867774 EngHydPrssGovernorModeIndicator "Mode for governor operation is hydraulic pressure control.";
CM_ SG_ 2565867774 HydPress "Hydraulic pressure measured at the output of the hydraulic pump.";
CM_ BO_ 2566841854 "Engine Hours, Revolutions";
CM_ SG_ 2566841854 EngTotalRevolutions "Accumulated number of revolutions of engine crankshaft during its operation.";
CM_ SG_ 2566841854 EngTotalHoursOfOperation "Accumulated time of operation of engine.";
CM_ BO_ 2365449982 "Hydraulic Braking System";
CM_ SG_ 2365449982 HydBrakeFluidLevelSwitch "Signal which indicates whether the hydraulic fluid level in the reservoir(s) is sufficient.";
CM_ SG_ 2365449982 HydBrakeSystemAudibleWarningCmd "Signal which commands an audible warning by the hydraulic braking system.";
CM_ SG_ 2365449982 HydBrkePressSupplyStateCircuit2 "Signal which indicates whether the hydraulic brake pressure supply of circuit 2 is reliable; that is, able to support";
CM_ SG_ 2365449982 HydBrkePressSupplyStateCircuit1 "Signal which indicates whether the hydraulic brake pressure supply of circuit 1 is reliable; that is, able to support";
CM_ SG_ 2365449982 HydBrkPressWarningStateCircuit2 "Signal which indicates whether the hydraulic brake pressure of circuit 2 is below the warning level";
CM_ SG_ 2365449982 HydBrkPressWarningStateCircuit1 "Signal which indicates whether the hydraulic brake pressure of circuit 1 is below the warning level";
CM_ SG_ 2365449982 HydBrakePressCircuit2 "Gage hydraulic pressure in circuit 2 of the hydraulic brake system";
CM_ SG_ 2365449982 HydBrakePressCircuit1 "Gage hydraulic pressure in circuit 1 of the hydraulic brake system";
CM_ BO_ 2633939198 "Trip Fuel Information (Gaseous)";
CM_ SG_ 2633939198 TripDriveFuelEconomy "Trip drive fuel economy is equal to the distance traveled by vehicle in the drive state (engine speed greater than zero,";
CM_ SG_ 2633939198 TrpPTOGovernorNonmovingFuelUsed "Total fuel consumed while the PTO or remote PTO governors are in the hold state, the engine speed is greater than zero,";
CM_ SG_ 2633939198 TripVehicleIdleFuelUsed "Total fuel consumed while neither the PTO or remote PTO governors are active, the engine speed is greater than zero,";
CM_ SG_ 2633939198 TripCruiseFuelUsed "Total fuel consumed while the engine is in the cruise hold state since the last trip reset.";
CM_ SG_ 2633939198 TripDriveFuelUsed "Total fuel consumed while the engine speed is greater than zero, vehicle speed is greater than or equal to 2 km/h, and";
CM_ SG_ 2633939198 TripPTOGovernorMovingFuelUsed "Total fuel consumed while either the PTO or remote PTO governors are in the hold state, the engine speed is greater";
CM_ BO_ 2633927678 "Gaseous Fuel Pressure";
CM_ SG_ 2633927678 EngFuelValve1OutletAbsPress "Absolute Pressure of gas on outlet side of the first or only fuel system control valve.";
CM_ SG_ 2633927678 EngAirToFuelDiffPress "The differential pressure between the gaseous fuel and the air intake manifold.";
CM_ SG_ 2633927678 EngFuelValveDiffPress "The differential pressure between the intake and the outlet of a gaseous fuel valve.";
CM_ SG_ 2633927678 EngFuelValve1IntakeAbsPress "The absolute pressure of gas on the intake side of the first system control valve.";
CM_ BO_ 2633925118 "Fuel Information 2 (Gaseous)";
CM_ SG_ 2633925118 EngFuelFlowRate2 "The rate at which the fuel is flowing through a fuel valve.";
CM_ SG_ 2633925118 EngFuelFlowRate1 "The rate at which the fuel is flowing through a fuel valve.";
CM_ SG_ 2633925118 EngRqedFuelValve2Pos "The requested position of a gaseous fuel valve 2 that is metering the fuel flow to the engine, as requested by the Engine";
CM_ SG_ 2633925118 EngRqedFuelValve1Pos "The requested position of a gaseous fuel valve 1 that is metering the fuel flow to the engine.";
CM_ SG_ 2633925118 EngFuelValve2Pos "The position of a gaseous fuel valve that is metering the fuel flow to the engine.";
CM_ SG_ 2633925118 EngFuelValve1Pos "The position of a gaseous fuel valve that is metering the fuel flow to the engine.";
CM_ BO_ 2633937662 "Fuel Information 1 (Gaseous)";
CM_ SG_ 2633937662 TotalEngPTOGovernorFuelUsed "Total fuel used while the PTO or remote PTO governors are in the hold state and engine speed is above zero, over the";
CM_ SG_ 2633937662 TripAverageFuelRate "Average fuel rate, equal to trip fuel divided by trip time while the engine speed is above zero, since the last trip reset.";
CM_ SG_ 2633937662 EngFuelSpecificGravity "This parameter conveys the specific gravity of the gaseous fuel being used by the engine.";
CM_ BO_ 2566804990 "Gaseous Fuel Properties";
CM_ SG_ 2566804990 SpecificHeatRatio "The specific heat ratio of the fuel.";
CM_ BO_ 2633936894 "Fuel Consumption (Gaseous)";
CM_ SG_ 2633936894 TotalFuelUsed "Total fuel consumed (trip drive fuel + trip PTO moving fuel + trip PTO non-moving fuel + trip idle fuel) over the life of the engine.";
CM_ SG_ 2633936894 TripFuel "Total fuel consumed (trip drive fuel + trip PTO moving fuel + trip PTO non-moving fuel + trip idle fuel) since the last trip reset.";
CM_ BO_ 2566757630 "Sensor Electrical Power #2";
CM_ SG_ 2566757630 SensorSupplyVoltage6 "Sensor ECU supply voltage 6";
CM_ SG_ 2566757630 SensorSupplyVoltage5 "Sensor ECU supply voltage 5";
CM_ SG_ 2566757630 SensorSupplyVoltage8 "Sensor ECU supply voltage 8";
CM_ SG_ 2566757630 SensorSupplyVoltage7 "Sensor ECU supply voltage 7";
CM_ BO_ 2566757886 "Sensor Electrical Power #1";
CM_ SG_ 2566757886 SensorSupplyVoltage4 "Sensor ECU supply voltage 4";
CM_ SG_ 2566757886 SensorSupplyVoltage3 "Sensor ECU supply voltage 3";
CM_ SG_ 2566757886 SensorSupplyVoltage2 "Sensor ECU supply voltage 2";
CM_ SG_ 2566757886 SensorSupplyVoltage1 "Sensor ECU supply voltage 1";
CM_ BO_ 2566759678 "PTO Drive Engagement";
CM_ SG_ 2566759678 EnggmntSttusTransInputShaftPTO1 "Reports if this specific PTO drive is engaged.";
CM_ SG_ 2566759678 EnggmntSttusTransInputShaftPTO2 "Reports if this specific PTO drive is engaged.";
CM_ SG_ 2566759678 EnggmntSttusTransOutputShaftPTO "Reports if this specific PTO drive is engaged.";
CM_ SG_ 2566759678 EnggmntSttsTrnsfrCsOtptShaftPTO "Reports if this specific PTO drive is engaged.";
CM_ SG_ 2566759678 EnggmntCnsntTransInputShaftPTO1 "Status of the transmission controller's consent to engage the first or sole PTO drive mounted on the transmission case.";
CM_ SG_ 2566759678 EnggmntCnsntTransInputShaftPTO2 "Status of the transmission controller's consent to engage the second PTO drive mounted on the transmission case.";
CM_ SG_ 2566759678 EnggmntCnsntTransOutputShaftPTO "Status of the transmission controller's consent to engage the PTO drive connected to the transmission output shaft.";
CM_ SG_ 2566759678 EnggmntCnsntTrnsfrCsOtptShftPTO "Status of the transmission controller's consent to engage the PTO drive connected to the transfer case output shaft.";
CM_ SG_ 2566759678 EnableSwitchTransInputShaftPTO1 "Status of the operator's switch or other input which indicates the desire for engaging the first PTO drive mounted on the";
CM_ SG_ 2566759678 EnableSwitchTransInputShaftPTO2 "Status of the operator's switch or other input which indicates the desire for engaging the second PTO drive mounted on";
CM_ SG_ 2566759678 EnableSwitchTransOutputShaftPTO "Status of the operator's switch or other input which indicates the desire for engaging the PTO drive mounted on the";
CM_ SG_ 2566759678 EnblSwtchTrnsfrCsOutputShaftPTO "Status of the operator's switch or other input which indicates the desire for engaging the PTO drive mounted on the output";
CM_ SG_ 2566759678 EnggmntSttsPTOEngAccssoryDrive2 "Engagement status of the PTO engine accessory drive 2";
CM_ SG_ 2566759678 EnggmntSttsPTOEngAccssoryDrive1 "Engagement status of the PTO engine accessory drive 1";
CM_ SG_ 2566759678 EnggmntCnsntPTOEngAccssryDrive2 "Engagement Consent status for the PTO engine accessory drive 2";
CM_ SG_ 2566759678 EnggmntCnsntPTOEngAccssryDrive1 "Engagement consent status for the PTO engine accessory drive 1";
CM_ SG_ 2566759678 EngagementStatusPTOEngFlywheel "Engagement status of the PTO Engine Flywheel";
CM_ SG_ 2566759678 EngagementConsentPTOEngFlywheel "Engagement Consent status for the PTO Engine Flywheel";
CM_ SG_ 2566759678 EnblSwitchPTOEngAccessoryDrive2 "Status of the PTO engine accessory drive 2 enable switch";
CM_ SG_ 2566759678 EnblSwitchPTOEngAccessoryDrive1 "Status of the PTO engine accessory drive 1 enable switch";
CM_ SG_ 2566759678 EnableSwitchPTOEngFlywheel "Status of the PTO Engine Flywheel enable switch";
CM_ SG_ 2566759678 AtLeastOnePTOEngaged "Indicates that at least one PTO is engaged";
CM_ BO_ 2432541438 "Fuel Information 3 (Gaseous)";
CM_ SG_ 2432541438 EngFuelValve2OutletAbsPress "Absolute pressure of gas on outlet side of the second fuel system control valve.";
CM_ SG_ 2432541438 EngFuelTemp2 "Temperature 2 of fuel (or gas).";
CM_ SG_ 2432541438 EngGas2MassFlowRate "Gas mass flow rate delivered to an engine through its second fuel control system, using standard convention for";
CM_ SG_ 2432541438 EngFuelValve2IntakeAbsPress "Absolute pressure of gas on intake side of the second fuel system control valve, using standard convention for";
CM_ BO_ 2566761214 "Engine Fluid Level/Pressure 4";
CM_ SG_ 2566761214 EngCentrifugalOilFilterSpeed "The speed of a rotating (centrifugal) engine oil filter.";
CM_ SG_ 2566761214 EngCoolantPumpDiffPress "The differential pressure measured across the input and output of the engine coolant pump.";
CM_ SG_ 2566761214 EngChargeAirCooler2IntakePress "Pressure of air at intake to 2nd charge air cooler, from multiple first stage turbochargers being cooled and feeding multiple";
CM_ SG_ 2566761214 EngChargeAirCooler1IntakePress "Pressure of air at intake to 1st or only charge air cooler, from multiple first stage turbochargers being cooled and feeding";
CM_ SG_ 2566761214 EngIntercoolerCoolantLevel "Ratio of volume of liquid found in an engine intercooler cooling system to total engine intercooler cooling system volume.";
CM_ SG_ 2566761214 EngChargeAirCoolerOutletPress "Measures pressure of air at outlet from charge air cooler";
CM_ SG_ 2566761214 EngAftercoolerCoolantLevel "Ratio of aftercooler coolant system volume of liquid to total cooling system volume.";
CM_ BO_ 2432541694 "Electronic Engine Controller 6";
CM_ SG_ 2432541694 EngVrableGeometryTurboActuator1 "Actuator that controls the variable geometry turbocharger geometry.";
CM_ SG_ 2432541694 EngTrbCmprssrBypssActtr1TmpStts "Used to identify the status of the Engine Turbocharger Compresssor Bypass Actuator 1 drive circuitry temperature.";
CM_ SG_ 2432541694 EngTrbCmprssrBypssActtr1PrlmnryF "Used to identify the appplicable J1939-73 FMI detected in the Engine Turbocharger Compressor Bypass Actuator 1 by";
CM_ SG_ 2432541694 EngTrbCmprssrBypassActuator2Cmd "The command to a compressor bypass actuator 2, normalized to percent, where 0% nominally represents fully closed and";
CM_ SG_ 2432541694 EngTrbCmprssrBypassActuator1Pos "Measures the position of the turbocharger compressor bypass actuator, where 0% represents bypass fully closed and";
CM_ SG_ 2432541694 EngTrbCmprssrBypassActuator1Cmd "The command to a compressor bypass actuator, normalized to percent, where 0% nominally represents fully closed and";
CM_ SG_ 2432541694 EngDsrdTrbCmprssrBypssActtr1Pos "The requested position of the Engine Turbocharger Compressor Bypass actuator by the engine ECM, where 0%";
CM_ BO_ 2566759934 "Door Control 2";
CM_ SG_ 2566759934 EnableStatusOfDoor10 "Enable status of bus door 10.";
CM_ SG_ 2566759934 OpenStatusOfDoor10 "Open status of bus door 10";
CM_ SG_ 2566759934 LockStatusOfDoor10 "Lock status of bus door 10";
CM_ SG_ 2566759934 EnableStatusOfDoor9 "Enable status of bus door 9.";
CM_ SG_ 2566759934 OpenStatusOfDoor9 "Open status of bus door 9";
CM_ SG_ 2566759934 LockStatusOfDoor9 "Lock status of bus door 9";
CM_ SG_ 2566759934 EnableStatusOfDoor8 "Enable status of bus door 8.";
CM_ SG_ 2566759934 OpenStatusOfDoor8 "Open status of bus door 8";
CM_ SG_ 2566759934 LockStatusOfDoor8 "Lock status of bus door 8";
CM_ SG_ 2566759934 EnableStatusOfDoor7 "Enable status of bus door 7.";
CM_ SG_ 2566759934 OpenStatusOfDoor7 "Open status of bus door 7";
CM_ SG_ 2566759934 LockStatusOfDoor7 "Lock status of bus door 7";
CM_ SG_ 2566759934 EnableStatusOfDoor6 "Enable status of bus door 6.";
CM_ SG_ 2566759934 OpenStatusOfDoor6 "Open status of bus door 6";
CM_ SG_ 2566759934 LockStatusOfDoor6 "Lock status of bus door 6";
CM_ SG_ 2566759934 EnableStatusOfDoor5 "Enable status of bus door 5.";
CM_ SG_ 2566759934 OpenStatusOfDoor5 "Open status of bus door 5";
CM_ SG_ 2566759934 LockStatusOfDoor5 "Lock status of bus door 5";
CM_ SG_ 2566759934 EnableStatusOfDoor4 "Enable status of bus door 4.";
CM_ SG_ 2566759934 OpenStatusOfDoor4 "Open status of bus door 4";
CM_ SG_ 2566759934 LockStatusOfDoor4 "Lock status of bus door 4";
CM_ SG_ 2566759934 EnableStatusOfDoor3 "Enable status of bus door 3.";
CM_ SG_ 2566759934 OpenStatusOfDoor3 "Open status of bus door 3";
CM_ SG_ 2566759934 LockStatusOfDoor3 "Lock status of bus door 3";
CM_ SG_ 2566759934 EnableStatusOfDoor2 "Enable status of bus door 2.";
CM_ SG_ 2566759934 OpenStatusOfDoor2 "Open status of bus door 2";
CM_ SG_ 2566759934 LockStatusOfDoor2 "Lock status of bus door 2";
CM_ SG_ 2566759934 EnableStatusOfDoor1 "Enable status of bus door 1.";
CM_ SG_ 2566759934 OpenStatusOfDoor1 "Open status of bus door 1";
CM_ SG_ 2566759934 LockStatusOfDoor1 "Lock status of bus door 1";
CM_ BO_ 2566757374 "Aftertreatment 1 SCR Reagent Information";
CM_ SG_ 2566757374 Aftrtrtmnt1SCRCtlystRgntTmp2Prlm "Used to identify the applicable J1939-73 FMI that applies to the most significant failure of the catalyst temperature sensor.";
CM_ SG_ 2566757374 Aftrtrtmnt1SCRCtlystRgntPrprtsPr "Used to identify the applicable J1939-73 FMI that applies to the most significant failure of the catalyst reagent properties";
CM_ SG_ 2566757374 Aftrtrtmnt1SCRCtlystRgntCndctvty "A measure of the conductivity of the reagent or fluid at the sensor.";
CM_ SG_ 2566757374 Aftrtrtmnt1SCRCtlystRgntCncntrtn "A measure of the concentration of urea in water.";
CM_ SG_ 2566757374 Aftrtrtmnt1SCRCtlystReagentType "This parameter indicates what reagent is in the tank.";
CM_ SG_ 2566757374 Aftrtrtmnt1SCRCtlystRagentTemp2 "Temperature of the catalyst reagent at the device measuring reagent quality";
CM_ BO_ 2364546302 "Requested Generator Average Basic AC Quantities";
CM_ SG_ 2364546302 RqdGnrtrAvrgLneLineACRMSVoltage "The requested average AC RMS voltage to be delivered by the generator.";
CM_ BO_ 2431654654 "Engine Throttle / Fuel Actuator Control Command";
CM_ SG_ 2431654654 EngThrottleActuator2CtrlCmd "The control command to throttle actuator 2, normalized to percent, where 0% represents fully closed and 100%";
CM_ SG_ 2431654654 EngThrottleActuator1CtrlCmd "The control command to throttle actuator 1, normalized to percent, where 0% represents fully closed and 100%";
CM_ SG_ 2431654654 EngFuelActuator2CtrlCmd "The control command to fuel actuator 2, normalized to percent, where 0% represents fully closed and 100% represents";
CM_ SG_ 2431654654 EngFuelActuator1CtrlCmd "The control command to fuel actuator 1, normalized to percent, where 0% represents fully closed and 100% represents";
CM_ BO_ 2364545534 "Engine Knock Level #3";
CM_ SG_ 2364545534 EngCyl24KnockLevel "Used to indicate the level of knock for engine cylinder 24.";
CM_ SG_ 2364545534 EngCyl23KnockLevel "Used to indicate the level of knock for engine cylinder 23.";
CM_ SG_ 2364545534 EngCyl22KnockLevel "Used to indicate the level of knock for engine cylinder 22.";
CM_ SG_ 2364545534 EngCyl21KnockLevel "Used to indicate the level of knock for engine cylinder 21.";
CM_ SG_ 2364545534 EngCyl20KnockLevel "Used to indicate the level of knock for engine cylinder 20.";
CM_ SG_ 2364545534 EngCyl19KnockLevel "Used to indicate the level of knock for engine cylinder 19.";
CM_ SG_ 2364545534 EngCyl18KnockLevel "Used to indicate the level of knock for engine cylinder 18.";
CM_ SG_ 2364545534 EngCyl17KnockLevel "Used to indicate the level of knock for engine cylinder 17.";
CM_ BO_ 2364545278 "Engine Knock Level #2";
CM_ SG_ 2364545278 EngCyl15KnockLevel "Used to indicate the level of knock for engine cylinder 15.";
CM_ SG_ 2364545278 EngCyl14KnockLevel "Used to indicate the level of knock for engine cylinder 14.";
CM_ SG_ 2364545278 EngCyl13KnockLevel "Used to indicate the level of knock for engine cylinder 13.";
CM_ SG_ 2364545278 EngCyl12KnockLevel "Used to indicate the level of knock for engine cylinder 12.";
CM_ SG_ 2364545278 EngCyl11KnockLevel "Used to indicate the level of knock for engine cylinder 11.";
CM_ SG_ 2364545278 EngCyl10KnockLevel "Used to indicate the level of knock for engine cylinder 10.";
CM_ SG_ 2364545278 EngCyl9KnockLevel "Used to indicate the level of knock for engine cylinder 9.";
CM_ SG_ 2364545278 EngCyl16KnockLevel "Used to indicate the level of knock for engine cylinder 16.";
CM_ BO_ 2364545022 "Engine Knock Level #1";
CM_ SG_ 2364545022 EngCyl8KnockLevel "Used to indicate the level of knock for engine cylinder 8.";
CM_ SG_ 2364545022 EngCyl7KnockLevel "Used to indicate the level of knock for engine cylinder 7.";
CM_ SG_ 2364545022 EngCyl6KnockLevel "Used to indicate the level of knock for engine cylinder 6.";
CM_ SG_ 2364545022 EngCyl5KnockLevel "Used to indicate the level of knock for engine cylinder 5.";
CM_ SG_ 2364545022 EngCyl4KnockLevel "Used to indicate the level of knock for engine cylinder 4.";
CM_ SG_ 2364545022 EngCyl3KnockLevel "Used to indicate the level of knock for engine cylinder 3.";
CM_ SG_ 2364545022 EngCyl2KnockLevel "Used to indicate the level of knock for engine cylinder 2.";
CM_ SG_ 2364545022 EngCyl1KnockLevel "Used to indicate the level of knock for engine cylinder 1.";
CM_ BO_ 2364544766 "Cylinder Combustion Status";
CM_ SG_ 2364544766 EngCyl9CombustionStatus "This parameter is used to indicate state of combustion in engine cylinder #9";
CM_ SG_ 2364544766 EngCyl8CombustionStatus "This parameter is used to indicate state of combustion in engine cylinder #8";
CM_ SG_ 2364544766 EngCyl7CombustionStatus "This parameter is used to indicate state of combustion in engine cylinder #7";
CM_ SG_ 2364544766 EngCyl6CombustionStatus "This parameter is used to indicate state of combustion in engine cylinder #6";
CM_ SG_ 2364544766 EngCyl5CombustionStatus "This parameter is used to indicate state of combustion in engine cylinder #5";
CM_ SG_ 2364544766 EngCyl4CombustionStatus "This parameter is used to indicate state of combustion in engine cylinder #4";
CM_ SG_ 2364544766 EngCyl3CombustionStatus "This parameter is used to indicate state of combustion in engine cylinder #3";
CM_ SG_ 2364544766 EngCyl2CombustionStatus "This parameter is used to indicate state of combustion in engine cylinder #2";
CM_ SG_ 2364544766 EngCyl24CombustionStatus "This parameter is used to indicate state of combustion in engine cylinder #24";
CM_ SG_ 2364544766 EngCyl23CombustionStatus "This parameter is used to indicate state of combustion in engine cylinder #23";
CM_ SG_ 2364544766 EngCyl22CombustionStatus "This parameter is used to indicate state of combustion in engine cylinder #22";
CM_ SG_ 2364544766 EngCyl21CombustionStatus "This parameter is used to indicate state of combustion in engine cylinder #21";
CM_ SG_ 2364544766 EngCyl20CombustionStatus "This parameter is used to indicate state of combustion in engine cylinder #20";
CM_ SG_ 2364544766 EngCyl1CombustionStatus "This parameter is used to indicate state of combustion in engine cylinder #1";
CM_ SG_ 2364544766 EngCyl19CombustionStatus "This parameter is used to indicate state of combustion in engine cylinder #19";
CM_ SG_ 2364544766 EngCyl18CombustionStatus "This parameter is used to indicate state of combustion in engine cylinder #18";
CM_ SG_ 2364544766 EngCyl17CombustionStatus "This parameter is used to indicate state of combustion in engine cylinder #17";
CM_ SG_ 2364544766 EngCyl16CombustionStatus "This parameter is used to indicate state of combustion in engine cylinder #16";
CM_ SG_ 2364544766 EngCyl15CombustionStatus "This parameter is used to indicate state of combustion in engine cylinder #15";
CM_ SG_ 2364544766 EngCyl14CombustionStatus "This parameter is used to indicate state of combustion in engine cylinder #14";
CM_ SG_ 2364544766 EngCyl13CombustionStatus "This parameter is used to indicate state of combustion in engine cylinder #13";
CM_ SG_ 2364544766 EngCyl12CombustionStatus "This parameter is used to indicate state of combustion in engine cylinder #12";
CM_ SG_ 2364544766 EngCyl11CombustionStatus "This parameter is used to indicate state of combustion in engine cylinder #11";
CM_ SG_ 2364544766 EngCyl10CombustionStatus "This parameter is used to indicate state of combustion in engine cylinder #10";
CM_ BO_ 2364544510 "Requested Generator Total AC Reactive Power";
CM_ SG_ 2364544510 RqGenOverallPowerFactorLagging "The requested lead/lag status for the generator average AC power factor";
CM_ SG_ 2364544510 RqGeneratorOverallPowerFactor "The requested average power factor of the generator.";
CM_ SG_ 2364544510 RqGeneratorTotalACReactivePower "The total reactive power requested to be delivered by the generator";
CM_ BO_ 2364544254 "Blade Information";
CM_ SG_ 2364544254 RltvBldHghtAndBldRttnAnglMsrmntL "The estimated measurement latency of the measurement.";
CM_ SG_ 2364544254 RlativeBladeHeightFigureOfMerit "Figure of merit for blade height measurement.";
CM_ SG_ 2364544254 BladeRotationAngleFigureOfMerit "Figure of merit for blade rotation measurement.";
CM_ SG_ 2364544254 BladeRotationAngle "The blade rotation angle measurement around the yaw (z-axis).";
CM_ SG_ 2364544254 RelativeBladeHeight "The measured vertical distance from a fixed location on the machine blade to a ground-based reference.";
CM_ BO_ 2349006590 "ISO 11992: Towing vehicle message, electronic brake system #1/1";
CM_ SG_ 2349006590 RetarderDemandValue "The demanded value of the retarder on the towed vehicle(s) as a percentage of the absolute peak torque of retarder.";
CM_ SG_ 2349006590 ParkBrakeDemandValue "The requested brake pressure value of the parking brake as a percentage of maximum.";
CM_ SG_ 2349006590 ServiceBrakeDemandValue "The requested brake pressure value of the service brake demanded by the driver.";
CM_ SG_ 2349006590 VehicleType "Information to identify a dolly axle within the road train.";
CM_ SG_ 2349006590 BrakeLightSwitch "Signal which indicates that the brake pedal is being pressed.";
CM_ SG_ 2349006590 ASREngineControlActive "Signal which indicates that ASR engine control is active/passive.";
CM_ SG_ 2349006590 ASRBreakControlActive "Signal which indicates that ASR brake control is active/passive.";
CM_ SG_ 2349006590 VehicleRetarderCtrlActive "This signal indicates the active/passive state in all cases when the installed retarder is applied by the driver's demand or by other systems (brakes).";
CM_ SG_ 2349006590 VehicleABSActive "Signal indicating the ABS is active/passive.";
CM_ BO_ 2566834686 "ISO 11992: Towing vehicle message, electronic brake system #1/2";
CM_ SG_ 2566834686 RoadCurvature "Estimated value of the current road curvature for use by the adaptive cruise control system.";
CM_ SG_ 2566834686 PneumaticControlLine "Signal which indicates that the towing vehicle has a pneumatic control line for the towed vehicle service braking system";
CM_ SG_ 2566834686 ABSOffroadRequest "Request to activate the ABS off-road function. The switch signal is independent of an actual ABS control situation.";
CM_ SG_ 2566834686 TwoElCircuitsBrakeDemand "Signal which indicates that the service brake demand value sent by the towing vehicle can be generated by one or two independent electrical braking circuit(s).";
CM_ SG_ 2566834686 VehicleRetarderCtrlActive "This signal indicates the active/passive state in all cases when the installed retarder is applied by the driver's demand or by other systems (brakes).";
CM_ BO_ 2550398718 "ISO 11992: Towed vehicle message, electronic brake system #2/1";
CM_ SG_ 2550398718 WheelSpeedDiffMainAxle "Difference between the wheel speed at the right side and and the left side of the main axle.";
CM_ SG_ 2550398718 ActualRetarderPercTorque "Actual torque of the retarder as negative percentage of maximum.";
CM_ SG_ 2550398718 Wheel_BasedVehicleSpeed "Actual speed of the vehicle (positive value for forward and backward speed) calculated as the average of the wheel speeds of one axle influenced by slip and filtered by a frequency range of 5 Hz to 20 Hz.";
CM_ SG_ 2550398718 SupplyLineBrakingRequest "Signal indicating the trailer is requesting to be braked by the commercial vehicle by means of bleeding the pneumatic supply line.";
CM_ SG_ 2550398718 VDCActive "Signal which indicates that Vehicle Dynamic Control (VDC) is active/passive.";
CM_ SG_ 2550398718 AutomTowedVehBreakActive "Signal indicating the automatic towed vehicle braking is active/passive.";
CM_ SG_ 2550398718 VehicleServiceBrakeActive "Signal indicating the service brake of the towed vehicle is active/passive, by observing the brake pressure.";
CM_ SG_ 2550398718 VehicleRetarderCtrlActive "This signal indicates the active/passive state in all cases when the installed retarder is applied by the driver's demand or by other systems (brakes).";
CM_ SG_ 2550398718 VehicleABSActive "Signal indicating the ABS is active/passive.";
CM_ BO_ 2566833406 "ISO 11992: Towed vehicle message, electronic brake system #2/2";
CM_ SG_ 2566833406 ReferenceRetarderTorque "This parameter is the 100% reference value for all defined indicated retarder torque parameters.";
CM_ SG_ 2566833406 AxleLoadSum "Sum of the static vertical loads of the vehicle axles.";
CM_ SG_ 2566833406 SupplyLineBrakingRequest "Signal indicating the trailer is requesting to be braked by the commercial vehicle by means of bleeding the pneumatic supply line.";
CM_ SG_ 2566833406 LoadingRampApproachAssist "The parameter indicates whether the loading ramp approach assistance is activated.";
CM_ SG_ 2566833406 SpringBrakeEngaged "Signal indicating the vehicle spring brake is engaged.";
CM_ SG_ 2566833406 ElectrLoadPropFunc "Signal indicating the vehicle is equipped with an electrical load proportional function.";
CM_ SG_ 2566833406 SpringBrakeInstalled "Signal indicating the vehicle has one or more axle(s) fitted with spring brakes.";
CM_ SG_ 2566833406 VehicleType "Information to identify a dolly axle within the road train.";
CM_ SG_ 2566833406 ElecSupplyOfNonBrakingSys "Signal which indicates the status of the supply of non-braking systems.";
CM_ SG_ 2566833406 AmberWarningSignalReq "Request from the towed vehicle to the commercial vehicle to activate the amber warning signal on the commercial vehicle.";
CM_ SG_ 2566833406 RedWarningSignalRequest "Request from the towed vehicle to the commercial vehicle to activate the red warning signal on the commercial vehicle, which indicates certain specified failures within the braking equipment of the towed vehicles.";
CM_ SG_ 2566833406 VehicleElectrSupplySuff "Signal indicating the actual supply voltage is sufficient/insufficient for proper brake function (including over voltage).";
CM_ SG_ 2566833406 AutomTowedVehBreakActive "Signal indicating the automatic towed vehicle braking is active/passive.";
CM_ SG_ 2566833406 VehicleServiceBrakeActive "Signal indicating the service brake of the towed vehicle is active/passive, by observing the brake pressure.";
CM_ SG_ 2566833406 VehicleRetarderCtrlActive "This signal indicates the active/passive state in all cases when the installed retarder is applied by the driver's demand or by other systems (brakes).";
CM_ SG_ 2566833406 VehicleABSActive "Signal indicating the ABS is active/passive.";
CM_ BO_ 2365507326 "ISO 11992: Towed vehicle message, electronic brake system #2/3";
CM_ SG_ 2365507326 PneumaticSupplyPressure "Actual supply pressure of the reservoir of the braking system.";
CM_ SG_ 2365507326 BrakeTemperature "Actual brake temperature.";
CM_ SG_ 2365507326 BrakeLining "Actual relative value of brake lining of a specific brake.";
CM_ SG_ 2365507326 TyrePressure "Actual tyre pressure without corrections.";
CM_ SG_ 2365507326 TyreWheelIdentTemp2 "Second part of identification number of the tyre or wheel (the number of axles).";
CM_ SG_ 2365507326 TyreWheelIdentTemp1 "First part of identification number of the tyre or wheel (position on each axle).";
CM_ SG_ 2365507326 TyreWheelIdentPressure2 "Second part of identification number of the tyre or wheel (the number of axles).";
CM_ SG_ 2365507326 TyreWheelIdentPressure1 "First part of identification number of the tyre or wheel (position on each axle).";
CM_ SG_ 2365507326 TyreWheelIdentLining2 "Second part of identification number of the tyre or wheel (the number of axles).";
CM_ SG_ 2365507326 TyreWheelIdentLining1 "First part of identification number of the tyre or wheel (position on each axle).";
CM_ SG_ 2365507326 VehiclePneumSupplySuff "Signal indicating the actual supply pressure of the reservoir of the braking system is insufficient or sufficient.";
CM_ SG_ 2365507326 BrakeTemperatureStatus "Signal which indicates that the brake temperature is higher than a specific level.";
CM_ SG_ 2365507326 BrakeLiningSufficient "Signal which indicates that the brake lining is sufficient/insufficient.";
CM_ SG_ 2365507326 TyrePressureSufficient "Signal which indicates that the tyre pressure is insufficient";
CM_ BO_ 2565013246 "ISO 11992: Towing vehicle message, general purpose message #1/1

GPM 11 replaces GFM 11 in ISO 11992:1998 part 3";
CM_ SG_ 2565013246 ODDRequest "Command signal to switch on or off the obstacle detection device (ODD).";
CM_ SG_ 2565013246 AntiTheftDeviceReq "Command signal to activate the anti-theft device.";
CM_ SG_ 2565013246 VehicleType "Information to identify a dolly axle within the road train.";
CM_ BO_ 2566807038 "ISO 11992: Towing vehicle message, general purpose message #1/2";
CM_ SG_ 2566807038 MaxVehicleSpeedLimit "Maximum vehicle velocity allowed.";
CM_ SG_ 2566807038 EngineSpeedUpperLimit "The engine speed which cannot be exceeded.";
CM_ SG_ 2566807038 EngineSpeedLowerLimit "The minimum engine speed which the engine is allowed to reach.";
CM_ BO_ 2365480958 "ISO 11992: Towing vehicle message, general purpose message #1/3";
CM_ SG_ 2365480958 EngineTorqueMode "State signal which indicates which engine torque mode is currently generating, limiting, or controlling the torque";
CM_ SG_ 2365480958 PercentLoadAtCurrentSpeed "The ratio of actual engine percent torque to maximum indicated torque available at the current engine speed, clipped to zero torque during engine braking.";
CM_ SG_ 2365480958 EngineSpeed "Actual engine speed which is calculated over a minimum crankshaft angle of 720 degrees divided by
the number of cylinders.";
CM_ SG_ 2365480958 ActualEngine_PercTorque "The calculated output torque of the engine.";
CM_ SG_ 2365480958 DriversDemandEngine_PercTorque "The torque output of the engine requested by the driver.";
CM_ SG_ 2365480958 EngineRunning "Signal which indicates whether the engine is running.";
CM_ SG_ 2365480958 EngineControlAllowed "Switch signal which indicates that engine control is allowed.";
CM_ BO_ 2566808062 "ISO 11992: Towing vehicle message, general purpose message #1/4";
CM_ SG_ 2566808062 ClutchIndptdPTOFeedback "Signal which indicates the current state of the clutch independent power take off.";
CM_ SG_ 2566808062 AccelPedalPosition "The ratio of actual accelerator pedal position to maximum pedal position.";
CM_ SG_ 2566808062 AccelPedalLowIdleSwitch "Switch signal which indicates whether the accelerator pedal low idle switch is opened or closed.";
CM_ SG_ 2566808062 StarterActive "Signal which indicates whether the starter is in use.";
CM_ SG_ 2566808062 TorqueConvOilTemp "Temperature of the torque converter lubricant.";
CM_ SG_ 2566808062 TorqueConvtOilTempWarning "Signal which indicates that the torque converter oil temperature has reached its warning level.";
CM_ SG_ 2566808062 PTOControlAllowed "Switch signal which indicates that PTO control is allowed.";
CM_ SG_ 2566808062 SecEngineMtdPTOFeedback "Signal which indicates the current state of the second engine mounted power take off.";
CM_ SG_ 2566808062 FirstEngineMtdPTOFeedback "Signal which indicates the current state of the first engine mounted power take off.";
CM_ SG_ 2566808062 SecClutchDptdPTOFeedback "Signal which indicates the current state of the second clutch dependent power take off.";
CM_ SG_ 2566808062 FirstClutchDpdtPTOFeedback "Signal which indicates the current state of the first clutch dependent power take off.";
CM_ SG_ 2566808062 CurrentGear "The gear currently engaged in the transmission or the last gear engaged while the transmission is in process of shifting to the new or selected gear.";
CM_ SG_ 2566808062 PercentClutchSlip "Parameter which represents the ratio of input shaft speed to current engine speed (in percent).";
BA_DEF_ SG_  "SigType" ENUM  "Default","Range","RangeSigned","ASCII","Discrete","Control","ReferencePGN","DTC","StringDelimiter","StringLength","StringLengthControl";
BA_DEF_ SG_  "GenSigStartValue" INT 0 10000;
BA_DEF_ SG_  "GenSigSendType" ENUM  "Cyclic","OnWrite","reserved","OnChange","reserved","reserved","reserved","NoSigSendType";
BA_DEF_ SG_  "GenSigILSupport" ENUM  "Yes","No";
BA_DEF_ SG_  "GenSigEVName" STRING ;
BA_DEF_ SG_  "SPN" INT 0 524287;
BA_DEF_ BO_  "GenMsgStartDelayTime" INT 0 100000;
BA_DEF_ BO_  "GenMsgILSupport" ENUM  "Yes","No";
BA_DEF_ BO_  "GenMsgRequestable" INT 0 1;
BA_DEF_ BO_  "GenMsgSendType" ENUM  "cyclic","reserved","cyclicIfActive","reserved","reserved","reserved","reserved","reserved","noMsgSendType";
BA_DEF_ BO_  "VFrameFormat" ENUM  "StandardCAN","ExtendedCAN","reserved","J1939PG";
BA_DEF_ BO_  "GenMsgCycleTime" INT 0 3600000;
BA_DEF_ SG_  "SystemSignalLongSymbol" STRING ;
BA_DEF_DEF_  "SigType" "Default";
BA_DEF_DEF_  "GenSigStartValue" 0;
BA_DEF_DEF_  "GenSigSendType" "NoSigSendType";
BA_DEF_DEF_  "GenSigILSupport" "Yes";
BA_DEF_DEF_  "GenSigEVName" "Env@Nodename_@Signame";
BA_DEF_DEF_  "SPN" 0;
BA_DEF_DEF_  "GenMsgStartDelayTime" 0;
BA_DEF_DEF_  "GenMsgILSupport" "Yes";
BA_DEF_DEF_  "GenMsgRequestable" 1;
BA_DEF_DEF_  "GenMsgSendType" "noMsgSendType";
BA_DEF_DEF_  "VFrameFormat" "J1939PG";
BA_DEF_DEF_  "GenMsgCycleTime" 0;
BA_DEF_DEF_  "SystemSignalLongSymbol" "";
BA_ "GenMsgCycleTime" BO_ 2566746366 1000;
BA_ "GenMsgSendType" BO_ 2566755582 0;
BA_ "GenMsgCycleTime" BO_ 2566755582 100;
BA_ "GenMsgSendType" BO_ 2566752510 0;
BA_ "GenMsgCycleTime" BO_ 2566752510 500;
BA_ "GenMsgSendType" BO_ 2566752254 0;
BA_ "GenMsgCycleTime" BO_ 2566752254 500;
BA_ "GenMsgSendType" BO_ 2566751998 0;
BA_ "GenMsgCycleTime" BO_ 2566751998 500;
BA_ "GenMsgSendType" BO_ 2566751742 0;
BA_ "GenMsgCycleTime" BO_ 2566751742 500;
BA_ "GenMsgSendType" BO_ 2566751486 0;
BA_ "GenMsgCycleTime" BO_ 2566751486 500;
BA_ "GenMsgSendType" BO_ 2499641854 0;
BA_ "GenMsgCycleTime" BO_ 2499641854 500;
BA_ "GenMsgSendType" BO_ 2565873150 0;
BA_ "GenMsgCycleTime" BO_ 2565873150 10;
BA_ "GenMsgSendType" BO_ 2566751230 0;
BA_ "GenMsgCycleTime" BO_ 2566751230 1000;
BA_ "GenMsgSendType" BO_ 2566755838 0;
BA_ "GenMsgCycleTime" BO_ 2566755838 1000;
BA_ "GenMsgSendType" BO_ 2365485822 0;
BA_ "GenMsgCycleTime" BO_ 2365485822 50;
BA_ "GenMsgSendType" BO_ 2566768894 0;
BA_ "GenMsgCycleTime" BO_ 2566768894 1000;
BA_ "GenMsgSendType" BO_ 2566769406 0;
BA_ "GenMsgCycleTime" BO_ 2566769406 1000;
BA_ "GenMsgSendType" BO_ 2633934334 0;
BA_ "GenMsgCycleTime" BO_ 2633934334 1000;
BA_ "GenMsgSendType" BO_ 2566825726 0;
BA_ "GenMsgCycleTime" BO_ 2566825726 500;
BA_ "GenMsgSendType" BO_ 2566770942 0;
BA_ "GenMsgCycleTime" BO_ 2566770942 500;
BA_ "GenMsgSendType" BO_ 2566846206 0;
BA_ "GenMsgCycleTime" BO_ 2566846206 500;
BA_ "GenMsgSendType" BO_ 2566811134 0;
BA_ "GenMsgCycleTime" BO_ 2566811134 1000;
BA_ "GenMsgSendType" BO_ 2298375934 0;
BA_ "GenMsgCycleTime" BO_ 2298375934 20;
BA_ "GenMsgSendType" BO_ 2565867774 0;
BA_ "GenMsgCycleTime" BO_ 2565867774 50;
BA_ "GenMsgSendType" BO_ 2365449982 0;
BA_ "GenMsgCycleTime" BO_ 2365449982 100;
BA_ "GenMsgSendType" BO_ 2566757630 0;
BA_ "GenMsgCycleTime" BO_ 2566757630 1000;
BA_ "GenMsgSendType" BO_ 2566757886 0;
BA_ "GenMsgCycleTime" BO_ 2566757886 1000;
BA_ "GenMsgSendType" BO_ 2566759678 0;
BA_ "GenMsgCycleTime" BO_ 2566759678 100;
BA_ "GenMsgSendType" BO_ 2432541438 0;
BA_ "GenMsgCycleTime" BO_ 2432541438 500;
BA_ "GenMsgSendType" BO_ 2566761214 0;
BA_ "GenMsgCycleTime" BO_ 2566761214 500;
BA_ "GenMsgSendType" BO_ 2432541694 0;
BA_ "GenMsgCycleTime" BO_ 2432541694 100;
BA_ "GenMsgSendType" BO_ 2566759934 0;
BA_ "GenMsgCycleTime" BO_ 2566759934 100;
BA_ "GenMsgSendType" BO_ 2566757374 0;
BA_ "GenMsgCycleTime" BO_ 2566757374 1000;
BA_ "GenMsgSendType" BO_ 2364546302 0;
BA_ "GenMsgCycleTime" BO_ 2364546302 100;
BA_ "GenMsgSendType" BO_ 2431654654 0;
BA_ "GenMsgCycleTime" BO_ 2431654654 50;
BA_ "GenMsgSendType" BO_ 2364545534 0;
BA_ "GenMsgCycleTime" BO_ 2364545534 5000;
BA_ "GenMsgSendType" BO_ 2364545278 0;
BA_ "GenMsgCycleTime" BO_ 2364545278 5000;
BA_ "GenMsgSendType" BO_ 2364545022 0;
BA_ "GenMsgCycleTime" BO_ 2364545022 5000;
BA_ "GenMsgSendType" BO_ 2364544766 0;
BA_ "GenMsgCycleTime" BO_ 2364544766 5000;
BA_ "GenMsgSendType" BO_ 2364544510 0;
BA_ "GenMsgCycleTime" BO_ 2364544510 100;
BA_ "GenMsgSendType" BO_ 2364544254 0;
BA_ "GenMsgCycleTime" BO_ 2364544254 50;
BA_ "GenMsgSendType" BO_ 2349006590 0;
BA_ "GenMsgCycleTime" BO_ 2349006590 10;
BA_ "GenMsgSendType" BO_ 2566834686 0;
BA_ "GenMsgCycleTime" BO_ 2566834686 100;
BA_ "GenMsgSendType" BO_ 2550398718 0;
BA_ "GenMsgCycleTime" BO_ 2550398718 10;
BA_ "GenMsgSendType" BO_ 2566833406 0;
BA_ "GenMsgCycleTime" BO_ 2566833406 100;
BA_ "GenMsgSendType" BO_ 2365507326 0;
BA_ "GenMsgCycleTime" BO_ 2365507326 100;
BA_ "GenMsgSendType" BO_ 2565013246 0;
BA_ "GenMsgCycleTime" BO_ 2565013246 100;
BA_ "GenMsgSendType" BO_ 2566807038 0;
BA_ "GenMsgCycleTime" BO_ 2566807038 500;
BA_ "GenMsgSendType" BO_ 2365480958 0;
BA_ "GenMsgCycleTime" BO_ 2365480958 50;
BA_ "GenMsgSendType" BO_ 2566808062 0;
BA_ "GenMsgCycleTime" BO_ 2566808062 100;
BA_ "SigType" SG_ 2561212158 TextDisplayIndex 1;
BA_ "SPN" SG_ 2561212158 TextDisplayIndex 3614;
BA_ "SigType" SG_ 2561212158 TextDisplayInstructions 4;
BA_ "SPN" SG_ 2561212158 TextDisplayInstructions 3613;
BA_ "SigType" SG_ 2566746366 RetractStatusOfRamp5 4;
BA_ "SPN" SG_ 2566746366 RetractStatusOfRamp5 4457;
BA_ "SigType" SG_ 2566746366 RetractStatusOfRamp4 4;
BA_ "SPN" SG_ 2566746366 RetractStatusOfRamp4 4454;
BA_ "SigType" SG_ 2566746366 MovementStatusOfRamp5 4;
BA_ "SPN" SG_ 2566746366 MovementStatusOfRamp5 4459;
BA_ "SigType" SG_ 2566746366 MovementStatusOfRamp4 4;
BA_ "SPN" SG_ 2566746366 MovementStatusOfRamp4 4456;
BA_ "SigType" SG_ 2566746366 EnableStatusOfRamp5 4;
BA_ "SPN" SG_ 2566746366 EnableStatusOfRamp5 4458;
BA_ "SigType" SG_ 2566746366 EnableStatusOfRamp4 4;
BA_ "SPN" SG_ 2566746366 EnableStatusOfRamp4 4455;
BA_ "SigType" SG_ 2566746366 MovementStatusOfRamp3 4;
BA_ "SPN" SG_ 2566746366 MovementStatusOfRamp3 3818;
BA_ "SigType" SG_ 2566746366 EnableStatusOfRamp3 4;
BA_ "SPN" SG_ 2566746366 EnableStatusOfRamp3 3817;
BA_ "SigType" SG_ 2566746366 RetractStatusOfRamp3 4;
BA_ "SPN" SG_ 2566746366 RetractStatusOfRamp3 3816;
BA_ "SigType" SG_ 2566746366 MovementStatusOfRamp2 4;
BA_ "SPN" SG_ 2566746366 MovementStatusOfRamp2 3815;
BA_ "SigType" SG_ 2566746366 EnableStatusOfRamp2 4;
BA_ "SPN" SG_ 2566746366 EnableStatusOfRamp2 3814;
BA_ "SigType" SG_ 2566746366 RetractStatusOfRamp2 4;
BA_ "SPN" SG_ 2566746366 RetractStatusOfRamp2 3813;
BA_ "SigType" SG_ 2566746366 MovementStatusOfRamp1 4;
BA_ "SPN" SG_ 2566746366 MovementStatusOfRamp1 3812;
BA_ "SigType" SG_ 2566746366 EnableStatusOfRamp1 4;
BA_ "SPN" SG_ 2566746366 EnableStatusOfRamp1 3811;
BA_ "SigType" SG_ 2566746366 RetractStatusOfRamp1 4;
BA_ "SPN" SG_ 2566746366 RetractStatusOfRamp1 3810;
BA_ "SigType" SG_ 2566750206 MaxCrankAttemptsPerStartAttempt 1;
BA_ "SPN" SG_ 2566750206 MaxCrankAttemptsPerStartAttempt 3670;
BA_ "SigType" SG_ 2566755582 EngExhstGsRcrculation1Valve2Pos 1;
BA_ "SPN" SG_ 2566755582 EngExhstGsRcrculation1Valve2Pos 3822;
BA_ "SigType" SG_ 2566755582 EngExhstGsRcirculation1ValvePos 1;
BA_ "SPN" SG_ 2566755582 EngExhstGsRcirculation1ValvePos 27;
BA_ "SigType" SG_ 2566755582 EngCrnkcsBrthrOilSeparatorSpeed 1;
BA_ "SPN" SG_ 2566755582 EngCrnkcsBrthrOilSeparatorSpeed 5444;
BA_ "SigType" SG_ 2566755582 CmdedEngIntakeManifoldPress 1;
BA_ "SPN" SG_ 2566755582 CmdedEngIntakeManifoldPress 5312;
BA_ "SigType" SG_ 2566746110 EngExhstGsRcrcltn1ClrIntkGsAbsPr 1;
BA_ "SPN" SG_ 2566746110 EngExhstGsRcrcltn1ClrIntkGsAbsPr 4751;
BA_ "SystemSignalLongSymbol" SG_ 2566746110 EngExhstGsRcrcltn1ClrIntkGsAbsPr "EngExhstGsRcrcltn1ClrIntkGsAbsPrss";
BA_ "SigType" SG_ 2566746110 EngExhstGsRcrcltn1ClrIntakeTemp 1;
BA_ "SPN" SG_ 2566746110 EngExhstGsRcrcltn1ClrIntakeTemp 4750;
BA_ "SigType" SG_ 2566746110 EngExhstGsRcrcltn1ClrEfficiency 1;
BA_ "SPN" SG_ 2566746110 EngExhstGsRcrcltn1ClrEfficiency 4752;
BA_ "SigType" SG_ 2566746110 EngExhstGsRcrclation1Valve2Ctrl 1;
BA_ "SPN" SG_ 2566746110 EngExhstGsRcrclation1Valve2Ctrl 3821;
BA_ "SigType" SG_ 2566752510 EngIntkVlvActtonOilPressForCyl4 1;
BA_ "SPN" SG_ 2566752510 EngIntkVlvActtonOilPressForCyl4 3627;
BA_ "SigType" SG_ 2566752510 EngIntkVlvActtonOilPressForCyl3 1;
BA_ "SPN" SG_ 2566752510 EngIntkVlvActtonOilPressForCyl3 3626;
BA_ "SigType" SG_ 2566752510 EngIntkVlvActtonOilPressForCyl2 1;
BA_ "SPN" SG_ 2566752510 EngIntkVlvActtonOilPressForCyl2 3625;
BA_ "SigType" SG_ 2566752510 EngIntkVlvActtonOilPressForCyl1 1;
BA_ "SPN" SG_ 2566752510 EngIntkVlvActtonOilPressForCyl1 3624;
BA_ "SigType" SG_ 2566752254 EngIntkVlvActtonOilPressForCyl8 1;
BA_ "SPN" SG_ 2566752254 EngIntkVlvActtonOilPressForCyl8 3631;
BA_ "SigType" SG_ 2566752254 EngIntkVlvActtonOilPressForCyl7 1;
BA_ "SPN" SG_ 2566752254 EngIntkVlvActtonOilPressForCyl7 3630;
BA_ "SigType" SG_ 2566752254 EngIntkVlvActtonOilPressForCyl6 1;
BA_ "SPN" SG_ 2566752254 EngIntkVlvActtonOilPressForCyl6 3629;
BA_ "SigType" SG_ 2566752254 EngIntkVlvActtonOilPressForCyl5 1;
BA_ "SPN" SG_ 2566752254 EngIntkVlvActtonOilPressForCyl5 3628;
BA_ "SigType" SG_ 2566751998 EngIntkVlvActtnOilPressForCyl12 1;
BA_ "SPN" SG_ 2566751998 EngIntkVlvActtnOilPressForCyl12 3635;
BA_ "SigType" SG_ 2566751998 EngIntkVlvActtnOilPressForCyl11 1;
BA_ "SPN" SG_ 2566751998 EngIntkVlvActtnOilPressForCyl11 3634;
BA_ "SigType" SG_ 2566751998 EngIntkVlvActtnOilPressForCyl10 1;
BA_ "SPN" SG_ 2566751998 EngIntkVlvActtnOilPressForCyl10 3633;
BA_ "SigType" SG_ 2566751998 EngIntkVlvActtonOilPressForCyl9 1;
BA_ "SPN" SG_ 2566751998 EngIntkVlvActtonOilPressForCyl9 3632;
BA_ "SigType" SG_ 2566751742 EngIntkVlvActtnOilPressForCyl16 1;
BA_ "SPN" SG_ 2566751742 EngIntkVlvActtnOilPressForCyl16 3639;
BA_ "SigType" SG_ 2566751742 EngIntkVlvActtnOilPressForCyl15 1;
BA_ "SPN" SG_ 2566751742 EngIntkVlvActtnOilPressForCyl15 3638;
BA_ "SigType" SG_ 2566751742 EngIntkVlvActtnOilPressForCyl14 1;
BA_ "SPN" SG_ 2566751742 EngIntkVlvActtnOilPressForCyl14 3637;
BA_ "SigType" SG_ 2566751742 EngIntkVlvActtnOilPressForCyl13 1;
BA_ "SPN" SG_ 2566751742 EngIntkVlvActtnOilPressForCyl13 3636;
BA_ "SigType" SG_ 2566751486 EngIntkVlvActtnOilPressForCyl20 1;
BA_ "SPN" SG_ 2566751486 EngIntkVlvActtnOilPressForCyl20 3643;
BA_ "SigType" SG_ 2566751486 EngIntkVlvActtnOilPressForCyl19 1;
BA_ "SPN" SG_ 2566751486 EngIntkVlvActtnOilPressForCyl19 3642;
BA_ "SigType" SG_ 2566751486 EngIntkVlvActtnOilPressForCyl18 1;
BA_ "SPN" SG_ 2566751486 EngIntkVlvActtnOilPressForCyl18 3641;
BA_ "SigType" SG_ 2566751486 EngIntkVlvActtnOilPressForCyl17 1;
BA_ "SPN" SG_ 2566751486 EngIntkVlvActtnOilPressForCyl17 3640;
BA_ "SigType" SG_ 2499641854 EGR1CoolerBypassActuatorPostion 1;
BA_ "SPN" SG_ 2499641854 EGR1CoolerBypassActuatorPostion 3672;
BA_ "SigType" SG_ 2566748158 EngSparkPlug4 1;
BA_ "SPN" SG_ 2566748158 EngSparkPlug4 1297;
BA_ "SigType" SG_ 2566748158 EngSparkPlug3 1;
BA_ "SPN" SG_ 2566748158 EngSparkPlug3 1296;
BA_ "SigType" SG_ 2566748158 EngSparkPlug2 1;
BA_ "SPN" SG_ 2566748158 EngSparkPlug2 1295;
BA_ "SigType" SG_ 2566748158 EngSparkPlug1 1;
BA_ "SPN" SG_ 2566748158 EngSparkPlug1 1294;
BA_ "SigType" SG_ 2566747902 EngSparkPlug8 1;
BA_ "SPN" SG_ 2566747902 EngSparkPlug8 1301;
BA_ "SigType" SG_ 2566747902 EngSparkPlug7 1;
BA_ "SPN" SG_ 2566747902 EngSparkPlug7 1300;
BA_ "SigType" SG_ 2566747902 EngSparkPlug6 1;
BA_ "SPN" SG_ 2566747902 EngSparkPlug6 1299;
BA_ "SigType" SG_ 2566747902 EngSparkPlug5 1;
BA_ "SPN" SG_ 2566747902 EngSparkPlug5 1298;
BA_ "SigType" SG_ 2566747646 EngSparkPlug12 1;
BA_ "SPN" SG_ 2566747646 EngSparkPlug12 1305;
BA_ "SigType" SG_ 2566747646 EngSparkPlug11 1;
BA_ "SPN" SG_ 2566747646 EngSparkPlug11 1304;
BA_ "SigType" SG_ 2566747646 EngSparkPlug10 1;
BA_ "SPN" SG_ 2566747646 EngSparkPlug10 1303;
BA_ "SigType" SG_ 2566747646 EngSparkPlug9 1;
BA_ "SPN" SG_ 2566747646 EngSparkPlug9 1302;
BA_ "SigType" SG_ 2566747390 EngSparkPlug16 1;
BA_ "SPN" SG_ 2566747390 EngSparkPlug16 1309;
BA_ "SigType" SG_ 2566747390 EngSparkPlug15 1;
BA_ "SPN" SG_ 2566747390 EngSparkPlug15 1308;
BA_ "SigType" SG_ 2566747390 EngSparkPlug14 1;
BA_ "SPN" SG_ 2566747390 EngSparkPlug14 1307;
BA_ "SigType" SG_ 2566747390 EngSparkPlug13 1;
BA_ "SPN" SG_ 2566747390 EngSparkPlug13 1306;
BA_ "SigType" SG_ 2566747134 EngSparkPlug20 1;
BA_ "SPN" SG_ 2566747134 EngSparkPlug20 1313;
BA_ "SigType" SG_ 2566747134 EngSparkPlug19 1;
BA_ "SPN" SG_ 2566747134 EngSparkPlug19 1312;
BA_ "SigType" SG_ 2566747134 EngSparkPlug18 1;
BA_ "SPN" SG_ 2566747134 EngSparkPlug18 1311;
BA_ "SigType" SG_ 2566747134 EngSparkPlug17 1;
BA_ "SPN" SG_ 2566747134 EngSparkPlug17 1310;
BA_ "SigType" SG_ 2566746878 EngSparkPlug24 1;
BA_ "SPN" SG_ 2566746878 EngSparkPlug24 1317;
BA_ "SigType" SG_ 2566746878 EngSparkPlug23 1;
BA_ "SPN" SG_ 2566746878 EngSparkPlug23 1316;
BA_ "SigType" SG_ 2566746878 EngSparkPlug22 1;
BA_ "SPN" SG_ 2566746878 EngSparkPlug22 1315;
BA_ "SigType" SG_ 2566746878 EngSparkPlug21 1;
BA_ "SPN" SG_ 2566746878 EngSparkPlug21 1314;
BA_ "SigType" SG_ 2561277694 LaneDepartureWarningEnableCmd 4;
BA_ "SPN" SG_ 2561277694 LaneDepartureWarningEnableCmd 3564;
BA_ "SPN" SG_ 2633861886 J2012DTCOccurrenceCount 3622;
BA_ "SPN" SG_ 2633861886 J2012DTCStatus 3621;
BA_ "SigType" SG_ 2633861886 NumberOfJ2012DTCs 1;
BA_ "SPN" SG_ 2633861886 NumberOfJ2012DTCs 3619;
BA_ "SigType" SG_ 2565873150 MessageChecksum 4;
BA_ "SPN" SG_ 2565873150 MessageChecksum 3690;
BA_ "SigType" SG_ 2565873150 MessageCounter 4;
BA_ "SPN" SG_ 2565873150 MessageCounter 3689;
BA_ "SigType" SG_ 2565873150 SteerAngleSensorCalibrated 4;
BA_ "SPN" SG_ 2565873150 SteerAngleSensorCalibrated 3688;
BA_ "SigType" SG_ 2565873150 SteerAngleSensorActiveMode 4;
BA_ "SPN" SG_ 2565873150 SteerAngleSensorActiveMode 3687;
BA_ "SigType" SG_ 2565873150 SteerWheelAngleRange 1;
BA_ "SPN" SG_ 2565873150 SteerWheelAngleRange 3686;
BA_ "SigType" SG_ 2565873150 SteerWheelAngleRangeCounterType 4;
BA_ "SPN" SG_ 2565873150 SteerWheelAngleRangeCounterType 3685;
BA_ "SPN" SG_ 2565873150 SteerWheelAngleRangeCounter 3684;
BA_ "SigType" SG_ 2565873150 SteerWheelAngle 1;
BA_ "SPN" SG_ 2565873150 SteerWheelAngle 3683;
BA_ "SigType" SG_ 2566745854 Aftrtrtmnt1SCRCtlystCnvrsnEffcnc 1;
BA_ "SPN" SG_ 2566745854 Aftrtrtmnt1SCRCtlystCnvrsnEffcnc 4364;
BA_ "SystemSignalLongSymbol" SG_ 2566745854 Aftrtrtmnt1SCRCtlystCnvrsnEffcnc "Aftrtrtmnt1SCRCtlystCnvrsnEffcncy";
BA_ "SigType" SG_ 2566745854 Aftrtrtmnt1SCRCmddCtlystRgntCnsm 1;
BA_ "SPN" SG_ 2566745854 Aftrtrtmnt1SCRCmddCtlystRgntCnsm 3828;
BA_ "SystemSignalLongSymbol" SG_ 2566745854 Aftrtrtmnt1SCRCmddCtlystRgntCnsm "Aftrtrtmnt1SCRCmddCtlystRgntCnsmptn";
BA_ "SigType" SG_ 2566745854 Aftrtrtmnt1SCRAvrgCtlystRgntCnsm 1;
BA_ "SPN" SG_ 2566745854 Aftrtrtmnt1SCRAvrgCtlystRgntCnsm 3826;
BA_ "SystemSignalLongSymbol" SG_ 2566745854 Aftrtrtmnt1SCRAvrgCtlystRgntCnsm "Aftrtrtmnt1SCRAvrgCtlystRgntCnsmptn";
BA_ "SigType" SG_ 2566745854 Aftrtrtmnt1DslExhstFldTnkLwLvlIn 1;
BA_ "SPN" SG_ 2566745854 Aftrtrtmnt1DslExhstFldTnkLwLvlIn 5463;
BA_ "SystemSignalLongSymbol" SG_ 2566745854 Aftrtrtmnt1DslExhstFldTnkLwLvlIn "Aftrtrtmnt1DslExhstFldTnkLwLvlIndctrTrvldDstnc";
BA_ "SPN" SG_ 2566751230 TransferCaseStatus 3645;
BA_ "SigType" SG_ 2566755838 TrnsTrqueConverterOilOutletTemp 1;
BA_ "SPN" SG_ 2566755838 TrnsTrqueConverterOilOutletTemp 3823;
BA_ "SigType" SG_ 2566755838 TransOverheatIndicator 4;
BA_ "SPN" SG_ 2566755838 TransOverheatIndicator 5345;
BA_ "SigType" SG_ 2566755838 TransOilLifeRemaining 1;
BA_ "SPN" SG_ 2566755838 TransOilLifeRemaining 4177;
BA_ "SigType" SG_ 2566755838 TransOilLevelSwitch 4;
BA_ "SPN" SG_ 2566755838 TransOilLevelSwitch 3533;
BA_ "SigType" SG_ 2566755838 TransOilFilterRestrictionSwitch 4;
BA_ "SPN" SG_ 2566755838 TransOilFilterRestrictionSwitch 3359;
BA_ "SigType" SG_ 2566752766 VehicleRoll 1;
BA_ "SPN" SG_ 2566752766 VehicleRoll 3623;
BA_ "SigType" SG_ 2633938942 TotalEngCruiseTime 1;
BA_ "SPN" SG_ 2633938942 TotalEngCruiseTime 1017;
BA_ "SigType" SG_ 2633938942 TotalDriveAverageLoadFactor 1;
BA_ "SPN" SG_ 2633938942 TotalDriveAverageLoadFactor 1016;
BA_ "SigType" SG_ 2633938942 TripDriveAverageLoadFactor 1;
BA_ "SPN" SG_ 2633938942 TripDriveAverageLoadFactor 1015;
BA_ "SigType" SG_ 2633938942 TripAverageEngSpeed 1;
BA_ "SPN" SG_ 2633938942 TripAverageEngSpeed 1014;
BA_ "SigType" SG_ 2633938942 TripMaxEngSpeed 1;
BA_ "SPN" SG_ 2633938942 TripMaxEngSpeed 1013;
BA_ "SigType" SG_ 2566799614 ImplementRearWorkLight 4;
BA_ "SPN" SG_ 2566799614 ImplementRearWorkLight 2394;
BA_ "SigType" SG_ 2566799614 ImplementLeftForwardWorkLight 4;
BA_ "SPN" SG_ 2566799614 ImplementLeftForwardWorkLight 2400;
BA_ "SigType" SG_ 2566799614 ImplementRightForwardWorkLight 4;
BA_ "SPN" SG_ 2566799614 ImplementRightForwardWorkLight 2402;
BA_ "SigType" SG_ 2566799614 ImplementLeftFacingWorkLight 4;
BA_ "SPN" SG_ 2566799614 ImplementLeftFacingWorkLight 2598;
BA_ "SigType" SG_ 2566799614 ImplementRightFacingWorkLight 4;
BA_ "SPN" SG_ 2566799614 ImplementRightFacingWorkLight 2407;
BA_ "SigType" SG_ 2566799614 ImplementOEMOption1Light 4;
BA_ "SPN" SG_ 2566799614 ImplementOEMOption1Light 2396;
BA_ "SigType" SG_ 2566799614 ImplementOEMOption2Light 4;
BA_ "SPN" SG_ 2566799614 ImplementOEMOption2Light 2398;
BA_ "SigType" SG_ 2566799614 TrctrFrontHighMountedWorkLights 4;
BA_ "SPN" SG_ 2566799614 TrctrFrontHighMountedWorkLights 2356;
BA_ "SigType" SG_ 2566799614 TrctorFrontLowMountedWorkLights 4;
BA_ "SPN" SG_ 2566799614 TrctorFrontLowMountedWorkLights 2354;
BA_ "SigType" SG_ 2566799614 TrctorSideHighMountedWorkLights 4;
BA_ "SPN" SG_ 2566799614 TrctorSideHighMountedWorkLights 2366;
BA_ "SigType" SG_ 2566799614 TractorSideLowMountedWorkLights 4;
BA_ "SPN" SG_ 2566799614 TractorSideLowMountedWorkLights 2364;
BA_ "SigType" SG_ 2566799614 TrctorRearHighMountedWorkLights 4;
BA_ "SPN" SG_ 2566799614 TrctorRearHighMountedWorkLights 2362;
BA_ "SigType" SG_ 2566799614 TractorRearLowMountedWorkLights 4;
BA_ "SPN" SG_ 2566799614 TractorRearLowMountedWorkLights 2360;
BA_ "SigType" SG_ 2566799614 TrctrUndersideMountedWorkLights 4;
BA_ "SPN" SG_ 2566799614 TrctrUndersideMountedWorkLights 2358;
BA_ "SigType" SG_ 2566799614 RearFogLights 4;
BA_ "SPN" SG_ 2566799614 RearFogLights 2390;
BA_ "SigType" SG_ 2566799614 TractorMarkerLight 4;
BA_ "SPN" SG_ 2566799614 TractorMarkerLight 2378;
BA_ "SigType" SG_ 2566799614 ImplementMarkerLight 4;
BA_ "SPN" SG_ 2566799614 ImplementMarkerLight 2380;
BA_ "SigType" SG_ 2566799614 TractorClearanceLight 4;
BA_ "SPN" SG_ 2566799614 TractorClearanceLight 2382;
BA_ "SigType" SG_ 2566799614 ImplementClearanceLight 4;
BA_ "SPN" SG_ 2566799614 ImplementClearanceLight 2384;
BA_ "SigType" SG_ 2566799614 LeftStopLight 4;
BA_ "SPN" SG_ 2566799614 LeftStopLight 2372;
BA_ "SigType" SG_ 2566799614 RightStopLight 4;
BA_ "SPN" SG_ 2566799614 RightStopLight 2374;
BA_ "SigType" SG_ 2566799614 CenterStopLight 4;
BA_ "SPN" SG_ 2566799614 CenterStopLight 2376;
BA_ "SigType" SG_ 2566799614 BackUpLightAndAlarmHorn 4;
BA_ "SPN" SG_ 2566799614 BackUpLightAndAlarmHorn 2392;
BA_ "SigType" SG_ 2566799614 LeftTurnSignalLights 4;
BA_ "SPN" SG_ 2566799614 LeftTurnSignalLights 2368;
BA_ "SigType" SG_ 2566799614 RightTurnSignalLights 4;
BA_ "SPN" SG_ 2566799614 RightTurnSignalLights 2370;
BA_ "SigType" SG_ 2566799614 RotatingBeaconLight 4;
BA_ "SPN" SG_ 2566799614 RotatingBeaconLight 2386;
BA_ "SigType" SG_ 2566799614 TractorFrontFogLights 4;
BA_ "SPN" SG_ 2566799614 TractorFrontFogLights 2388;
BA_ "SigType" SG_ 2566799614 HighBeamHeadLightData 4;
BA_ "SPN" SG_ 2566799614 HighBeamHeadLightData 2348;
BA_ "SigType" SG_ 2566799614 LowBeamHeadLightData 4;
BA_ "SPN" SG_ 2566799614 LowBeamHeadLightData 2350;
BA_ "SigType" SG_ 2566799614 AltBeamHeadLightData 4;
BA_ "SPN" SG_ 2566799614 AltBeamHeadLightData 2352;
BA_ "SigType" SG_ 2566799614 RunningLight 4;
BA_ "SPN" SG_ 2566799614 RunningLight 2404;
BA_ "SigType" SG_ 2365473278 ImplementRearWorkLightCmd 4;
BA_ "SPN" SG_ 2365473278 ImplementRearWorkLightCmd 2405;
BA_ "SigType" SG_ 2365473278 ImplmentLeftForwardWorkLightCmd 4;
BA_ "SPN" SG_ 2365473278 ImplmentLeftForwardWorkLightCmd 2399;
BA_ "SigType" SG_ 2365473278 ImplmntRightForwardWorkLightCmd 4;
BA_ "SPN" SG_ 2365473278 ImplmntRightForwardWorkLightCmd 2401;
BA_ "SigType" SG_ 2365473278 LightingDataRqCmd 4;
BA_ "SPN" SG_ 2365473278 LightingDataRqCmd 2393;
BA_ "SigType" SG_ 2365473278 ImplementLeftFacingWorkLightCmd 4;
BA_ "SPN" SG_ 2365473278 ImplementLeftFacingWorkLightCmd 2597;
BA_ "SigType" SG_ 2365473278 ImplmentRightFacingWorkLightCmd 4;
BA_ "SPN" SG_ 2365473278 ImplmentRightFacingWorkLightCmd 2406;
BA_ "SigType" SG_ 2365473278 ImplementOEMOption1LightCmd 4;
BA_ "SPN" SG_ 2365473278 ImplementOEMOption1LightCmd 2395;
BA_ "SigType" SG_ 2365473278 ImplementOEMOption2LightCmd 4;
BA_ "SPN" SG_ 2365473278 ImplementOEMOption2LightCmd 2397;
BA_ "SigType" SG_ 2365473278 TrctrFrntHghMuntedWorkLightsCmd 4;
BA_ "SPN" SG_ 2365473278 TrctrFrntHghMuntedWorkLightsCmd 2355;
BA_ "SigType" SG_ 2365473278 TrctrFrntLwMountedWorkLightsCmd 4;
BA_ "SPN" SG_ 2365473278 TrctrFrntLwMountedWorkLightsCmd 2353;
BA_ "SigType" SG_ 2365473278 TrctrSdHighMountedWorkLightsCmd 4;
BA_ "SPN" SG_ 2365473278 TrctrSdHighMountedWorkLightsCmd 2365;
BA_ "SigType" SG_ 2365473278 TrctrSdeLowMountedWorkLightsCmd 4;
BA_ "SPN" SG_ 2365473278 TrctrSdeLowMountedWorkLightsCmd 2363;
BA_ "SigType" SG_ 2365473278 TrctrRrHighMountedWorkLightsCmd 4;
BA_ "SPN" SG_ 2365473278 TrctrRrHighMountedWorkLightsCmd 2361;
BA_ "SigType" SG_ 2365473278 TrctrRarLowMountedWorkLightsCmd 4;
BA_ "SPN" SG_ 2365473278 TrctrRarLowMountedWorkLightsCmd 2359;
BA_ "SigType" SG_ 2365473278 TrctrUndrsdMountedWorkLightsCmd 4;
BA_ "SPN" SG_ 2365473278 TrctrUndrsdMountedWorkLightsCmd 2357;
BA_ "SigType" SG_ 2365473278 RearFogLightCmd 4;
BA_ "SPN" SG_ 2365473278 RearFogLightCmd 2389;
BA_ "SigType" SG_ 2365473278 TractorMarkerLightCmd 4;
BA_ "SPN" SG_ 2365473278 TractorMarkerLightCmd 2377;
BA_ "SigType" SG_ 2365473278 ImplementMarkerLightCmd 4;
BA_ "SPN" SG_ 2365473278 ImplementMarkerLightCmd 2379;
BA_ "SigType" SG_ 2365473278 TractorClearanceLightCmd 4;
BA_ "SPN" SG_ 2365473278 TractorClearanceLightCmd 2381;
BA_ "SigType" SG_ 2365473278 ImplementClearanceLightCmd 4;
BA_ "SPN" SG_ 2365473278 ImplementClearanceLightCmd 2383;
BA_ "SigType" SG_ 2365473278 LeftStopLightCmd 4;
BA_ "SPN" SG_ 2365473278 LeftStopLightCmd 2371;
BA_ "SigType" SG_ 2365473278 RightStopLightCmd 4;
BA_ "SPN" SG_ 2365473278 RightStopLightCmd 2373;
BA_ "SigType" SG_ 2365473278 CenterStopLightCmd 4;
BA_ "SPN" SG_ 2365473278 CenterStopLightCmd 2375;
BA_ "SigType" SG_ 2365473278 BackUpLightAndAlarmHornCmd 4;
BA_ "SPN" SG_ 2365473278 BackUpLightAndAlarmHornCmd 2391;
BA_ "SigType" SG_ 2365473278 LeftTurnSignalLightsCmd 4;
BA_ "SPN" SG_ 2365473278 LeftTurnSignalLightsCmd 2367;
BA_ "SigType" SG_ 2365473278 RightTurnSignalLightsCmd 4;
BA_ "SPN" SG_ 2365473278 RightTurnSignalLightsCmd 2369;
BA_ "SigType" SG_ 2365473278 RotatingBeaconLightCmd 4;
BA_ "SPN" SG_ 2365473278 RotatingBeaconLightCmd 2385;
BA_ "SigType" SG_ 2365473278 TractorFrontFogLightsCmd 4;
BA_ "SPN" SG_ 2365473278 TractorFrontFogLightsCmd 2387;
BA_ "SigType" SG_ 2365473278 HighBeamHeadLightCmd 4;
BA_ "SPN" SG_ 2365473278 HighBeamHeadLightCmd 2347;
BA_ "SigType" SG_ 2365473278 LowBeamHeadLightCmd 4;
BA_ "SPN" SG_ 2365473278 LowBeamHeadLightCmd 2349;
BA_ "SigType" SG_ 2365473278 AltBeamHeadLightCmd 4;
BA_ "SPN" SG_ 2365473278 AltBeamHeadLightCmd 2351;
BA_ "SigType" SG_ 2365473278 RunningLightCmd 4;
BA_ "SPN" SG_ 2365473278 RunningLightCmd 2403;
BA_ "SigType" SG_ 2365485822 BladeCtrlMode 1;
BA_ "SPN" SG_ 2365485822 BladeCtrlMode 1578;
BA_ "SigType" SG_ 2365485822 BladeDurationAndDirection 1;
BA_ "SPN" SG_ 2365485822 BladeDurationAndDirection 1577;
BA_ "SigType" SG_ 2365485822 LandLevelingSystemEnableStatus 4;
BA_ "SPN" SG_ 2365485822 LandLevelingSystemEnableStatus 5409;
BA_ "SigType" SG_ 2365485822 BladeCtrlModeRight 4;
BA_ "SPN" SG_ 2365485822 BladeCtrlModeRight 5408;
BA_ "SigType" SG_ 2365485822 BladeCtrlModeLeft 4;
BA_ "SPN" SG_ 2365485822 BladeCtrlModeLeft 5407;
BA_ "SigType" SG_ 2633926654 EngActualIgntTiming 1;
BA_ "SPN" SG_ 2633926654 EngActualIgntTiming 1436;
BA_ "SigType" SG_ 2633926654 EngDesiredIgntTiming3 1;
BA_ "SPN" SG_ 2633926654 EngDesiredIgntTiming3 1435;
BA_ "SigType" SG_ 2633926654 EngDesiredIgntTiming2 1;
BA_ "SPN" SG_ 2633926654 EngDesiredIgntTiming2 1434;
BA_ "SigType" SG_ 2633926654 EngDesiredIgntTiming1 1;
BA_ "SPN" SG_ 2633926654 EngDesiredIgntTiming1 1433;
BA_ "SigType" SG_ 2633926398 EngCyl20IgntTiming 1;
BA_ "SPN" SG_ 2633926398 EngCyl20IgntTiming 1432;
BA_ "SigType" SG_ 2633926398 EngCyl19IgntTiming 1;
BA_ "SPN" SG_ 2633926398 EngCyl19IgntTiming 1431;
BA_ "SigType" SG_ 2633926398 EngCyl18IgntTiming 1;
BA_ "SPN" SG_ 2633926398 EngCyl18IgntTiming 1430;
BA_ "SigType" SG_ 2633926398 EngCyl17IgntTiming 1;
BA_ "SPN" SG_ 2633926398 EngCyl17IgntTiming 1429;
BA_ "SigType" SG_ 2633926142 EngCyl16IgntTiming 1;
BA_ "SPN" SG_ 2633926142 EngCyl16IgntTiming 1428;
BA_ "SigType" SG_ 2633926142 EngCyl15IgntTiming 1;
BA_ "SPN" SG_ 2633926142 EngCyl15IgntTiming 1427;
BA_ "SigType" SG_ 2633926142 EngCyl14IgntTiming 1;
BA_ "SPN" SG_ 2633926142 EngCyl14IgntTiming 1426;
BA_ "SigType" SG_ 2633926142 EngCyl13IgntTiming 1;
BA_ "SPN" SG_ 2633926142 EngCyl13IgntTiming 1425;
BA_ "SigType" SG_ 2633925886 EngCyl12IgntTiming 1;
BA_ "SPN" SG_ 2633925886 EngCyl12IgntTiming 1424;
BA_ "SigType" SG_ 2633925886 EngCyl11IgntTiming 1;
BA_ "SPN" SG_ 2633925886 EngCyl11IgntTiming 1423;
BA_ "SigType" SG_ 2633925886 EngCyl10IgntTiming 1;
BA_ "SPN" SG_ 2633925886 EngCyl10IgntTiming 1422;
BA_ "SigType" SG_ 2633925886 EngCyl9IgntTiming 1;
BA_ "SPN" SG_ 2633925886 EngCyl9IgntTiming 1421;
BA_ "SigType" SG_ 2633925630 EngCyl8IgntTiming 1;
BA_ "SPN" SG_ 2633925630 EngCyl8IgntTiming 1420;
BA_ "SigType" SG_ 2633925630 EngCyl7IgntTiming 1;
BA_ "SPN" SG_ 2633925630 EngCyl7IgntTiming 1419;
BA_ "SigType" SG_ 2633925630 EngCyl6IgntTiming 1;
BA_ "SPN" SG_ 2633925630 EngCyl6IgntTiming 1418;
BA_ "SigType" SG_ 2633925630 EngCyl5IgntTiming 1;
BA_ "SPN" SG_ 2633925630 EngCyl5IgntTiming 1417;
BA_ "SigType" SG_ 2633925374 EngCyl4IgntTiming 1;
BA_ "SPN" SG_ 2633925374 EngCyl4IgntTiming 1416;
BA_ "SigType" SG_ 2633925374 EngCyl3IgntTiming 1;
BA_ "SPN" SG_ 2633925374 EngCyl3IgntTiming 1415;
BA_ "SigType" SG_ 2633925374 EngCyl2IgntTiming 1;
BA_ "SPN" SG_ 2633925374 EngCyl2IgntTiming 1414;
BA_ "SigType" SG_ 2633925374 EngCyl1IgntTiming 1;
BA_ "SPN" SG_ 2633925374 EngCyl1IgntTiming 1413;
BA_ "SigType" SG_ 2633927422 EngCyl20IgntTransSecondOutput 1;
BA_ "SPN" SG_ 2633927422 EngCyl20IgntTransSecondOutput 1412;
BA_ "SigType" SG_ 2633927422 EngCyl19IgntTransSecondOutput 1;
BA_ "SPN" SG_ 2633927422 EngCyl19IgntTransSecondOutput 1411;
BA_ "SigType" SG_ 2633927422 EngCyl18IgntTransSecondOutput 1;
BA_ "SPN" SG_ 2633927422 EngCyl18IgntTransSecondOutput 1410;
BA_ "SigType" SG_ 2633927422 EngCyl17IgntTransSecondOutput 1;
BA_ "SPN" SG_ 2633927422 EngCyl17IgntTransSecondOutput 1409;
BA_ "SigType" SG_ 2633927166 EngCyl16IgntTransSecondOutput 1;
BA_ "SPN" SG_ 2633927166 EngCyl16IgntTransSecondOutput 1408;
BA_ "SigType" SG_ 2633927166 EngCyl15IgntTransSecondOutput 1;
BA_ "SPN" SG_ 2633927166 EngCyl15IgntTransSecondOutput 1407;
BA_ "SigType" SG_ 2633927166 EngCyl14IgntTransSecondOutput 1;
BA_ "SPN" SG_ 2633927166 EngCyl14IgntTransSecondOutput 1406;
BA_ "SigType" SG_ 2633927166 EngCyl13IgntTransSecondOutput 1;
BA_ "SPN" SG_ 2633927166 EngCyl13IgntTransSecondOutput 1405;
BA_ "SigType" SG_ 2633927166 EngCyl12IgntTransSecondOutput 1;
BA_ "SPN" SG_ 2633927166 EngCyl12IgntTransSecondOutput 1404;
BA_ "SigType" SG_ 2633927166 EngCyl11IgntTransSecondOutput 1;
BA_ "SPN" SG_ 2633927166 EngCyl11IgntTransSecondOutput 1403;
BA_ "SigType" SG_ 2633927166 EngCyl10IgntTransSecondOutput 1;
BA_ "SPN" SG_ 2633927166 EngCyl10IgntTransSecondOutput 1402;
BA_ "SigType" SG_ 2633927166 EngCyl9IgntTransSecondOutput 1;
BA_ "SPN" SG_ 2633927166 EngCyl9IgntTransSecondOutput 1401;
BA_ "SigType" SG_ 2633926910 EngCyl8IgntTransSecondOutput 1;
BA_ "SPN" SG_ 2633926910 EngCyl8IgntTransSecondOutput 1400;
BA_ "SigType" SG_ 2633926910 EngCyl7IgntTransSecondOutput 1;
BA_ "SPN" SG_ 2633926910 EngCyl7IgntTransSecondOutput 1399;
BA_ "SigType" SG_ 2633926910 EngCyl6IgntTransSecondOutput 1;
BA_ "SPN" SG_ 2633926910 EngCyl6IgntTransSecondOutput 1398;
BA_ "SigType" SG_ 2633926910 EngCyl5IgntTransSecondOutput 1;
BA_ "SPN" SG_ 2633926910 EngCyl5IgntTransSecondOutput 1397;
BA_ "SigType" SG_ 2633926910 EngCyl4IgntTransSecondOutput 1;
BA_ "SPN" SG_ 2633926910 EngCyl4IgntTransSecondOutput 1396;
BA_ "SigType" SG_ 2633926910 EngCyl3IgntTransSecondOutput 1;
BA_ "SPN" SG_ 2633926910 EngCyl3IgntTransSecondOutput 1395;
BA_ "SigType" SG_ 2633926910 EngCyl2IgntTransSecondOutput 1;
BA_ "SPN" SG_ 2633926910 EngCyl2IgntTransSecondOutput 1394;
BA_ "SigType" SG_ 2633926910 EngCyl1IgntTransSecondOutput 1;
BA_ "SPN" SG_ 2633926910 EngCyl1IgntTransSecondOutput 1393;
BA_ "SigType" SG_ 2566768894 EngOprtrPrmryIntrmdtSpdSlctStte 4;
BA_ "SPN" SG_ 2566768894 EngOprtrPrmryIntrmdtSpdSlctStte 2892;
BA_ "SigType" SG_ 2566769406 EngOprtrPrmryIntrmdtSpeedSelect 4;
BA_ "SPN" SG_ 2566769406 EngOprtrPrmryIntrmdtSpeedSelect 2880;
BA_ "SigType" SG_ 2566839550 EngTotalIdleHours 1;
BA_ "SPN" SG_ 2566839550 EngTotalIdleHours 235;
BA_ "SigType" SG_ 2566839550 EngTotalIdleFuelUsed 1;
BA_ "SPN" SG_ 2566839550 EngTotalIdleFuelUsed 236;
BA_ "SigType" SG_ 2633934334 EngIntakeManifold6Temp 1;
BA_ "SPN" SG_ 2633934334 EngIntakeManifold6Temp 1803;
BA_ "SigType" SG_ 2633934334 EngIntakeManifold5Temp 1;
BA_ "SPN" SG_ 2633934334 EngIntakeManifold5Temp 1802;
BA_ "SigType" SG_ 2633934334 EngIntakeManifold4Temp 1;
BA_ "SPN" SG_ 2633934334 EngIntakeManifold4Temp 1133;
BA_ "SigType" SG_ 2633934334 EngIntakeManifold3Temp 1;
BA_ "SPN" SG_ 2633934334 EngIntakeManifold3Temp 1132;
BA_ "SigType" SG_ 2633934334 EngIntakeManifold2Temp 1;
BA_ "SPN" SG_ 2633934334 EngIntakeManifold2Temp 1131;
BA_ "SigType" SG_ 2566825726 EngTurbo4BoostPress 1;
BA_ "SPN" SG_ 2566825726 EngTurbo4BoostPress 1130;
BA_ "SigType" SG_ 2566825726 EngTurbo3BoostPress 1;
BA_ "SPN" SG_ 2566825726 EngTurbo3BoostPress 1129;
BA_ "SigType" SG_ 2566825726 EngTurbo2BoostPress 1;
BA_ "SPN" SG_ 2566825726 EngTurbo2BoostPress 1128;
BA_ "SigType" SG_ 2566825726 EngTurbo1BoostPress 1;
BA_ "SPN" SG_ 2566825726 EngTurbo1BoostPress 1127;
BA_ "SigType" SG_ 2566770942 EngAirFilter4DiffPress 1;
BA_ "SPN" SG_ 2566770942 EngAirFilter4DiffPress 2811;
BA_ "SigType" SG_ 2566770942 EngAirFilter3DiffPress 1;
BA_ "SPN" SG_ 2566770942 EngAirFilter3DiffPress 2810;
BA_ "SigType" SG_ 2566770942 EngAirFilter2DiffPress 1;
BA_ "SPN" SG_ 2566770942 EngAirFilter2DiffPress 2809;
BA_ "SigType" SG_ 2566770942 EngIntakeManifold1AbsPress 1;
BA_ "SPN" SG_ 2566770942 EngIntakeManifold1AbsPress 4817;
BA_ "SigType" SG_ 2566770942 EngIntakeManifold2AbsPress 1;
BA_ "SPN" SG_ 2566770942 EngIntakeManifold2AbsPress 5422;
BA_ "SigType" SG_ 2566770942 EngIntakeManifold2Press 1;
BA_ "SPN" SG_ 2566770942 EngIntakeManifold2Press 3562;
BA_ "SigType" SG_ 2566770942 EngIntakeManifold1AbsPressHiRes 1;
BA_ "SPN" SG_ 2566770942 EngIntakeManifold1AbsPressHiRes 4817;
BA_ "SigType" SG_ 2566846206 EngCoolantFilterDiffPress 1;
BA_ "SPN" SG_ 2566846206 EngCoolantFilterDiffPress 112;
BA_ "SigType" SG_ 2566846206 EngExhaustGasTemp 1;
BA_ "SPN" SG_ 2566846206 EngExhaustGasTemp 173;
BA_ "SigType" SG_ 2566846206 EngAirFilter1DiffPress 1;
BA_ "SPN" SG_ 2566846206 EngAirFilter1DiffPress 107;
BA_ "SigType" SG_ 2566846206 EngIntakeManifold1Temp 1;
BA_ "SPN" SG_ 2566846206 EngIntakeManifold1Temp 105;
BA_ "SigType" SG_ 2566846206 EngIntakeManifold1Press 1;
BA_ "SPN" SG_ 2566846206 EngIntakeManifold1Press 102;
BA_ "SigType" SG_ 2566846206 EngDslPrtclateFilterIntakePress 1;
BA_ "SPN" SG_ 2566846206 EngDslPrtclateFilterIntakePress 81;
BA_ "SigType" SG_ 2566846206 EngAirIntakePress 1;
BA_ "SPN" SG_ 2566846206 EngAirIntakePress 106;
BA_ "SigType" SG_ 2566811134 CabHeatingZone 4;
BA_ "SPN" SG_ 2566811134 CabHeatingZone 1680;
BA_ "SigType" SG_ 2566811134 EngHeatingZone 4;
BA_ "SPN" SG_ 2566811134 EngHeatingZone 1679;
BA_ "SigType" SG_ 2566811134 CabVentilation 4;
BA_ "SPN" SG_ 2566811134 CabVentilation 1678;
BA_ "SigType" SG_ 2566811134 AuxHeaterMode 4;
BA_ "SPN" SG_ 2566811134 AuxHeaterMode 1677;
BA_ "SigType" SG_ 2566811134 AuxHeaterOutputPowerPercent 1;
BA_ "SPN" SG_ 2566811134 AuxHeaterOutputPowerPercent 1689;
BA_ "SigType" SG_ 2566811134 AuxHeaterInputAirTemp 1;
BA_ "SPN" SG_ 2566811134 AuxHeaterInputAirTemp 1688;
BA_ "SigType" SG_ 2566811134 AuxHeaterOutputCoolantTemp 1;
BA_ "SPN" SG_ 2566811134 AuxHeaterOutputCoolantTemp 1687;
BA_ "SigType" SG_ 2566811134 AuxHeaterWaterPumpStatus 4;
BA_ "SPN" SG_ 2566811134 AuxHeaterWaterPumpStatus 1676;
BA_ "SigType" SG_ 2298375934 RearAxleRightWheelSpeed 1;
BA_ "SPN" SG_ 2298375934 RearAxleRightWheelSpeed 1595;
BA_ "SigType" SG_ 2298375934 RearAxleLeftWheelSpeed 1;
BA_ "SPN" SG_ 2298375934 RearAxleLeftWheelSpeed 1594;
BA_ "SigType" SG_ 2298375934 FrontAxleRightWheelSpeed 1;
BA_ "SPN" SG_ 2298375934 FrontAxleRightWheelSpeed 1593;
BA_ "SigType" SG_ 2298375934 FrontAxleLeftWheelSpeed 1;
BA_ "SPN" SG_ 2298375934 FrontAxleLeftWheelSpeed 1592;
BA_ "SigType" SG_ 2565867774 FireApparatusPumpEngagement 4;
BA_ "SPN" SG_ 2565867774 FireApparatusPumpEngagement 2599;
BA_ "SigType" SG_ 2565867774 EngHydPressGovernorSwitch 4;
BA_ "SPN" SG_ 2565867774 EngHydPressGovernorSwitch 1764;
BA_ "SigType" SG_ 2565867774 EngHydPrssGovernorModeIndicator 4;
BA_ "SPN" SG_ 2565867774 EngHydPrssGovernorModeIndicator 1763;
BA_ "SigType" SG_ 2565867774 HydPress 1;
BA_ "SPN" SG_ 2565867774 HydPress 1762;
BA_ "SigType" SG_ 2566841854 EngTotalRevolutions 1;
BA_ "SPN" SG_ 2566841854 EngTotalRevolutions 249;
BA_ "SigType" SG_ 2566841854 EngTotalHoursOfOperation 1;
BA_ "SPN" SG_ 2566841854 EngTotalHoursOfOperation 247;
BA_ "SigType" SG_ 2365449982 HydBrakeFluidLevelSwitch 4;
BA_ "SPN" SG_ 2365449982 HydBrakeFluidLevelSwitch 2931;
BA_ "SigType" SG_ 2365449982 HydBrakeSystemAudibleWarningCmd 4;
BA_ "SPN" SG_ 2365449982 HydBrakeSystemAudibleWarningCmd 2930;
BA_ "SigType" SG_ 2365449982 HydBrkePressSupplyStateCircuit2 4;
BA_ "SPN" SG_ 2365449982 HydBrkePressSupplyStateCircuit2 2583;
BA_ "SigType" SG_ 2365449982 HydBrkePressSupplyStateCircuit1 4;
BA_ "SPN" SG_ 2365449982 HydBrkePressSupplyStateCircuit1 2582;
BA_ "SigType" SG_ 2365449982 HydBrkPressWarningStateCircuit2 4;
BA_ "SPN" SG_ 2365449982 HydBrkPressWarningStateCircuit2 2585;
BA_ "SigType" SG_ 2365449982 HydBrkPressWarningStateCircuit1 4;
BA_ "SPN" SG_ 2365449982 HydBrkPressWarningStateCircuit1 2584;
BA_ "SigType" SG_ 2365449982 HydBrakePressCircuit2 1;
BA_ "SPN" SG_ 2365449982 HydBrakePressCircuit2 2581;
BA_ "SigType" SG_ 2365449982 HydBrakePressCircuit1 1;
BA_ "SPN" SG_ 2365449982 HydBrakePressCircuit1 2580;
BA_ "SigType" SG_ 2633939198 TripDriveFuelEconomy 1;
BA_ "SPN" SG_ 2633939198 TripDriveFuelEconomy 1012;
BA_ "SigType" SG_ 2633939198 TrpPTOGovernorNonmovingFuelUsed 1;
BA_ "SPN" SG_ 2633939198 TrpPTOGovernorNonmovingFuelUsed 1009;
BA_ "SigType" SG_ 2633939198 TripVehicleIdleFuelUsed 1;
BA_ "SPN" SG_ 2633939198 TripVehicleIdleFuelUsed 1010;
BA_ "SigType" SG_ 2633939198 TripCruiseFuelUsed 1;
BA_ "SPN" SG_ 2633939198 TripCruiseFuelUsed 1011;
BA_ "SigType" SG_ 2633939198 TripDriveFuelUsed 1;
BA_ "SPN" SG_ 2633939198 TripDriveFuelUsed 1007;
BA_ "SigType" SG_ 2633939198 TripPTOGovernorMovingFuelUsed 1;
BA_ "SPN" SG_ 2633939198 TripPTOGovernorMovingFuelUsed 1008;
BA_ "SigType" SG_ 2633927678 EngFuelValve1OutletAbsPress 1;
BA_ "SPN" SG_ 2633927678 EngFuelValve1OutletAbsPress 2980;
BA_ "SigType" SG_ 2633927678 EngAirToFuelDiffPress 1;
BA_ "SPN" SG_ 2633927678 EngAirToFuelDiffPress 1392;
BA_ "SigType" SG_ 2633927678 EngFuelValveDiffPress 1;
BA_ "SPN" SG_ 2633927678 EngFuelValveDiffPress 1391;
BA_ "SigType" SG_ 2633927678 EngFuelValve1IntakeAbsPress 1;
BA_ "SPN" SG_ 2633927678 EngFuelValve1IntakeAbsPress 1390;
BA_ "SigType" SG_ 2633925118 EngFuelFlowRate2 1;
BA_ "SPN" SG_ 2633925118 EngFuelFlowRate2 1441;
BA_ "SigType" SG_ 2633925118 EngFuelFlowRate1 1;
BA_ "SPN" SG_ 2633925118 EngFuelFlowRate1 1440;
BA_ "SigType" SG_ 2633925118 EngRqedFuelValve2Pos 1;
BA_ "SPN" SG_ 2633925118 EngRqedFuelValve2Pos 1766;
BA_ "SigType" SG_ 2633925118 EngRqedFuelValve1Pos 1;
BA_ "SPN" SG_ 2633925118 EngRqedFuelValve1Pos 1765;
BA_ "SigType" SG_ 2633925118 EngFuelValve2Pos 1;
BA_ "SPN" SG_ 2633925118 EngFuelValve2Pos 1443;
BA_ "SigType" SG_ 2633925118 EngFuelValve1Pos 1;
BA_ "SPN" SG_ 2633925118 EngFuelValve1Pos 1442;
BA_ "SigType" SG_ 2633937662 TotalEngPTOGovernorFuelUsed 1;
BA_ "SPN" SG_ 2633937662 TotalEngPTOGovernorFuelUsed 1030;
BA_ "SigType" SG_ 2633937662 TripAverageFuelRate 1;
BA_ "SPN" SG_ 2633937662 TripAverageFuelRate 1031;
BA_ "SigType" SG_ 2633937662 EngFuelSpecificGravity 1;
BA_ "SPN" SG_ 2633937662 EngFuelSpecificGravity 1389;
BA_ "SigType" SG_ 2566804990 SpecificHeatRatio 1;
BA_ "SPN" SG_ 2566804990 SpecificHeatRatio 1767;
BA_ "SigType" SG_ 2633936894 TotalFuelUsed 1;
BA_ "SPN" SG_ 2633936894 TotalFuelUsed 1040;
BA_ "SigType" SG_ 2633936894 TripFuel 1;
BA_ "SPN" SG_ 2633936894 TripFuel 1039;
BA_ "SigType" SG_ 2566757630 SensorSupplyVoltage6 1;
BA_ "SPN" SG_ 2566757630 SensorSupplyVoltage6 3514;
BA_ "SigType" SG_ 2566757630 SensorSupplyVoltage5 1;
BA_ "SPN" SG_ 2566757630 SensorSupplyVoltage5 3513;
BA_ "SigType" SG_ 2566757630 SensorSupplyVoltage8 1;
BA_ "SPN" SG_ 2566757630 SensorSupplyVoltage8 5126;
BA_ "SigType" SG_ 2566757630 SensorSupplyVoltage7 1;
BA_ "SPN" SG_ 2566757630 SensorSupplyVoltage7 5125;
BA_ "SigType" SG_ 2566757886 SensorSupplyVoltage4 1;
BA_ "SPN" SG_ 2566757886 SensorSupplyVoltage4 3512;
BA_ "SigType" SG_ 2566757886 SensorSupplyVoltage3 1;
BA_ "SPN" SG_ 2566757886 SensorSupplyVoltage3 3511;
BA_ "SigType" SG_ 2566757886 SensorSupplyVoltage2 1;
BA_ "SPN" SG_ 2566757886 SensorSupplyVoltage2 3510;
BA_ "SigType" SG_ 2566757886 SensorSupplyVoltage1 1;
BA_ "SPN" SG_ 2566757886 SensorSupplyVoltage1 3509;
BA_ "SigType" SG_ 2566759678 EnggmntSttusTransInputShaftPTO1 4;
BA_ "SPN" SG_ 2566759678 EnggmntSttusTransInputShaftPTO1 3460;
BA_ "SigType" SG_ 2566759678 EnggmntSttusTransInputShaftPTO2 4;
BA_ "SPN" SG_ 2566759678 EnggmntSttusTransInputShaftPTO2 3461;
BA_ "SigType" SG_ 2566759678 EnggmntSttusTransOutputShaftPTO 4;
BA_ "SPN" SG_ 2566759678 EnggmntSttusTransOutputShaftPTO 3462;
BA_ "SigType" SG_ 2566759678 EnggmntSttsTrnsfrCsOtptShaftPTO 4;
BA_ "SPN" SG_ 2566759678 EnggmntSttsTrnsfrCsOtptShaftPTO 3463;
BA_ "SigType" SG_ 2566759678 EnggmntCnsntTransInputShaftPTO1 4;
BA_ "SPN" SG_ 2566759678 EnggmntCnsntTransInputShaftPTO1 3456;
BA_ "SigType" SG_ 2566759678 EnggmntCnsntTransInputShaftPTO2 4;
BA_ "SPN" SG_ 2566759678 EnggmntCnsntTransInputShaftPTO2 3457;
BA_ "SigType" SG_ 2566759678 EnggmntCnsntTransOutputShaftPTO 4;
BA_ "SPN" SG_ 2566759678 EnggmntCnsntTransOutputShaftPTO 3458;
BA_ "SigType" SG_ 2566759678 EnggmntCnsntTrnsfrCsOtptShftPTO 4;
BA_ "SPN" SG_ 2566759678 EnggmntCnsntTrnsfrCsOtptShftPTO 3459;
BA_ "SigType" SG_ 2566759678 EnableSwitchTransInputShaftPTO1 4;
BA_ "SPN" SG_ 2566759678 EnableSwitchTransInputShaftPTO1 3452;
BA_ "SigType" SG_ 2566759678 EnableSwitchTransInputShaftPTO2 4;
BA_ "SPN" SG_ 2566759678 EnableSwitchTransInputShaftPTO2 3453;
BA_ "SigType" SG_ 2566759678 EnableSwitchTransOutputShaftPTO 4;
BA_ "SPN" SG_ 2566759678 EnableSwitchTransOutputShaftPTO 3454;
BA_ "SigType" SG_ 2566759678 EnblSwtchTrnsfrCsOutputShaftPTO 4;
BA_ "SPN" SG_ 2566759678 EnblSwtchTrnsfrCsOutputShaftPTO 3455;
BA_ "SigType" SG_ 2566759678 EnggmntSttsPTOEngAccssoryDrive2 4;
BA_ "SPN" SG_ 2566759678 EnggmntSttsPTOEngAccssoryDrive2 3947;
BA_ "SigType" SG_ 2566759678 EnggmntSttsPTOEngAccssoryDrive1 4;
BA_ "SPN" SG_ 2566759678 EnggmntSttsPTOEngAccssoryDrive1 3944;
BA_ "SigType" SG_ 2566759678 EnggmntCnsntPTOEngAccssryDrive2 4;
BA_ "SPN" SG_ 2566759678 EnggmntCnsntPTOEngAccssryDrive2 3946;
BA_ "SigType" SG_ 2566759678 EnggmntCnsntPTOEngAccssryDrive1 4;
BA_ "SPN" SG_ 2566759678 EnggmntCnsntPTOEngAccssryDrive1 3943;
BA_ "SigType" SG_ 2566759678 EngagementStatusPTOEngFlywheel 4;
BA_ "SPN" SG_ 2566759678 EngagementStatusPTOEngFlywheel 3941;
BA_ "SigType" SG_ 2566759678 EngagementConsentPTOEngFlywheel 4;
BA_ "SPN" SG_ 2566759678 EngagementConsentPTOEngFlywheel 3940;
BA_ "SigType" SG_ 2566759678 EnblSwitchPTOEngAccessoryDrive2 4;
BA_ "SPN" SG_ 2566759678 EnblSwitchPTOEngAccessoryDrive2 3945;
BA_ "SigType" SG_ 2566759678 EnblSwitchPTOEngAccessoryDrive1 4;
BA_ "SPN" SG_ 2566759678 EnblSwitchPTOEngAccessoryDrive1 3942;
BA_ "SigType" SG_ 2566759678 EnableSwitchPTOEngFlywheel 4;
BA_ "SPN" SG_ 2566759678 EnableSwitchPTOEngFlywheel 3939;
BA_ "SigType" SG_ 2566759678 AtLeastOnePTOEngaged 4;
BA_ "SPN" SG_ 2566759678 AtLeastOnePTOEngaged 3948;
BA_ "SigType" SG_ 2432541438 EngFuelValve2OutletAbsPress 1;
BA_ "SPN" SG_ 2432541438 EngFuelValve2OutletAbsPress 3469;
BA_ "SigType" SG_ 2432541438 EngFuelTemp2 1;
BA_ "SPN" SG_ 2432541438 EngFuelTemp2 3468;
BA_ "SigType" SG_ 2432541438 EngGas2MassFlowRate 1;
BA_ "SPN" SG_ 2432541438 EngGas2MassFlowRate 3467;
BA_ "SigType" SG_ 2432541438 EngFuelValve2IntakeAbsPress 1;
BA_ "SPN" SG_ 2432541438 EngFuelValve2IntakeAbsPress 3466;
BA_ "SigType" SG_ 2566761214 EngCentrifugalOilFilterSpeed 1;
BA_ "SPN" SG_ 2566761214 EngCentrifugalOilFilterSpeed 3343;
BA_ "SigType" SG_ 2566761214 EngCoolantPumpDiffPress 1;
BA_ "SPN" SG_ 2566761214 EngCoolantPumpDiffPress 3342;
BA_ "SigType" SG_ 2566761214 EngChargeAirCooler2IntakePress 1;
BA_ "SPN" SG_ 2566761214 EngChargeAirCooler2IntakePress 3341;
BA_ "SigType" SG_ 2566761214 EngChargeAirCooler1IntakePress 1;
BA_ "SPN" SG_ 2566761214 EngChargeAirCooler1IntakePress 3340;
BA_ "SigType" SG_ 2566761214 EngIntercoolerCoolantLevel 1;
BA_ "SPN" SG_ 2566761214 EngIntercoolerCoolantLevel 3668;
BA_ "SigType" SG_ 2566761214 EngChargeAirCoolerOutletPress 1;
BA_ "SPN" SG_ 2566761214 EngChargeAirCoolerOutletPress 2631;
BA_ "SigType" SG_ 2566761214 EngAftercoolerCoolantLevel 1;
BA_ "SPN" SG_ 2566761214 EngAftercoolerCoolantLevel 3676;
BA_ "SigType" SG_ 2432541694 EngVrableGeometryTurboActuator1 1;
BA_ "SPN" SG_ 2432541694 EngVrableGeometryTurboActuator1 641;
BA_ "SigType" SG_ 2432541694 EngTrbCmprssrBypssActtr1TmpStts 4;
BA_ "SPN" SG_ 2432541694 EngTrbCmprssrBypssActtr1TmpStts 5368;
BA_ "SigType" SG_ 2432541694 EngTrbCmprssrBypssActtr1PrlmnryF 1;
BA_ "SPN" SG_ 2432541694 EngTrbCmprssrBypssActtr1PrlmnryF 5367;
BA_ "SystemSignalLongSymbol" SG_ 2432541694 EngTrbCmprssrBypssActtr1PrlmnryF "EngTrbCmprssrBypssActtr1PrlmnryFMI";
BA_ "SigType" SG_ 2432541694 EngTrbCmprssrBypassActuator2Cmd 1;
BA_ "SPN" SG_ 2432541694 EngTrbCmprssrBypassActuator2Cmd 5369;
BA_ "SigType" SG_ 2432541694 EngTrbCmprssrBypassActuator1Pos 1;
BA_ "SPN" SG_ 2432541694 EngTrbCmprssrBypassActuator1Pos 3675;
BA_ "SigType" SG_ 2432541694 EngTrbCmprssrBypassActuator1Cmd 1;
BA_ "SPN" SG_ 2432541694 EngTrbCmprssrBypassActuator1Cmd 3470;
BA_ "SigType" SG_ 2432541694 EngDsrdTrbCmprssrBypssActtr1Pos 1;
BA_ "SPN" SG_ 2432541694 EngDsrdTrbCmprssrBypssActtr1Pos 5366;
BA_ "SigType" SG_ 2566759934 EnableStatusOfDoor10 4;
BA_ "SPN" SG_ 2566759934 EnableStatusOfDoor10 3441;
BA_ "SigType" SG_ 2566759934 OpenStatusOfDoor10 4;
BA_ "SPN" SG_ 2566759934 OpenStatusOfDoor10 3440;
BA_ "SigType" SG_ 2566759934 LockStatusOfDoor10 4;
BA_ "SPN" SG_ 2566759934 LockStatusOfDoor10 3439;
BA_ "SigType" SG_ 2566759934 EnableStatusOfDoor9 4;
BA_ "SPN" SG_ 2566759934 EnableStatusOfDoor9 3438;
BA_ "SigType" SG_ 2566759934 OpenStatusOfDoor9 4;
BA_ "SPN" SG_ 2566759934 OpenStatusOfDoor9 3437;
BA_ "SigType" SG_ 2566759934 LockStatusOfDoor9 4;
BA_ "SPN" SG_ 2566759934 LockStatusOfDoor9 3436;
BA_ "SigType" SG_ 2566759934 EnableStatusOfDoor8 4;
BA_ "SPN" SG_ 2566759934 EnableStatusOfDoor8 3435;
BA_ "SigType" SG_ 2566759934 OpenStatusOfDoor8 4;
BA_ "SPN" SG_ 2566759934 OpenStatusOfDoor8 3434;
BA_ "SigType" SG_ 2566759934 LockStatusOfDoor8 4;
BA_ "SPN" SG_ 2566759934 LockStatusOfDoor8 3433;
BA_ "SigType" SG_ 2566759934 EnableStatusOfDoor7 4;
BA_ "SPN" SG_ 2566759934 EnableStatusOfDoor7 3432;
BA_ "SigType" SG_ 2566759934 OpenStatusOfDoor7 4;
BA_ "SPN" SG_ 2566759934 OpenStatusOfDoor7 3431;
BA_ "SigType" SG_ 2566759934 LockStatusOfDoor7 4;
BA_ "SPN" SG_ 2566759934 LockStatusOfDoor7 3430;
BA_ "SigType" SG_ 2566759934 EnableStatusOfDoor6 4;
BA_ "SPN" SG_ 2566759934 EnableStatusOfDoor6 3429;
BA_ "SigType" SG_ 2566759934 OpenStatusOfDoor6 4;
BA_ "SPN" SG_ 2566759934 OpenStatusOfDoor6 3428;
BA_ "SigType" SG_ 2566759934 LockStatusOfDoor6 4;
BA_ "SPN" SG_ 2566759934 LockStatusOfDoor6 3427;
BA_ "SigType" SG_ 2566759934 EnableStatusOfDoor5 4;
BA_ "SPN" SG_ 2566759934 EnableStatusOfDoor5 3426;
BA_ "SigType" SG_ 2566759934 OpenStatusOfDoor5 4;
BA_ "SPN" SG_ 2566759934 OpenStatusOfDoor5 3425;
BA_ "SigType" SG_ 2566759934 LockStatusOfDoor5 4;
BA_ "SPN" SG_ 2566759934 LockStatusOfDoor5 3424;
BA_ "SigType" SG_ 2566759934 EnableStatusOfDoor4 4;
BA_ "SPN" SG_ 2566759934 EnableStatusOfDoor4 3423;
BA_ "SigType" SG_ 2566759934 OpenStatusOfDoor4 4;
BA_ "SPN" SG_ 2566759934 OpenStatusOfDoor4 3422;
BA_ "SigType" SG_ 2566759934 LockStatusOfDoor4 4;
BA_ "SPN" SG_ 2566759934 LockStatusOfDoor4 3421;
BA_ "SigType" SG_ 2566759934 EnableStatusOfDoor3 4;
BA_ "SPN" SG_ 2566759934 EnableStatusOfDoor3 3420;
BA_ "SigType" SG_ 2566759934 OpenStatusOfDoor3 4;
BA_ "SPN" SG_ 2566759934 OpenStatusOfDoor3 3419;
BA_ "SigType" SG_ 2566759934 LockStatusOfDoor3 4;
BA_ "SPN" SG_ 2566759934 LockStatusOfDoor3 3418;
BA_ "SigType" SG_ 2566759934 EnableStatusOfDoor2 4;
BA_ "SPN" SG_ 2566759934 EnableStatusOfDoor2 3417;
BA_ "SigType" SG_ 2566759934 OpenStatusOfDoor2 4;
BA_ "SPN" SG_ 2566759934 OpenStatusOfDoor2 3416;
BA_ "SigType" SG_ 2566759934 LockStatusOfDoor2 4;
BA_ "SPN" SG_ 2566759934 LockStatusOfDoor2 3415;
BA_ "SigType" SG_ 2566759934 EnableStatusOfDoor1 4;
BA_ "SPN" SG_ 2566759934 EnableStatusOfDoor1 3414;
BA_ "SigType" SG_ 2566759934 OpenStatusOfDoor1 4;
BA_ "SPN" SG_ 2566759934 OpenStatusOfDoor1 3413;
BA_ "SigType" SG_ 2566759934 LockStatusOfDoor1 4;
BA_ "SPN" SG_ 2566759934 LockStatusOfDoor1 3412;
BA_ "SigType" SG_ 2566757374 Aftrtrtmnt1SCRCtlystRgntTmp2Prlm 1;
BA_ "SPN" SG_ 2566757374 Aftrtrtmnt1SCRCtlystRgntTmp2Prlm 3519;
BA_ "SystemSignalLongSymbol" SG_ 2566757374 Aftrtrtmnt1SCRCtlystRgntTmp2Prlm "Aftrtrtmnt1SCRCtlystRgntTmp2PrlmnryFMI";
BA_ "SigType" SG_ 2566757374 Aftrtrtmnt1SCRCtlystRgntPrprtsPr 1;
BA_ "SPN" SG_ 2566757374 Aftrtrtmnt1SCRCtlystRgntPrprtsPr 3520;
BA_ "SystemSignalLongSymbol" SG_ 2566757374 Aftrtrtmnt1SCRCtlystRgntPrprtsPr "Aftrtrtmnt1SCRCtlystRgntPrprtsPrlmnryFMI";
BA_ "SigType" SG_ 2566757374 Aftrtrtmnt1SCRCtlystRgntCndctvty 1;
BA_ "SPN" SG_ 2566757374 Aftrtrtmnt1SCRCtlystRgntCndctvty 3518;
BA_ "SigType" SG_ 2566757374 Aftrtrtmnt1SCRCtlystRgntCncntrtn 1;
BA_ "SPN" SG_ 2566757374 Aftrtrtmnt1SCRCtlystRgntCncntrtn 3516;
BA_ "SigType" SG_ 2566757374 Aftrtrtmnt1SCRCtlystReagentType 4;
BA_ "SPN" SG_ 2566757374 Aftrtrtmnt1SCRCtlystReagentType 3521;
BA_ "SigType" SG_ 2566757374 Aftrtrtmnt1SCRCtlystRagentTemp2 1;
BA_ "SPN" SG_ 2566757374 Aftrtrtmnt1SCRCtlystRagentTemp2 3515;
BA_ "SigType" SG_ 2364546302 RqdGnrtrAvrgLneLineACRMSVoltage 1;
BA_ "SPN" SG_ 2364546302 RqdGnrtrAvrgLneLineACRMSVoltage 3386;
BA_ "SigType" SG_ 2431654654 EngThrottleActuator2CtrlCmd 1;
BA_ "SPN" SG_ 2431654654 EngThrottleActuator2CtrlCmd 3465;
BA_ "SigType" SG_ 2431654654 EngThrottleActuator1CtrlCmd 1;
BA_ "SPN" SG_ 2431654654 EngThrottleActuator1CtrlCmd 3464;
BA_ "SigType" SG_ 2431654654 EngFuelActuator2CtrlCmd 1;
BA_ "SPN" SG_ 2431654654 EngFuelActuator2CtrlCmd 1244;
BA_ "SigType" SG_ 2431654654 EngFuelActuator1CtrlCmd 1;
BA_ "SPN" SG_ 2431654654 EngFuelActuator1CtrlCmd 633;
BA_ "SigType" SG_ 2364545534 EngCyl24KnockLevel 1;
BA_ "SPN" SG_ 2364545534 EngCyl24KnockLevel 1375;
BA_ "SigType" SG_ 2364545534 EngCyl23KnockLevel 1;
BA_ "SPN" SG_ 2364545534 EngCyl23KnockLevel 1374;
BA_ "SigType" SG_ 2364545534 EngCyl22KnockLevel 1;
BA_ "SPN" SG_ 2364545534 EngCyl22KnockLevel 1373;
BA_ "SigType" SG_ 2364545534 EngCyl21KnockLevel 1;
BA_ "SPN" SG_ 2364545534 EngCyl21KnockLevel 1372;
BA_ "SigType" SG_ 2364545534 EngCyl20KnockLevel 1;
BA_ "SPN" SG_ 2364545534 EngCyl20KnockLevel 1371;
BA_ "SigType" SG_ 2364545534 EngCyl19KnockLevel 1;
BA_ "SPN" SG_ 2364545534 EngCyl19KnockLevel 1370;
BA_ "SigType" SG_ 2364545534 EngCyl18KnockLevel 1;
BA_ "SPN" SG_ 2364545534 EngCyl18KnockLevel 1369;
BA_ "SigType" SG_ 2364545534 EngCyl17KnockLevel 1;
BA_ "SPN" SG_ 2364545534 EngCyl17KnockLevel 1368;
BA_ "SigType" SG_ 2364545278 EngCyl15KnockLevel 1;
BA_ "SPN" SG_ 2364545278 EngCyl15KnockLevel 1366;
BA_ "SigType" SG_ 2364545278 EngCyl14KnockLevel 1;
BA_ "SPN" SG_ 2364545278 EngCyl14KnockLevel 1365;
BA_ "SigType" SG_ 2364545278 EngCyl13KnockLevel 1;
BA_ "SPN" SG_ 2364545278 EngCyl13KnockLevel 1364;
BA_ "SigType" SG_ 2364545278 EngCyl12KnockLevel 1;
BA_ "SPN" SG_ 2364545278 EngCyl12KnockLevel 1363;
BA_ "SigType" SG_ 2364545278 EngCyl11KnockLevel 1;
BA_ "SPN" SG_ 2364545278 EngCyl11KnockLevel 1362;
BA_ "SigType" SG_ 2364545278 EngCyl10KnockLevel 1;
BA_ "SPN" SG_ 2364545278 EngCyl10KnockLevel 1361;
BA_ "SigType" SG_ 2364545278 EngCyl9KnockLevel 1;
BA_ "SPN" SG_ 2364545278 EngCyl9KnockLevel 1360;
BA_ "SigType" SG_ 2364545278 EngCyl16KnockLevel 1;
BA_ "SPN" SG_ 2364545278 EngCyl16KnockLevel 1367;
BA_ "SigType" SG_ 2364545022 EngCyl8KnockLevel 1;
BA_ "SPN" SG_ 2364545022 EngCyl8KnockLevel 1359;
BA_ "SigType" SG_ 2364545022 EngCyl7KnockLevel 1;
BA_ "SPN" SG_ 2364545022 EngCyl7KnockLevel 1358;
BA_ "SigType" SG_ 2364545022 EngCyl6KnockLevel 1;
BA_ "SPN" SG_ 2364545022 EngCyl6KnockLevel 1357;
BA_ "SigType" SG_ 2364545022 EngCyl5KnockLevel 1;
BA_ "SPN" SG_ 2364545022 EngCyl5KnockLevel 1356;
BA_ "SigType" SG_ 2364545022 EngCyl4KnockLevel 1;
BA_ "SPN" SG_ 2364545022 EngCyl4KnockLevel 1355;
BA_ "SigType" SG_ 2364545022 EngCyl3KnockLevel 1;
BA_ "SPN" SG_ 2364545022 EngCyl3KnockLevel 1354;
BA_ "SigType" SG_ 2364545022 EngCyl2KnockLevel 1;
BA_ "SPN" SG_ 2364545022 EngCyl2KnockLevel 1353;
BA_ "SigType" SG_ 2364545022 EngCyl1KnockLevel 1;
BA_ "SPN" SG_ 2364545022 EngCyl1KnockLevel 1352;
BA_ "SigType" SG_ 2364544766 EngCyl9CombustionStatus 4;
BA_ "SPN" SG_ 2364544766 EngCyl9CombustionStatus 3395;
BA_ "SigType" SG_ 2364544766 EngCyl8CombustionStatus 4;
BA_ "SPN" SG_ 2364544766 EngCyl8CombustionStatus 3394;
BA_ "SigType" SG_ 2364544766 EngCyl7CombustionStatus 4;
BA_ "SPN" SG_ 2364544766 EngCyl7CombustionStatus 3393;
BA_ "SigType" SG_ 2364544766 EngCyl6CombustionStatus 4;
BA_ "SPN" SG_ 2364544766 EngCyl6CombustionStatus 3392;
BA_ "SigType" SG_ 2364544766 EngCyl5CombustionStatus 4;
BA_ "SPN" SG_ 2364544766 EngCyl5CombustionStatus 3391;
BA_ "SigType" SG_ 2364544766 EngCyl4CombustionStatus 4;
BA_ "SPN" SG_ 2364544766 EngCyl4CombustionStatus 3390;
BA_ "SigType" SG_ 2364544766 EngCyl3CombustionStatus 4;
BA_ "SPN" SG_ 2364544766 EngCyl3CombustionStatus 3389;
BA_ "SigType" SG_ 2364544766 EngCyl2CombustionStatus 4;
BA_ "SPN" SG_ 2364544766 EngCyl2CombustionStatus 3388;
BA_ "SigType" SG_ 2364544766 EngCyl24CombustionStatus 4;
BA_ "SPN" SG_ 2364544766 EngCyl24CombustionStatus 3410;
BA_ "SigType" SG_ 2364544766 EngCyl23CombustionStatus 4;
BA_ "SPN" SG_ 2364544766 EngCyl23CombustionStatus 3409;
BA_ "SigType" SG_ 2364544766 EngCyl22CombustionStatus 4;
BA_ "SPN" SG_ 2364544766 EngCyl22CombustionStatus 3408;
BA_ "SigType" SG_ 2364544766 EngCyl21CombustionStatus 4;
BA_ "SPN" SG_ 2364544766 EngCyl21CombustionStatus 3407;
BA_ "SigType" SG_ 2364544766 EngCyl20CombustionStatus 4;
BA_ "SPN" SG_ 2364544766 EngCyl20CombustionStatus 3406;
BA_ "SigType" SG_ 2364544766 EngCyl1CombustionStatus 4;
BA_ "SPN" SG_ 2364544766 EngCyl1CombustionStatus 3387;
BA_ "SigType" SG_ 2364544766 EngCyl19CombustionStatus 4;
BA_ "SPN" SG_ 2364544766 EngCyl19CombustionStatus 3405;
BA_ "SigType" SG_ 2364544766 EngCyl18CombustionStatus 4;
BA_ "SPN" SG_ 2364544766 EngCyl18CombustionStatus 3404;
BA_ "SigType" SG_ 2364544766 EngCyl17CombustionStatus 4;
BA_ "SPN" SG_ 2364544766 EngCyl17CombustionStatus 3403;
BA_ "SigType" SG_ 2364544766 EngCyl16CombustionStatus 4;
BA_ "SPN" SG_ 2364544766 EngCyl16CombustionStatus 3402;
BA_ "SigType" SG_ 2364544766 EngCyl15CombustionStatus 4;
BA_ "SPN" SG_ 2364544766 EngCyl15CombustionStatus 3401;
BA_ "SigType" SG_ 2364544766 EngCyl14CombustionStatus 4;
BA_ "SPN" SG_ 2364544766 EngCyl14CombustionStatus 3400;
BA_ "SigType" SG_ 2364544766 EngCyl13CombustionStatus 4;
BA_ "SPN" SG_ 2364544766 EngCyl13CombustionStatus 3399;
BA_ "SigType" SG_ 2364544766 EngCyl12CombustionStatus 4;
BA_ "SPN" SG_ 2364544766 EngCyl12CombustionStatus 3398;
BA_ "SigType" SG_ 2364544766 EngCyl11CombustionStatus 4;
BA_ "SPN" SG_ 2364544766 EngCyl11CombustionStatus 3397;
BA_ "SigType" SG_ 2364544766 EngCyl10CombustionStatus 4;
BA_ "SPN" SG_ 2364544766 EngCyl10CombustionStatus 3396;
BA_ "SigType" SG_ 2364544510 RqGenOverallPowerFactorLagging 4;
BA_ "SPN" SG_ 2364544510 RqGenOverallPowerFactorLagging 3385;
BA_ "SigType" SG_ 2364544510 RqGeneratorOverallPowerFactor 1;
BA_ "SPN" SG_ 2364544510 RqGeneratorOverallPowerFactor 3384;
BA_ "SigType" SG_ 2364544510 RqGeneratorTotalACReactivePower 1;
BA_ "SPN" SG_ 2364544510 RqGeneratorTotalACReactivePower 3383;
BA_ "SigType" SG_ 2364544254 RltvBldHghtAndBldRttnAnglMsrmntL 1;
BA_ "SPN" SG_ 2364544254 RltvBldHghtAndBldRttnAnglMsrmntL 3366;
BA_ "SystemSignalLongSymbol" SG_ 2364544254 RltvBldHghtAndBldRttnAnglMsrmntL "RltvBldHghtAndBldRttnAnglMsrmntLtncy";
BA_ "SigType" SG_ 2364544254 RlativeBladeHeightFigureOfMerit 4;
BA_ "SPN" SG_ 2364544254 RlativeBladeHeightFigureOfMerit 3367;
BA_ "SigType" SG_ 2364544254 BladeRotationAngleFigureOfMerit 4;
BA_ "SPN" SG_ 2364544254 BladeRotationAngleFigureOfMerit 3332;
BA_ "SigType" SG_ 2364544254 BladeRotationAngle 1;
BA_ "SPN" SG_ 2364544254 BladeRotationAngle 3331;
BA_ "SigType" SG_ 2364544254 RelativeBladeHeight 1;
BA_ "SPN" SG_ 2364544254 RelativeBladeHeight 3365;
BA_ "SigType" SG_ 2349006590 BrakeLightSwitch 4;
BA_ "SigType" SG_ 2349006590 ASREngineControlActive 4;
BA_ "SigType" SG_ 2349006590 ASRBreakControlActive 4;
BA_ "SigType" SG_ 2349006590 VehicleRetarderCtrlActive 4;
BA_ "SigType" SG_ 2349006590 VehicleABSActive 4;
BA_ "SigType" SG_ 2566834686 RoadCurvature 1;
BA_ "SPN" SG_ 2566834686 RoadCurvature 1591;
BA_ "SigType" SG_ 2566834686 PneumaticControlLine 4;
BA_ "SigType" SG_ 2566834686 ABSOffroadRequest 4;
BA_ "SigType" SG_ 2566834686 TwoElCircuitsBrakeDemand 4;
BA_ "SigType" SG_ 2566834686 VehicleRetarderCtrlActive 4;
BA_ "SigType" SG_ 2550398718 ActualRetarderPercTorque 1;
BA_ "SigType" SG_ 2550398718 Wheel_BasedVehicleSpeed 1;
BA_ "SigType" SG_ 2550398718 SupplyLineBrakingRequest 4;
BA_ "SigType" SG_ 2550398718 VDCActive 4;
BA_ "SigType" SG_ 2550398718 AutomTowedVehBreakActive 4;
BA_ "SigType" SG_ 2550398718 VehicleServiceBrakeActive 4;
BA_ "SigType" SG_ 2550398718 VehicleRetarderCtrlActive 4;
BA_ "SigType" SG_ 2550398718 VehicleABSActive 4;
BA_ "SigType" SG_ 2566833406 ReferenceRetarderTorque 1;
BA_ "SPN" SG_ 2566833406 ReferenceRetarderTorque 556;
BA_ "SigType" SG_ 2566833406 SupplyLineBrakingRequest 4;
BA_ "SigType" SG_ 2566833406 LoadingRampApproachAssist 4;
BA_ "SigType" SG_ 2566833406 SpringBrakeEngaged 4;
BA_ "SigType" SG_ 2566833406 ElectrLoadPropFunc 4;
BA_ "SigType" SG_ 2566833406 SpringBrakeInstalled 4;
BA_ "SigType" SG_ 2566833406 ElecSupplyOfNonBrakingSys 4;
BA_ "SigType" SG_ 2566833406 AmberWarningSignalReq 4;
BA_ "SigType" SG_ 2566833406 RedWarningSignalRequest 4;
BA_ "SigType" SG_ 2566833406 VehicleElectrSupplySuff 4;
BA_ "SigType" SG_ 2566833406 AutomTowedVehBreakActive 4;
BA_ "SigType" SG_ 2566833406 VehicleServiceBrakeActive 4;
BA_ "SigType" SG_ 2566833406 VehicleRetarderCtrlActive 4;
BA_ "SigType" SG_ 2566833406 VehicleABSActive 4;
BA_ "SigType" SG_ 2365507326 VehiclePneumSupplySuff 4;
BA_ "SigType" SG_ 2365507326 BrakeTemperatureStatus 4;
BA_ "SigType" SG_ 2365507326 BrakeLiningSufficient 4;
BA_ "SigType" SG_ 2365507326 TyrePressureSufficient 4;
BA_ "SigType" SG_ 2565013246 ODDRequest 4;
BA_ "SigType" SG_ 2565013246 AntiTheftDeviceReq 4;
BA_ "SigType" SG_ 2566807038 MaxVehicleSpeedLimit 1;
BA_ "SPN" SG_ 2566807038 MaxVehicleSpeedLimit 74;
BA_ "SigType" SG_ 2365480958 VehicleSpeed 1;
BA_ "SigType" SG_ 2365480958 PercentLoadAtCurrentSpeed 1;
BA_ "SigType" SG_ 2365480958 EngineSpeed 1;
BA_ "SigType" SG_ 2365480958 ActualEngine_PercTorque 1;
BA_ "SigType" SG_ 2365480958 DriversDemandEngine_PercTorque 1;
BA_ "SigType" SG_ 2365480958 EngineRunning 4;
BA_ "SigType" SG_ 2365480958 EngineControlAllowed 4;
BA_ "SigType" SG_ 2566808062 ClutchIndptdPTOFeedback 4;
BA_ "SigType" SG_ 2566808062 AccelPedalPosition 1;
BA_ "SigType" SG_ 2566808062 AccelPedalLowIdleSwitch 4;
BA_ "SigType" SG_ 2566808062 StarterActive 4;
BA_ "SigType" SG_ 2566808062 PTOControlAllowed 4;
BA_ "SigType" SG_ 2566808062 SecEngineMtdPTOFeedback 4;
BA_ "SigType" SG_ 2566808062 FirstEngineMtdPTOFeedback 4;
BA_ "SigType" SG_ 2566808062 SecClutchDptdPTOFeedback 4;
BA_ "SigType" SG_ 2566808062 FirstClutchDpdtPTOFeedback 4;
BA_ "SigType" SG_ 2566808062 CurrentGear 1;
BA_ "SigType" SG_ 2566808062 PercentClutchSlip 1;
BA_ "SPN" SG_ 2566808062 PercentClutchSlip 522;
VAL_ 2561212158 TextDisplayInstructions 7 "1110Reserved" 6 "BlinkSubstring" 15 "NotApplicable" 1 "HldDsplyPrsntlyDsplydInfrmtnShl" 0 "ClrDsplyDsplydInfrmtnShldBDltdN" 5 "HighlightSubstring" 4 "OvrwrtSbstrngAPrtnOfPrsntlyDspl" 3 "OvrwrtDsplyPrsntlyDsplydInfrmtn" 2 "AppndAtEndOfDsplyTrnsmttdInfrmt" ;
VAL_ 2566746366 RetractStatusOfRamp5 2 "error" 1 "rampEx" 0 "rampRetracted" 3 "notAvailable" ;
VAL_ 2566746366 RetractStatusOfRamp4 3 "notAvailable" 2 "error" 1 "rampEx" 0 "rampRetracted" ;
VAL_ 2566746366 MovementStatusOfRamp5 3 "notAvailable" 2 "error" 1 "rampBeingMoved" 0 "rampNotBeingMoved" ;
VAL_ 2566746366 MovementStatusOfRamp4 3 "notAvailable" 2 "error" 1 "rampBeingMoved" 0 "rampNotBeingMoved" ;
VAL_ 2566746366 EnableStatusOfRamp5 3 "notAvailable" 2 "error" 1 "rampEnabled" 0 "rampDisabled" ;
VAL_ 2566746366 EnableStatusOfRamp4 3 "notAvailable" 2 "error" 1 "rampEnabled" 0 "rampDisabled" ;
VAL_ 2566746366 MovementStatusOfRamp3 3 "notAvailable" 2 "error" 1 "rampBeingMoved" 0 "rampNotBeingMoved" ;
VAL_ 2566746366 EnableStatusOfRamp3 3 "notAvailable" 2 "error" 1 "rampEnabled" 0 "rampDisabled" ;
VAL_ 2566746366 RetractStatusOfRamp3 3 "notAvailable" 2 "error" 1 "rampEx" 0 "rampRetracted" ;
VAL_ 2566746366 MovementStatusOfRamp2 3 "notAvailable" 2 "error" 1 "rampBeingMoved" 0 "rampNotBeingMoved" ;
VAL_ 2566746366 EnableStatusOfRamp2 3 "notAvailable" 2 "error" 1 "rampEnabled" 0 "rampDisabled" ;
VAL_ 2566746366 RetractStatusOfRamp2 3 "notAvailable" 2 "error" 1 "rampEx" 0 "rampRetracted" ;
VAL_ 2566746366 MovementStatusOfRamp1 3 "notAvailable" 2 "error" 1 "rampBeingMoved" 0 "rampNotBeingMoved" ;
VAL_ 2566746366 EnableStatusOfRamp1 3 "notAvailable" 2 "error" 1 "rampEnabled" 0 "rampDisabled" ;
VAL_ 2566746366 RetractStatusOfRamp1 3 "notAvailable" 2 "error" 1 "rampEx" 0 "rampRetracted" ;
VAL_ 2566746110 EngExhstGsRcrclation1Valve2Ctrl 4 "MeansMaxValveOpening" ;
VAL_ 2561277694 LaneDepartureWarningEnableCmd 3 "DonTCare" 2 "Reserved" 1 "EnableLaneDepartureWarning" 0 "DisableLaneDepartureWarning" ;
VAL_ 2633861886 J2012DTCStatus 1 "DTCIsActive" 0 "DTCIsPreviouslyActive" ;
VAL_ 2565873150 SteerAngleSensorCalibrated 3 "NotAvailable" 2 "Reserved" 1 "SASCalibrated" 0 "SASNotCalibrated" ;
VAL_ 2565873150 SteerAngleSensorActiveMode 3 "NotAvailable" 2 "Reserved" 1 "NormalModeActive" 0 "ProgrammingModeActive" ;
VAL_ 2565873150 SteerWheelAngleRangeCounterType 3 "SignalNotAvailable" 2 "NotDefined" 1 "AbsNumberOfCounts" 0 "RelativeNumberOfCounts" ;
VAL_ 2566751230 TransferCaseStatus 7 "notAvailable" 6 "error" 5 "TrnsfrCsShftInPrgrssGrNtCnfrmed" 4 "WheelLow" 2 "neutral" 1 "WheelHigh" ;
VAL_ 2566755838 TransOverheatIndicator 3 "NotAvailable" 2 "TrnsOverheatIndicatorIsFlashing" 1 "TrnsOvrhtIndctrIsOnContinuously" 0 "TransOverheatIndicatorIsOff" ;
VAL_ 2566755838 TransOilLevelSwitch 3 "NotAvailable" 2 "Error" 1 "FullNotEmpty" 0 "Empty" ;
VAL_ 2566755838 TransOilFilterRestrictionSwitch 3 "NotAvailable" 2 "Error" 1 "RestrictionExistsOnOilFilter" 0 "NoRestriction" ;
VAL_ 2566799614 ImplementRearWorkLight 3 "NotAvailable" 2 "FaultDetected" 1 "Activated" 0 "Deactivated" ;
VAL_ 2566799614 ImplementLeftForwardWorkLight 3 "NotAvailable" 2 "FaultDetected" 1 "Activated" 0 "Deactivated" ;
VAL_ 2566799614 ImplementRightForwardWorkLight 3 "NotAvailable" 2 "FaultDetected" 1 "Activated" 0 "Deactivated" ;
VAL_ 2566799614 ImplementLeftFacingWorkLight 3 "NotAvailable" 2 "FaultDetected" 1 "Activate" 0 "Deactivate" ;
VAL_ 2566799614 ImplementRightFacingWorkLight 3 "NotAvailable" 2 "FaultDetected" 1 "Activated" 0 "Deactivated" ;
VAL_ 2566799614 ImplementOEMOption1Light 3 "NotAvailable" 2 "FaultDetected" 1 "Activated" 0 "Deactivated" ;
VAL_ 2566799614 ImplementOEMOption2Light 3 "NotAvailable" 2 "FaultDetected" 1 "Activated" 0 "Deactivated" ;
VAL_ 2566799614 TrctrFrontHighMountedWorkLights 3 "NotAvailable" 2 "FaultDetected" 1 "Activated" 0 "Deactivated" ;
VAL_ 2566799614 TrctorFrontLowMountedWorkLights 3 "NotAvailable" 2 "FaultDetected" 1 "Activated" 0 "Deactivated" ;
VAL_ 2566799614 TrctorSideHighMountedWorkLights 3 "NotAvailable" 2 "FaultDetected" 1 "Activated" 0 "Deactivated" ;
VAL_ 2566799614 TractorSideLowMountedWorkLights 3 "NotAvailable" 2 "FaultDetected" 1 "Activated" 0 "Deactivated" ;
VAL_ 2566799614 TrctorRearHighMountedWorkLights 3 "NotAvailable" 2 "FaultDetected" 1 "Activated" 0 "Deactivated" ;
VAL_ 2566799614 TractorRearLowMountedWorkLights 3 "NotAvailable" 2 "FaultDetected" 1 "Activated" 0 "Deactivated" ;
VAL_ 2566799614 TrctrUndersideMountedWorkLights 3 "NotAvailable" 2 "FaultDetected" 1 "Activated" 0 "Deactivated" ;
VAL_ 2566799614 RearFogLights 3 "NotAvailable" 2 "FaultDetected" 1 "Activated" 0 "Deactivated" ;
VAL_ 2566799614 TractorMarkerLight 3 "NotAvailable" 2 "FaultDetected" 1 "Activated" 0 "Deactivated" ;
VAL_ 2566799614 ImplementMarkerLight 3 "NotAvailable" 2 "FaultDetected" 1 "Activated" 0 "Deactivated" ;
VAL_ 2566799614 TractorClearanceLight 3 "NotAvailable" 2 "FaultDetected" 1 "Activated" 0 "Deactivated" ;
VAL_ 2566799614 ImplementClearanceLight 3 "NotAvailable" 2 "FaultDetected" 1 "Activated" 0 "Deactivated" ;
VAL_ 2566799614 LeftStopLight 3 "NotAvailable" 2 "FaultDetected" 1 "Activated" 0 "Deactivated" ;
VAL_ 2566799614 RightStopLight 3 "NotAvailable" 2 "FaultDetected" 1 "Activated" 0 "Deactivated" ;
VAL_ 2566799614 CenterStopLight 3 "NotAvailable" 2 "FaultDetected" 1 "Activated" 0 "Deactivated" ;
VAL_ 2566799614 BackUpLightAndAlarmHorn 3 "NotAvailable" 2 "FaultDetected" 1 "Activated" 0 "Deactivated" ;
VAL_ 2566799614 LeftTurnSignalLights 3 "NotAvailable" 2 "FaultDetected" 1 "Activated" 0 "Deactivated" ;
VAL_ 2566799614 RightTurnSignalLights 3 "NotAvailable" 2 "FaultDetected" 1 "Activated" 0 "Deactivated" ;
VAL_ 2566799614 RotatingBeaconLight 3 "NotAvailable" 2 "FaultDetected" 1 "Activated" 0 "Deactivated" ;
VAL_ 2566799614 TractorFrontFogLights 3 "NotAvailable" 2 "FaultDetected" 1 "Activated" 0 "Deactivated" ;
VAL_ 2566799614 HighBeamHeadLightData 3 "NotAvailable" 2 "FaultDetected" 1 "Activated" 0 "Deactivated" ;
VAL_ 2566799614 LowBeamHeadLightData 3 "NotAvailable" 2 "FaultDetected" 1 "Activated" 0 "Deactivated" ;
VAL_ 2566799614 AltBeamHeadLightData 3 "NotAvailable" 2 "FaultDetected" 1 "Activated" 0 "Deactivated" ;
VAL_ 2566799614 RunningLight 3 "NotAvailable" 2 "FaultDetected" 1 "Activated" 0 "Deactivated" ;
VAL_ 2365473278 ImplementRearWorkLightCmd 3 "DonTCare" 2 "Reserved" 1 "Activate" 0 "Deactivate" ;
VAL_ 2365473278 ImplmentLeftForwardWorkLightCmd 3 "DonTCare" 2 "Reserved" 1 "Activate" 0 "Deactivate" ;
VAL_ 2365473278 ImplmntRightForwardWorkLightCmd 3 "DonTCare" 2 "Reserved" 1 "Activate" 0 "Deactivate" ;
VAL_ 2365473278 LightingDataRqCmd 3 "DonTCare" 2 "Reserved" 1 "Activate" 0 "Deactivate" ;
VAL_ 2365473278 ImplementLeftFacingWorkLightCmd 3 "DonTCare" 2 "Reserved" 1 "Activate" 0 "Deactivate" ;
VAL_ 2365473278 ImplmentRightFacingWorkLightCmd 3 "DonTCare" 2 "Reserved" 1 "Activate" 0 "Deactivate" ;
VAL_ 2365473278 ImplementOEMOption1LightCmd 3 "DonTCare" 2 "Reserved" 1 "Activate" 0 "Deactivate" ;
VAL_ 2365473278 ImplementOEMOption2LightCmd 3 "DonTCare" 2 "Reserved" 1 "Activate" 0 "Deactivate" ;
VAL_ 2365473278 TrctrFrntHghMuntedWorkLightsCmd 3 "DonTCare" 2 "Reserved" 1 "Activate" 0 "Deactivate" ;
VAL_ 2365473278 TrctrFrntLwMountedWorkLightsCmd 3 "DonTCare" 2 "Reserved" 1 "Activate" 0 "Deactivate" ;
VAL_ 2365473278 TrctrSdHighMountedWorkLightsCmd 3 "DonTCare" 2 "Reserved" 1 "Activate" 0 "Deactivate" ;
VAL_ 2365473278 TrctrSdeLowMountedWorkLightsCmd 3 "DonTCare" 2 "Reserved" 1 "Activate" 0 "Deactivate" ;
VAL_ 2365473278 TrctrRrHighMountedWorkLightsCmd 3 "DonTCare" 2 "Reserved" 1 "Activate" 0 "Deactivate" ;
VAL_ 2365473278 TrctrRarLowMountedWorkLightsCmd 3 "DonTCare" 2 "Reserved" 1 "Activate" 0 "Deactivate" ;
VAL_ 2365473278 TrctrUndrsdMountedWorkLightsCmd 3 "DonTCare" 2 "Reserved" 1 "Activate" 0 "Deactivate" ;
VAL_ 2365473278 RearFogLightCmd 3 "DonTCare" 2 "Reserved" 1 "Activate" 0 "Deactivate" ;
VAL_ 2365473278 TractorMarkerLightCmd 3 "DonTCare" 2 "Reserved" 1 "Activate" 0 "Deactivate" ;
VAL_ 2365473278 ImplementMarkerLightCmd 3 "DonTCare" 2 "Reserved" 1 "Activate" 0 "Deactivate" ;
VAL_ 2365473278 TractorClearanceLightCmd 3 "DonTCare" 2 "Reserved" 1 "Activate" 0 "Deactivate" ;
VAL_ 2365473278 ImplementClearanceLightCmd 3 "DonTCare" 2 "Reserved" 1 "Activate" 0 "Deactivate" ;
VAL_ 2365473278 LeftStopLightCmd 3 "DonTCare" 2 "Reserved" 1 "Activate" 0 "Deactivate" ;
VAL_ 2365473278 RightStopLightCmd 3 "DonTCare" 2 "Reserved" 1 "Activate" 0 "Deactivate" ;
VAL_ 2365473278 CenterStopLightCmd 3 "DonTCare" 2 "Reserved" 1 "Activate" 0 "Deactivate" ;
VAL_ 2365473278 BackUpLightAndAlarmHornCmd 3 "DonTCare" 2 "Reserved" 1 "Activate" 0 "Deactivate" ;
VAL_ 2365473278 LeftTurnSignalLightsCmd 3 "DonTCare" 2 "Reserved" 1 "Activate" 0 "Deactivate" ;
VAL_ 2365473278 RightTurnSignalLightsCmd 3 "DonTCare" 2 "Reserved" 1 "Activate" 0 "Deactivate" ;
VAL_ 2365473278 RotatingBeaconLightCmd 3 "DonTCare" 2 "Reserved" 1 "Activate" 0 "Deactivate" ;
VAL_ 2365473278 TractorFrontFogLightsCmd 3 "DonTCare" 2 "Reserved" 1 "Activate" 0 "Deactivate" ;
VAL_ 2365473278 HighBeamHeadLightCmd 3 "DonTCare" 2 "Reserved" 1 "Activate" 0 "Deactivate" ;
VAL_ 2365473278 LowBeamHeadLightCmd 3 "DonTCare" 2 "Reserved" 1 "Activate" 0 "Deactivate" ;
VAL_ 2365473278 AltBeamHeadLightCmd 3 "DonTCare" 2 "Reserved" 1 "Activate" 0 "Deactivate" ;
VAL_ 2365473278 RunningLightCmd 3 "DonTCare" 2 "Reserved" 1 "Activate" 0 "Deactivate" ;
VAL_ 2365485822 BladeCtrlMode 2 "InactiveAutomaticMode" 1 "AutomaticMode" 0 "ManualMode" ;
VAL_ 2365485822 LandLevelingSystemEnableStatus 3 "NotAvailable_NotInstalled" 2 "Error" 1 "Enabled" 0 "Disabled" ;
VAL_ 2365485822 BladeCtrlModeRight 15 "NotAvailable" 14 "Error" 3 "1101Reserved" 2 "InactiveAuto" 1 "Auto" 0 "Manual" ;
VAL_ 2365485822 BladeCtrlModeLeft 15 "NotAvailable" 14 "Error" 3 "1101Reserved" 2 "InactiveAuto" 1 "Auto" 0 "Manual" ;
VAL_ 2566768894 EngOprtrPrmryIntrmdtSpdSlctStte 15 "NotAvailable" 14 "SAEReserved" 1 "thr1101CtrlSttIsISCSttng1Thru13" 0 "CtrlSttIsISCFnctnltyIsNtRqdEngO" ;
VAL_ 2566769406 EngOprtrPrmryIntrmdtSpeedSelect 15 "NotAvailable" 14 "ErrorCondition" 1 "thr1101IndctsThtISCSttng1Thr13I" 0 "IndctsThtISCFnctnltyIsNtRqdEngO" ;
VAL_ 2566811134 CabHeatingZone 3 "NotAvailable" 2 "Reserved" 1 "CabHeatingZoneOn" 0 "CabHeatingZoneOff" ;
VAL_ 2566811134 EngHeatingZone 3 "NotAvailable" 2 "Reserved" 1 "EngHeatingZoneOn" 0 "EngHeatingZoneOff" ;
VAL_ 2566811134 CabVentilation 3 "NotAvailable" 2 "Reserved" 1 "CabIsVentilated" 0 "CabNotVentilated" ;
VAL_ 2566811134 AuxHeaterMode 15 "NotAvailable" 14 "Error" 4 "1101NotDefined" 3 "NormalMode" 2 "EconomyMode" 1 "OffDTADRPrErpnRgltnsFrTrnsprtOf" 0 "HeaterNotActive" ;
VAL_ 2566811134 AuxHeaterWaterPumpStatus 3 "NotAvailable" 2 "Reserved" 1 "WaterPumpIsRunning" 0 "WaterPumpIsNotRunning" ;
VAL_ 2565867774 FireApparatusPumpEngagement 3 "NotAvailableNotInstalled" 2 "Error" 1 "PumpEngaged" 0 "PumpNotEngaged" ;
VAL_ 2565867774 EngHydPressGovernorSwitch 3 "NotAvailable" 2 "ErrorIndicator" 1 "PressModeActive" 0 "PressModeInactive" ;
VAL_ 2565867774 EngHydPrssGovernorModeIndicator 3 "NotAvailable" 2 "ErrorIndicator" 1 "Enabled" 0 "Disabled" ;
VAL_ 2365449982 HydBrakeFluidLevelSwitch 3 "NotAvailable" 2 "ErrorIndicator" 1 "FluidLevelIsSufficient" 0 "FluidLevelIsNotSufficient" ;
VAL_ 2365449982 HydBrakeSystemAudibleWarningCmd 3 "DontCare" 2 "Reserved" 1 "AudibleWarningOn" 0 "AudibleWarningOff" ;
VAL_ 2365449982 HydBrkePressSupplyStateCircuit2 3 "NotAvailable" 2 "ErrorIndicator" 1 "SupplyIsReliable" 0 "SupplyIsNotReliable" ;
VAL_ 2365449982 HydBrkePressSupplyStateCircuit1 3 "NotAvailable" 2 "ErrorIndicator" 1 "SupplyIsReliable" 0 "SupplyIsNotReliable" ;
VAL_ 2365449982 HydBrkPressWarningStateCircuit2 3 "NotAvailable" 2 "ErrorIndicator" 1 "PressLevelBelowWarningLevel" 0 "PressLevelSufficient" ;
VAL_ 2365449982 HydBrkPressWarningStateCircuit1 3 "NotAvailable" 2 "ErrorIndicator" 1 "PressLevelBelowWarningLevel" 0 "PressLevelSufficient" ;
VAL_ 2566759678 EnggmntSttusTransInputShaftPTO1 3 "NotAvailable" 2 "Error" 1 "DriveIsEngaged" 0 "DriveNotEngaged" ;
VAL_ 2566759678 EnggmntSttusTransInputShaftPTO2 3 "NotAvailable" 2 "Error" 1 "DriveIsEngaged" 0 "DriveNotEngaged" ;
VAL_ 2566759678 EnggmntSttusTransOutputShaftPTO 3 "NotAvailable" 2 "Error" 1 "DriveIsEngaged" 0 "DriveNotEngaged" ;
VAL_ 2566759678 EnggmntSttsTrnsfrCsOtptShaftPTO 3 "NotAvailable" 2 "Error" 1 "DriveIsEngaged" 0 "DriveNotEngaged" ;
VAL_ 2566759678 EnggmntCnsntTransInputShaftPTO1 3 "NotAvailable" 2 "Error" 1 "CnsentGivenPTODriveMayBeEngaged" 0 "CnsntNtGvnPTODrvShldNtBeEngaged" ;
VAL_ 2566759678 EnggmntCnsntTransInputShaftPTO2 3 "NotAvailable" 2 "Error" 1 "CnsentGivenPTODriveMayBeEngaged" 0 "CnsntNtGvnPTODrvShldNtBeEngaged" ;
VAL_ 2566759678 EnggmntCnsntTransOutputShaftPTO 3 "NotAvailable" 2 "Error" 1 "CnsentGivenPTODriveMayBeEngaged" 0 "CnsntNtGvnPTODrvShldNtBeEngaged" ;
VAL_ 2566759678 EnggmntCnsntTrnsfrCsOtptShftPTO 3 "NotAvailable" 2 "Error" 1 "CnsentGivenPTODriveMayBeEngaged" 0 "CnsntNtGvnPTODrvShldNtBeEngaged" ;
VAL_ 2566759678 EnableSwitchTransInputShaftPTO1 3 "NotAvailable" 2 "Error" 1 "EnblSwtchOffPTOOperationDesired" 0 "EnblSwtchOffPTOOprtonNotDesired" ;
VAL_ 2566759678 EnableSwitchTransInputShaftPTO2 3 "NotAvailable" 2 "Error" 1 "EnblSwtchOffPTOOperationDesired" 0 "EnblSwtchOffPTOOprtonNotDesired" ;
VAL_ 2566759678 EnableSwitchTransOutputShaftPTO 3 "NotAvailable" 2 "Error" 1 "EnblSwtchOffPTOOperationDesired" 0 "EnblSwtchOffPTOOprtonNotDesired" ;
VAL_ 2566759678 EnblSwtchTrnsfrCsOutputShaftPTO 3 "NotAvailable" 2 "Error" 1 "EnblSwtchOffPTOOperationDesired" 0 "EnblSwtchOffPTOOprtonNotDesired" ;
VAL_ 2566759678 EnggmntSttsPTOEngAccssoryDrive2 3 "NotAvailable" 2 "Error" 1 "DriveEngaged" 0 "DriveNotEngaged" ;
VAL_ 2566759678 EnggmntSttsPTOEngAccssoryDrive1 3 "NotAvailable" 2 "Error" 1 "DriveEngaged" 0 "DriveNotEngaged" ;
VAL_ 2566759678 EnggmntCnsntPTOEngAccssryDrive2 3 "NotAvailable" 2 "Error" 1 "CnsentGivenPTODriveMayBeEngaged" 0 "CnsntNtGvnPTODrvMayNotBeEngaged" ;
VAL_ 2566759678 EnggmntCnsntPTOEngAccssryDrive1 3 "NotAvailable" 2 "Error" 1 "CnsentGivenPTODriveMayBeEngaged" 0 "CnsntNtGvnPTODrvMayNotBeEngaged" ;
VAL_ 2566759678 EngagementStatusPTOEngFlywheel 3 "NotAvailable" 2 "Error" 1 "DriveEngaged" 0 "DriveNotEngaged" ;
VAL_ 2566759678 EngagementConsentPTOEngFlywheel 3 "NotAvailable" 2 "Error" 1 "CnsentGivenPTODriveMayBeEngaged" 0 "CnsntNtGvnPTODrvMayNotBeEngaged" ;
VAL_ 2566759678 EnblSwitchPTOEngAccessoryDrive2 3 "NotAvailable" 2 "Error" 1 "EnblSwitchOnPTOOperationDesired" 0 "EnblSwtchOffPTOOprtonNotDesired" ;
VAL_ 2566759678 EnblSwitchPTOEngAccessoryDrive1 3 "NotAvailable" 2 "Error" 1 "EnblSwitchOnPTOOperationDesired" 0 "EnblSwtchOffPTOOprtonNotDesired" ;
VAL_ 2566759678 EnableSwitchPTOEngFlywheel 3 "NotAvailable" 2 "Error" 1 "EnblSwitchOnPTOOperationDesired" 0 "EnblSwtchOffPTOOprtonNotDesired" ;
VAL_ 2566759678 AtLeastOnePTOEngaged 3 "NotAvailable" 2 "Error" 1 "AtLeastOnePTODriveIsEngaged" 0 "NoPTODriveIsEngaged" ;
VAL_ 2432541694 EngTrbCmprssrBypssActtr1TmpStts 7 "NotAvailable" 6 "Error" 5 "NotDefined" 4 "LowMostSevere" 3 "LowLeastSevere" 2 "InRange" 1 "HighLeastSevere" 0 "HighMostSevere" ;
VAL_ 2432541694 EngTrbCmprssrBypassActuator2Cmd 4 "RprsntsFllyOpnTypcllyTrbCmprssr" ;
VAL_ 2432541694 EngTrbCmprssrBypassActuator1Pos 4 "RprsntsBypssFllyOpnTypcllyCmprs" ;
VAL_ 2432541694 EngTrbCmprssrBypassActuator1Cmd 4 "RprsntsFllyOpnTypcllyTrbCmprssr" ;
VAL_ 2566759934 EnableStatusOfDoor10 3 "notAvailable" 2 "error" 1 "doorEnabled" 0 "doorDisabled" ;
VAL_ 2566759934 OpenStatusOfDoor10 3 "notAvailable" 2 "error" 1 "doorOpened" 0 "doorClosed" ;
VAL_ 2566759934 LockStatusOfDoor10 3 "notAvailable" 2 "error" 1 "locked" 0 "unlocked" ;
VAL_ 2566759934 EnableStatusOfDoor9 3 "notAvailable" 2 "error" 1 "doorEnabled" 0 "doorDisabled" ;
VAL_ 2566759934 OpenStatusOfDoor9 3 "notAvailable" 2 "error" 1 "doorOpened" 0 "doorClosed" ;
VAL_ 2566759934 LockStatusOfDoor9 3 "notAvailable" 2 "error" 1 "locked" 0 "unlocked" ;
VAL_ 2566759934 EnableStatusOfDoor8 3 "notAvailable" 2 "error" 1 "doorEnabled" 0 "doorDisabled" ;
VAL_ 2566759934 OpenStatusOfDoor8 3 "notAvailable" 2 "error" 1 "doorOpened" 0 "doorClosed" ;
VAL_ 2566759934 LockStatusOfDoor8 3 "notAvailable" 2 "error" 1 "locked" 0 "unlocked" ;
VAL_ 2566759934 EnableStatusOfDoor7 3 "notAvailable" 2 "error" 1 "doorEnabled" 0 "doorDisabled" ;
VAL_ 2566759934 OpenStatusOfDoor7 3 "notAvailable" 2 "error" 1 "doorOpened" 0 "doorClosed" ;
VAL_ 2566759934 LockStatusOfDoor7 3 "notAvailable" 2 "error" 1 "locked" 0 "unlocked" ;
VAL_ 2566759934 EnableStatusOfDoor6 3 "notAvailable" 2 "error" 1 "doorEnabled" 0 "doorDisabled" ;
VAL_ 2566759934 OpenStatusOfDoor6 3 "notAvailable" 2 "error" 1 "doorOpened" 0 "doorClosed" ;
VAL_ 2566759934 LockStatusOfDoor6 3 "notAvailable" 2 "error" 1 "locked" 0 "unlocked" ;
VAL_ 2566759934 EnableStatusOfDoor5 3 "notAvailable" 2 "error" 1 "doorEnabled" 0 "doorDisabled" ;
VAL_ 2566759934 OpenStatusOfDoor5 3 "notAvailable" 2 "error" 1 "doorOpened" 0 "doorClosed" ;
VAL_ 2566759934 LockStatusOfDoor5 3 "notAvailable" 2 "error" 1 "locked" 0 "unlocked" ;
VAL_ 2566759934 EnableStatusOfDoor4 3 "notAvailable" 2 "error" 1 "doorEnabled" 0 "doorDisabled" ;
VAL_ 2566759934 OpenStatusOfDoor4 3 "notAvailable" 2 "error" 1 "doorOpened" 0 "doorClosed" ;
VAL_ 2566759934 LockStatusOfDoor4 3 "notAvailable" 2 "error" 1 "locked" 0 "unlocked" ;
VAL_ 2566759934 EnableStatusOfDoor3 3 "notAvailable" 2 "error" 1 "doorEnabled" 0 "doorDisabled" ;
VAL_ 2566759934 OpenStatusOfDoor3 3 "notAvailable" 2 "error" 1 "doorOpened" 0 "doorClosed" ;
VAL_ 2566759934 LockStatusOfDoor3 3 "notAvailable" 2 "error" 1 "locked" 0 "unlocked" ;
VAL_ 2566759934 EnableStatusOfDoor2 3 "notAvailable" 2 "error" 1 "doorEnabled" 0 "doorDisabled" ;
VAL_ 2566759934 OpenStatusOfDoor2 3 "notAvailable" 2 "error" 1 "doorOpened" 0 "doorClosed" ;
VAL_ 2566759934 LockStatusOfDoor2 3 "notAvailable" 2 "error" 1 "locked" 0 "unlocked" ;
VAL_ 2566759934 EnableStatusOfDoor1 3 "notAvailable" 2 "error" 1 "doorEnabled" 0 "doorDisabled" ;
VAL_ 2566759934 OpenStatusOfDoor1 3 "notAvailable" 2 "error" 1 "doorOpened" 0 "doorClosed" ;
VAL_ 2566759934 LockStatusOfDoor1 3 "notAvailable" 2 "error" 1 "locked" 0 "unlocked" ;
VAL_ 2566757374 Aftrtrtmnt1SCRCtlystReagentType 15 "NotAvailable" 14 "ErrrDtctdWthUrRgntTypeDetection" 13 "NtAblTDtrmneCatalystReagentType" 5 "to1100ReservedForSAEAssignment" 3 "CatalystReagentIsProperMixture" 2 "CatalystReagentIsDiesel" 1 "CtlystRgntIsUrCncntrationTooLow" 0 "CtlystRgntIsUrCncntrtionTooHigh" ;
VAL_ 2364544766 EngCyl9CombustionStatus 3 "NotAvailable" 2 "Error" 1 "CombustionExists" 0 "NoCombustion" ;
VAL_ 2364544766 EngCyl8CombustionStatus 3 "NotAvailable" 2 "Error" 1 "CombustionExists" 0 "NoCombustion" ;
VAL_ 2364544766 EngCyl7CombustionStatus 3 "NotAvailable" 2 "Error" 1 "CombustionExists" 0 "NoCombustion" ;
VAL_ 2364544766 EngCyl6CombustionStatus 3 "NotAvailable" 2 "Error" 1 "CombustionExists" 0 "NoCombustion" ;
VAL_ 2364544766 EngCyl5CombustionStatus 1 "CombustionExists" 0 "NoCombustion" 3 "NotAvailable" 2 "Error" ;
VAL_ 2364544766 EngCyl4CombustionStatus 3 "NotAvailable" 2 "Error" 1 "CombustionExists" 0 "NoCombustion" ;
VAL_ 2364544766 EngCyl3CombustionStatus 3 "NotAvailable" 2 "Error" 1 "CombustionExists" 0 "NoCombustion" ;
VAL_ 2364544766 EngCyl2CombustionStatus 3 "NotAvailable" 2 "Error" 1 "CombustionExists" 0 "NoCombustion" ;
VAL_ 2364544766 EngCyl24CombustionStatus 3 "NotAvailable" 2 "Error" 1 "CombustionExists" 0 "NoCombustion" ;
VAL_ 2364544766 EngCyl23CombustionStatus 3 "NotAvailable" 2 "Error" 1 "CombustionExists" 0 "NoCombustion" ;
VAL_ 2364544766 EngCyl22CombustionStatus 3 "NotAvailable" 2 "Error" 1 "CombustionExists" 0 "NoCombustion" ;
VAL_ 2364544766 EngCyl21CombustionStatus 3 "NotAvailable" 2 "Error" 1 "CombustionExists" 0 "NoCombustion" ;
VAL_ 2364544766 EngCyl20CombustionStatus 3 "NotAvailable" 2 "Error" 1 "CombustionExists" 0 "NoCombustion" ;
VAL_ 2364544766 EngCyl1CombustionStatus 3 "NotAvailable" 2 "Error" 1 "CombustionExists" 0 "NoCombustion" ;
VAL_ 2364544766 EngCyl19CombustionStatus 3 "NotAvailable" 2 "Error" 1 "CombustionExists" 0 "NoCombustion" ;
VAL_ 2364544766 EngCyl18CombustionStatus 3 "NotAvailable" 2 "Error" 1 "CombustionExists" 0 "NoCombustion" ;
VAL_ 2364544766 EngCyl17CombustionStatus 3 "NotAvailable" 2 "Error" 1 "CombustionExists" 0 "NoCombustion" ;
VAL_ 2364544766 EngCyl16CombustionStatus 3 "NotAvailable" 2 "Error" 1 "CombustionExists" 0 "NoCombustion" ;
VAL_ 2364544766 EngCyl15CombustionStatus 3 "NotAvailable" 2 "Error" 1 "CombustionExists" 0 "NoCombustion" ;
VAL_ 2364544766 EngCyl14CombustionStatus 3 "NotAvailable" 2 "Error" 1 "CombustionExists" 0 "NoCombustion" ;
VAL_ 2364544766 EngCyl13CombustionStatus 3 "NotAvailable" 2 "Error" 1 "CombustionExists" 0 "NoCombustion" ;
VAL_ 2364544766 EngCyl12CombustionStatus 3 "NotAvailable" 2 "Error" 1 "CombustionExists" 0 "NoCombustion" ;
VAL_ 2364544766 EngCyl11CombustionStatus 3 "NotAvailable" 2 "Error" 1 "CombustionExists" 0 "NoCombustion" ;
VAL_ 2364544766 EngCyl10CombustionStatus 3 "NotAvailable" 2 "Error" 1 "CombustionExists" 0 "NoCombustion" ;
VAL_ 2364544510 RqGenOverallPowerFactorLagging 3 "NotAvailable" 2 "Error" 1 "Lagging" 0 "Leading" ;
VAL_ 2364544254 RlativeBladeHeightFigureOfMerit 3 "RelativeBladeHeightNotAvailable" 2 "RelativeBladeHeightFailed" 1 "RltvBldHghtDgrddDtIsSspctDTEnvr" 0 "RltvBldHghtFllyFnctnlDtIsWthnSn" ;
VAL_ 2364544254 BladeRotationAngleFigureOfMerit 3 "BladeRotationAngleNotAvailable" 2 "BldRttnAnglFldRllSnsrFldTOprtCr" 1 "BldRttnAnglDgrddDtIsSspctDTEnvr" 0 "BldRttnAnglFllyFnctnlDtIsWthnSn" ;
VAL_ 2349006590 VehicleType 1 "Dolly axle" 0 "Towing or towed vehicle" ;
VAL_ 2349006590 BrakeLightSwitch 1 "Switch on" 0 "Switch off" ;
VAL_ 2349006590 ASREngineControlActive 3 "NotAvailable" 2 "Reserved" 1 "ASREngineControlActive" 0 "ASREngnCntrlPassiveButInstalled" ;
VAL_ 2349006590 ASRBreakControlActive 1 "Active" 0 "Passive, but installed" ;
VAL_ 2349006590 VehicleRetarderCtrlActive 1 "Active" 0 "Passive" ;
VAL_ 2349006590 VehicleABSActive 1 "Active" 0 "Passiv, but installed" ;
VAL_ 2566834686 PneumaticControlLine 1 "Towing veh with pn ctrl line" 0 "Towing veh without pn ctrl line" ;
VAL_ 2566834686 ABSOffroadRequest 1 "ABS off-road switch on" 0 "ABS off-road switch off" ;
VAL_ 2566834686 TwoElCircuitsBrakeDemand 1 "Two el. circuit brake available" 0 "One el. circuit brake available" ;
VAL_ 2566834686 VehicleRetarderCtrlActive 1 "Active" 0 "Passive" ;
VAL_ 2550398718 SupplyLineBrakingRequest 1 "Supply line braking request" 0 "No supply line braking request" ;
VAL_ 2550398718 VDCActive 1 "Active" 0 "Passive, but installed" ;
VAL_ 2550398718 AutomTowedVehBreakActive 1 "Active" 0 "Passive" ;
VAL_ 2550398718 VehicleServiceBrakeActive 1 "Active" 0 "Passive" ;
VAL_ 2550398718 VehicleRetarderCtrlActive 1 "Active" 0 "Passive" ;
VAL_ 2550398718 VehicleABSActive 1 "Active" 0 "Passiv, but installed" ;
VAL_ 2566833406 SupplyLineBrakingRequest 1 "Supply line braking request" 0 "No supply line braking request" ;
VAL_ 2566833406 LoadingRampApproachAssist 1 "Assistance active" 0 "Assistance not active" ;
VAL_ 2566833406 SpringBrakeEngaged 1 "Vehicle spring brake is engaged" 0 "Vehicle spring brake is released" ;
VAL_ 2566833406 ElectrLoadPropFunc 1 "Vehicle with el. load proportion" 0 "Vehicle without el. load proport" ;
VAL_ 2566833406 SpringBrakeInstalled 1 "Vehicle with spring brakes" 0 "Vehicle without spring brakes" ;
VAL_ 2566833406 VehicleType 1 "Dolly axle" 0 "Towing or towed vehicle" ;
VAL_ 2566833406 ElecSupplyOfNonBrakingSys 1 "Supply switched on" 0 "Supply switched off" ;
VAL_ 2566833406 AmberWarningSignalReq 1 "Towed vehicle failure indicated" 0 "No towed vehicle failure indicat" ;
VAL_ 2566833406 RedWarningSignalRequest 1 "Towed vehicle failure indicated" 0 "No towed vehicle failure indicat" ;
VAL_ 2566833406 VehicleElectrSupplySuff 1 "Vehicle el. supply sufficient" 0 "Vehicle el. supply insufficient" ;
VAL_ 2566833406 AutomTowedVehBreakActive 1 "Active" 0 "Passive" ;
VAL_ 2566833406 VehicleServiceBrakeActive 1 "Active" 0 "Passive" ;
VAL_ 2566833406 VehicleRetarderCtrlActive 1 "Active" 0 "Passive" ;
VAL_ 2566833406 VehicleABSActive 1 "Active" 0 "Passiv, but installed" ;
VAL_ 2365507326 TyreWheelIdentTemp2 15 "Axle position 15" 14 "Axle position 14" 13 "Axle position 13" 12 "Axle position 12" 11 "Axle position 11" 10 "Axle position 10" 9 "Axle position 9" 8 "Axle position 8" 7 "Axle position 7" 6 "Axle position 6" 5 "Axle position 5" 4 "Axle position 4" 3 "Axle position 3" 2 "Axle position 2" 1 "Axle position 1" 0 "Axle position not identified" ;
VAL_ 2365507326 TyreWheelIdentTemp1 15 "Wheel position 15" 14 "Wheel position 14" 13 "Wheel position 13" 12 "Wheel position 12" 11 "Wheel position 11" 10 "Wheel position 10" 9 "Wheel position 9" 8 "Wheel position 8" 7 "Wheel position 7" 6 "Wheel position 6" 5 "Wheel position 5" 4 "Wheel position 4" 3 "Wheel position 3" 2 "Wheel position 2" 1 "Wheel position 1" 0 "Wheel position not identified" ;
VAL_ 2365507326 TyreWheelIdentPressure2 15 "Axle position 15" 14 "Axle position 14" 13 "Axle position 13" 12 "Axle position 12" 11 "Axle position 11" 10 "Axle position 10" 9 "Axle position 9" 8 "Axle position 8" 7 "Axle position 7" 6 "Axle position 6" 5 "Axle position 5" 4 "Axle position 4" 3 "Axle position 3" 2 "Axle position 2" 1 "Axle position 1" 0 "Axle position not identified" ;
VAL_ 2365507326 TyreWheelIdentPressure1 15 "Wheel position 15" 14 "Wheel position 14" 13 "Wheel position 13" 12 "Wheel position 12" 11 "Wheel position 11" 10 "Wheel position 10" 9 "Wheel position 9" 8 "Wheel position 8" 7 "Wheel position 7" 6 "Wheel position 6" 5 "Wheel position 5" 4 "Wheel position 4" 3 "Wheel position 3" 2 "Wheel position 2" 1 "Wheel position 1" 0 "Wheel position not identified" ;
VAL_ 2365507326 TyreWheelIdentLining2 15 "Axle position 15" 14 "Axle position 14" 13 "Axle position 13" 12 "Axle position 12" 11 "Axle position 11" 10 "Axle position 10" 9 "Axle position 9" 8 "Axle position 8" 7 "Axle position 7" 6 "Axle position 6" 5 "Axle position 5" 4 "Axle position 4" 3 "Axle position 3" 2 "Axle position 2" 1 "Axle position 1" 0 "Axle position not identified" ;
VAL_ 2365507326 TyreWheelIdentLining1 15 "Wheel position 15" 14 "Wheel position 14" 13 "Wheel position 13" 12 "Wheel position 12" 11 "Wheel position 11" 10 "Wheel position 10" 9 "Wheel position 9" 8 "Wheel position 8" 7 "Wheel position 7" 6 "Wheel position 6" 5 "Wheel position 5" 4 "Wheel position 4" 3 "Wheel position 3" 2 "Wheel position 2" 1 "Wheel position 1" 0 "Wheel position not identified" ;
VAL_ 2365507326 VehiclePneumSupplySuff 1 "Pneumatic supply sufficient" 0 "Pneumatic supply insufficient" ;
VAL_ 2365507326 BrakeTemperatureStatus 1 "Brake temperature normal" 0 "Brake temperature out of range" ;
VAL_ 2365507326 BrakeLiningSufficient 1 "Brake linings sufficient" 0 "Brake linings insufficient" ;
VAL_ 2365507326 TyrePressureSufficient 1 "Tyre pressure sufficient" 0 "Tyre pressure insufficient" ;
VAL_ 2565013246 ODDRequest 3 "Take no action" 1 "ODD on" 0 "ODD off" ;
VAL_ 2565013246 AntiTheftDeviceReq 3 "Take no action" 1 "Anti-theft device on" 0 "Anti-theft device off" ;
VAL_ 2565013246 VehicleType 1 "Dolly axle" 0 "Towing or towed vehicle" ;
VAL_ 2365480958 EngineTorqueMode 15 "Not available" 11 "Remote accelerator" 10 "Braking system" 9 "High speed governor" 8 "Torque limiting" 7 "ABS control" 6 "Transmission control" 5 "ASR control" 4 "Road speed governor" 3 "PTO governor" 2 "Cruise control" 1 "Accelerator pedal/operator selec" 0 "Low idle governor/no request (de" ;
VAL_ 2365480958 EngineRunning 1 "Engine running" 0 "Engine not running" ;
VAL_ 2365480958 EngineControlAllowed 1 "Engine control allowed" 0 "Engine control not allowed" ;
VAL_ 2566808062 ClutchIndptdPTOFeedback 1 "Engaged" 0 "Not engaged" ;
VAL_ 2566808062 AccelPedalLowIdleSwitch 1 "In low idle condition" 0 "Not in low idle condition" ;
VAL_ 2566808062 StarterActive 1 "Starter active" 0 "Starter not active" ;
VAL_ 2566808062 TorqueConvtOilTempWarning 2 "Warning" 1 "Prewarning" 0 "No warning" ;
VAL_ 2566808062 PTOControlAllowed 1 "PTO control allowed" 0 "PTO control not allowed" ;
VAL_ 2566808062 SecEngineMtdPTOFeedback 1 "Limits activated" 0 "Limits not activated" ;
VAL_ 2566808062 FirstEngineMtdPTOFeedback 1 "Limits activated" 0 "Limits not activated" ;
VAL_ 2566808062 SecClutchDptdPTOFeedback 1 "Engaged" 0 "Not engaged" ;
VAL_ 2566808062 FirstClutchDpdtPTOFeedback 1 "Engaged" 0 "Not engaged" ;
